VERSION ""

NS_ :

BS_:

BU_: DSAU vHS_M SHVU_RR DPSS AMP ICC RLPSM APSM RWPC RRHV RRPSM CGW_CCU APSS ATS RLHV FPM RDC PSM ASAU

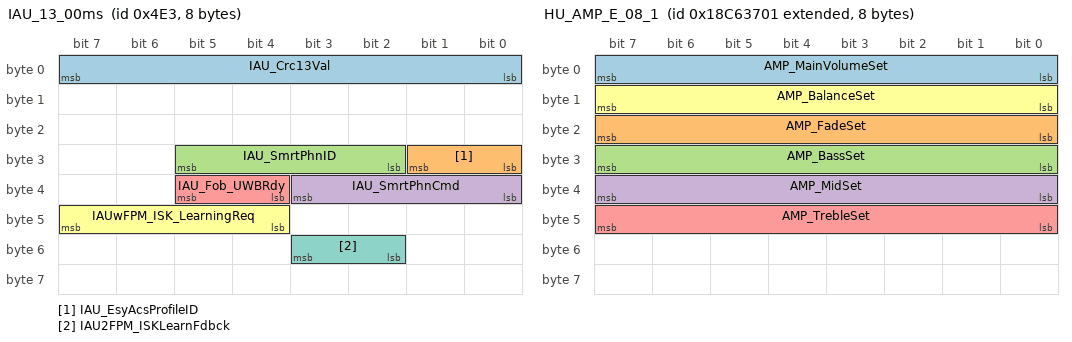
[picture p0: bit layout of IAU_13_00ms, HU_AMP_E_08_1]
BO_ 1251 IAU_13_00ms: 8 CGW_CCU
 SG_ IAU_Crc13Val : 0|8@1+ (1,0) [0|0] ""  Vector__XXX
 SG_ IAU_EsyAcsProfileID : 24|2@1+ (1,0) [0|0] ""  PSM
 SG_ IAU_SmrtPhnID : 26|4@1+ (1,0) [0|0] ""  Vector__XXX
 SG_ IAU_SmrtPhnCmd : 32|4@1+ (1,0) [0|0] ""  Vector__XXX
 SG_ IAU_Fob_UWBRdy : 36|2@1+ (1,0) [0|0] ""  Vector__XXX
 SG_ IAUwFPM_ISK_LearningReq : 44|4@1+ (1,0) [0|0] ""  FPM
 SG_ IAU2FPM_ISKLearnFdbck : 50|2@1+ (1,0) [0|0] ""  FPM

BO_ 2563127041 HU_AMP_E_08_1: 8 CGW_CCU
 SG_ AMP_MainVolumeSet : 0|8@1+ (1,0) [0|0] ""  AMP
 SG_ AMP_FadeSet : 16|8@1+ (1,0) [0|0] ""  AMP
 SG_ AMP_BassSet : 24|8@1+ (1,0) [0|0] ""  AMP
 SG_ AMP_MidSet : 32|8@1+ (1,0) [0|0] ""  AMP
 SG_ AMP_TrebleSet : 40|8@1+ (1,0) [0|0] ""  AMP
 SG_ AMP_BalanceSet : 8|8@1+ (1,0) [0|0] ""  AMP

BO_ 2567325441 HU_AMP_PE_01_1: 8 CGW_CCU
 SG_ AMP_ADASVolumeStep : 0|4@1+ (1,0) [0|0] ""  AMP
 SG_ AMP_ADASVolumeFbk : 4|4@1+ (1,0) [0|0] ""  AMP

BO_ 2298626561 HU_APSU_PE_03_1: 8 CGW_CCU
 SG_ C_RRLegSupFwdSw_HU : 0|2@1+ (1,0) [0|0] ""  RRPSM
 SG_ C_RRHrestDnSw_HU : 10|2@1+ (1,0) [0|0] ""  RRPSM
 SG_ C_RRHrestFwdSw_HU : 12|2@1+ (1,0) [0|0] ""  RRPSM
 SG_ C_RRHrestBwdSw_HU : 14|2@1+ (1,0) [0|0] ""  RRPSM
 SG_ C_RRLumbarUpSw_HU : 16|2@1+ (1,0) [0|0] ""  RLPSM
 SG_ C_RRLumbarMidSw_HU : 18|2@1+ (1,0) [0|0] ""  RLPSM
 SG_ C_RRLegSupBwdSw_HU : 2|2@1+ (1,0) [0|0] ""  RRPSM
 SG_ C_RRLumbarLowSw_HU : 20|2@1+ (1,0) [0|0] ""  RLPSM
 SG_ C_RRLumbarDefSw_HU : 22|2@1+ (1,0) [0|0] ""  RLPSM
 SG_ C_RRBolsterInfSw_HU : 24|2@1+ (1,0) [0|0] ""  RLPSM
 SG_ C_RRLegSupUpSw_HU : 4|2@1+ (1,0) [0|0] ""  RRPSM
 SG_ C_RROneTchNValueSet : 40|3@1+ (1,0) [0|0] ""  RLPSM,RRPSM,ATS
 SG_ C_RLOneTchNValueSet : 43|3@1+ (1,0) [0|0] ""  RLPSM,RRPSM,ATS
 SG_ C_RRBolsterDefSw_HU : 46|2@1+ (1,0) [0|0] ""  RLPSM
 SG_ C_RLRSEUpSw_HU : 54|2@1+ (1,0) [0|0] ""  PSM
 SG_ C_RLRSEDnSw_HU : 56|2@1+ (1,0) [0|0] ""  PSM
 SG_ C_RRRSEUpSw_HU : 58|2@1+ (1,0) [0|0] ""  APSM
 SG_ C_RRLegSupDnSw_HU : 6|2@1+ (1,0) [0|0] ""  RRPSM
 SG_ C_RRRSEDnSw_HU : 60|2@1+ (1,0) [0|0] ""  APSM
 SG_ C_RRHrestUpSw_HU : 8|2@1+ (1,0) [0|0] ""  RRPSM

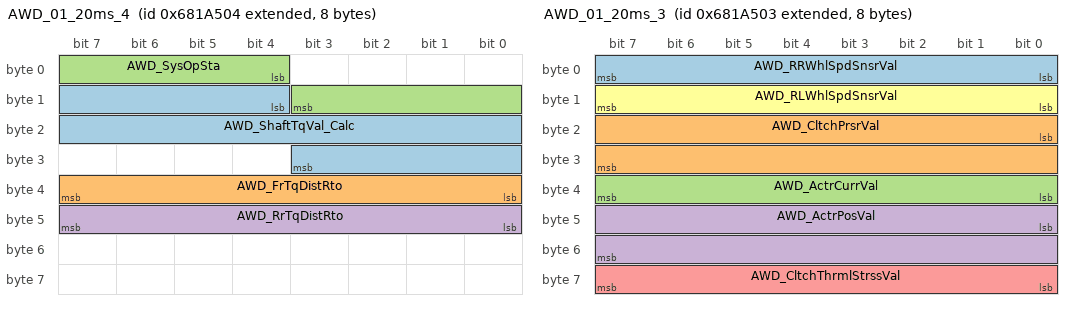
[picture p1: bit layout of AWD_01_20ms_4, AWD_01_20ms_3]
BO_ 2256643332 AWD_01_20ms_4: 8 CGW_CCU
 SG_ AWD_ShaftTqVal_Calc : 12|16@1+ (1,0) [0|0] "Nm"  Vector__XXX
 SG_ AWD_FrTqDistRto : 32|8@1+ (1,0) [0|0] "%"  Vector__XXX
 SG_ AWD_SysOpSta : 4|8@1+ (1,0) [0|0] ""  Vector__XXX
 SG_ AWD_RrTqDistRto : 40|8@1+ (1,0) [0|0] "%"  Vector__XXX

BO_ 2256643331 AWD_01_20ms_3: 8 CGW_CCU
 SG_ AWD_RRWhlSpdSnsrVal : 0|8@1+ (1,0) [0|0] "km/h"  Vector__XXX
 SG_ AWD_CltchPrsrVal : 16|16@1+ (0.0625,-50) [0|0] "Bar"  Vector__XXX
 SG_ AWD_ActrCurrVal : 32|8@1+ (0.390625,0) [0|0] "A"  Vector__XXX
 SG_ AWD_ActrPosVal : 40|16@1+ (0.015625,0) [0|0] "Deg"  Vector__XXX
 SG_ AWD_CltchThrmlStrssVal : 56|8@1+ (1,0) [0|0] "%"  Vector__XXX
 SG_ AWD_RLWhlSpdSnsrVal : 8|8@1+ (1,0) [0|0] "km/h"  Vector__XXX

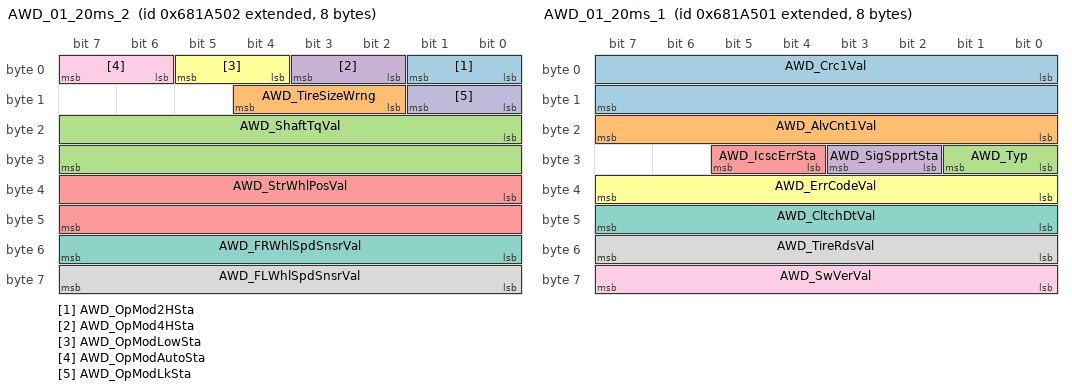
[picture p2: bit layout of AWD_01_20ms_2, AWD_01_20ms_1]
BO_ 2256643330 AWD_01_20ms_2: 8 CGW_CCU
 SG_ AWD_OpMod2HSta : 0|2@1+ (1,0) [0|0] ""  Vector__XXX
 SG_ AWD_TireSizeWrng : 10|3@1+ (1,0) [0|0] ""  Vector__XXX
 SG_ AWD_ShaftTqVal : 16|16@1+ (1,0) [0|0] "Nm"  Vector__XXX
 SG_ AWD_OpMod4HSta : 2|2@1+ (1,0) [0|0] ""  Vector__XXX
 SG_ AWD_StrWhlPosVal : 32|16@1+ (1,-600) [0|0] "Deg"  Vector__XXX
 SG_ AWD_OpModLowSta : 4|2@1+ (1,0) [0|0] ""  Vector__XXX
 SG_ AWD_FRWhlSpdSnsrVal : 48|8@1+ (1,0) [0|0] "km/h"  Vector__XXX
 SG_ AWD_FLWhlSpdSnsrVal : 56|8@1+ (1,0) [0|0] "km/h"  Vector__XXX
 SG_ AWD_OpModAutoSta : 6|2@1+ (1,0) [0|0] ""  Vector__XXX
 SG_ AWD_OpModLkSta : 8|2@1+ (1,0) [0|0] ""  Vector__XXX

BO_ 2256643329 AWD_01_20ms_1: 8 CGW_CCU
 SG_ AWD_Crc1Val : 0|16@1+ (1,0) [0|0] ""  Vector__XXX
 SG_ AWD_AlvCnt1Val : 16|8@1+ (1,0) [0|0] ""  Vector__XXX
 SG_ AWD_Typ : 24|2@1+ (1,0) [0|0] ""  AMP
 SG_ AWD_SigSpprtSta : 26|2@1+ (1,0) [0|0] ""  Vector__XXX
 SG_ AWD_IcscErrSta : 28|2@1+ (1,0) [0|0] ""  Vector__XXX
 SG_ AWD_ErrCodeVal : 32|8@1+ (1,0) [0|0] ""  Vector__XXX
 SG_ AWD_CltchDtVal : 40|8@1+ (1,0) [0|0] "%"  Vector__XXX
 SG_ AWD_TireRdsVal : 48|8@1+ (1,200) [0|0] "mm"  Vector__XXX
 SG_ AWD_SwVerVal : 56|8@1+ (1,0) [0|0] ""  Vector__XXX

BO_ 2458168321 HU_USM_E_05_1: 8 CGW_CCU
 SG_ C_HCIMSWeightNValueSet : 0|4@1+ (1,0) [0|0] ""  PSM
 SG_ C_HCIMSSitHeightNValueSet : 12|4@1+ (1,0) [0|0] ""  PSM
 SG_ CF_AVN_RRSeatAUTOHEATNValueSet : 16|2@1+ (1,0) [0|0] ""  Vector__XXX
 SG_ CF_AVN_RLSeatAUTOHEATNValueSet : 18|2@1+ (1,0) [0|0] ""  Vector__XXX
 SG_ CF_AVN_AstAUTOHEATNValueSet : 20|2@1+ (1,0) [0|0] ""  Vector__XXX
 SG_ CF_Avn_DrvAUTOHEATNValueSet : 22|2@1+ (1,0) [0|0] ""  Vector__XXX
 SG_ CF_AVN_BodySpprtSet : 24|2@1+ (1,0) [0|0] ""  DPSS,DSAU
 SG_ CF_AVN_EASMAUTOHEATNValueSet : 26|2@1+ (1,0) [0|0] ""  Vector__XXX
 SG_ CF_AVN_EDSMAUTOHEATNValueSet : 28|2@1+ (1,0) [0|0] ""  Vector__XXX
 SG_ CF_AVN_AntiDRWSYSet : 30|2@1+ (1,0) [0|0] ""  Vector__XXX
 SG_ CF_AVN_AirSptTimeNValueSet : 33|3@1+ (1,0) [0|0] ""  Vector__XXX
 SG_ CF_AVN_AirSptStrNValue : 36|2@1+ (1,0) [0|0] ""  Vector__XXX
 SG_ CF_AVN_SeatDrvModNValueSet : 38|2@1+ (1,0) [0|0] ""  DPSS,DSAU
 SG_ C_HCIMSHeightNvalueSet : 4|4@1+ (1,0) [0|0] ""  PSM
 SG_ C_SLB_SmartCtrl_NValue : 40|2@1+ (1,0) [0|0] ""  Vector__XXX
 SG_ CF_AVN_AntiDRWSYIntvlSet : 42|3@1+ (1,0) [0|0] ""  Vector__XXX
 SG_ CF_AVN_CushSoftNValueSet : 45|3@1+ (1,0) [0|0] ""  Vector__XXX
 SG_ C_SmrtSldngDrNValueSet : 48|3@1+ (1,0) [0|0] ""  Vector__XXX
 SG_ CF_AVN_TurboPressureUnit : 51|3@1+ (1,0) [0|0] ""  Vector__XXX
 SG_ CF_AVN_CluTorqueUnit : 54|2@1+ (1,0) [0|0] ""  Vector__XXX
 SG_ AVN_Usm_CluThemeAutoSet : 56|2@1+ (1,0) [0|0] ""  Vector__XXX
 SG_ AVN_Usm_CluThemeSta : 58|3@1+ (1,0) [0|0] ""  Vector__XXX
 SG_ AVN_Usm_CluFuelEconomySet : 61|3@1+ (1,0) [0|0] ""  Vector__XXX
 SG_ CF_AVN_HCIMSButtonCommand : 8|4@1+ (1,0) [0|0] ""  PSM

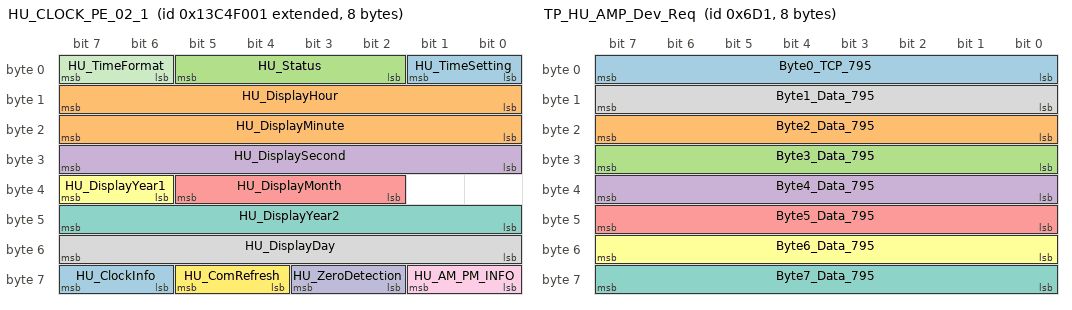
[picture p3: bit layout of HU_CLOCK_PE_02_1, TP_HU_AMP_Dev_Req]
BO_ 2479157249 HU_CLOCK_PE_02_1: 8 CGW_CCU
 SG_ HU_TimeSetting : 0|2@1+ (1,0) [0|0] ""  ATS
 SG_ HU_DisplayMinute : 16|8@1+ (1,0) [0|0] ""  ATS
 SG_ HU_Status : 2|4@1+ (1,0) [0|0] ""  ATS
 SG_ HU_DisplaySecond : 24|8@1+ (1,0) [0|0] ""  ATS
 SG_ HU_DisplayMonth : 34|4@1+ (1,0) [0|0] ""  ATS
 SG_ HU_DisplayYear1 : 38|2@1+ (1,0) [0|0] ""  ATS
 SG_ HU_DisplayYear2 : 40|8@1+ (1,0) [0|0] ""  ATS
 SG_ HU_DisplayDay : 48|8@1+ (1,0) [0|0] ""  ATS
 SG_ HU_AM_PM_INFO : 56|2@1+ (1,0) [0|0] ""  ATS
 SG_ HU_ZeroDetection : 58|2@1+ (1,0) [0|0] ""  ATS
 SG_ HU_TimeFormat : 6|2@1+ (1,0) [0|0] ""  ATS
 SG_ HU_ComRefresh : 60|2@1+ (1,0) [0|0] ""  ATS
 SG_ HU_ClockInfo : 62|2@1+ (1,0) [0|0] ""  ATS
 SG_ HU_DisplayHour : 8|8@1+ (1,0) [0|0] ""  ATS

BO_ 1745 TP_HU_AMP_Dev_Req: 8 CGW_CCU
 SG_ Byte0_TCP_795 : 0|8@1+ (1,0) [0|0] ""  AMP
 SG_ Byte2_Data_795 : 16|8@1+ (1,0) [0|0] ""  AMP
 SG_ Byte3_Data_795 : 24|8@1+ (1,0) [0|0] ""  AMP
 SG_ Byte4_Data_795 : 32|8@1+ (1,0) [0|0] ""  AMP
 SG_ Byte5_Data_795 : 40|8@1+ (1,0) [0|0] ""  AMP
 SG_ Byte6_Data_795 : 48|8@1+ (1,0) [0|0] ""  AMP
 SG_ Byte7_Data_795 : 56|8@1+ (1,0) [0|0] ""  AMP
 SG_ Byte1_Data_795 : 8|8@1+ (1,0) [0|0] ""  AMP

BO_ 191 RL_SHVU_03_200ms: 8 SHVU_RR
 SG_ RL_SHVU_DTCdisplay : 0|8@1+ (1,0) [0|0] ""  ATS
 SG_ RL_SHVU_DiagMode : 8|2@1+ (1,0) [0|0] ""  ATS

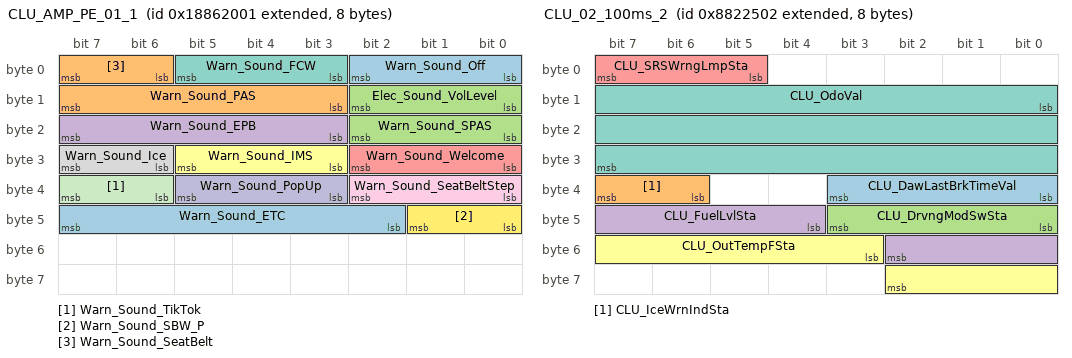
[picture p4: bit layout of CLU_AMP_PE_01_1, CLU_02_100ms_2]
BO_ 2558926849 CLU_AMP_PE_01_1: 8 CGW_CCU
 SG_ Warn_Sound_Off : 0|3@1+ (1,0) [0|0] ""  AMP
 SG_ Warn_Sound_PAS : 11|5@1+ (1,0) [0|0] ""  AMP
 SG_ Warn_Sound_SPAS : 16|3@1+ (1,0) [0|0] ""  AMP
 SG_ Warn_Sound_EPB : 19|5@1+ (1,0) [0|0] ""  AMP
 SG_ Warn_Sound_Welcome : 24|3@1+ (1,0) [0|0] ""  AMP
 SG_ Warn_Sound_IMS : 27|3@1+ (1,0) [0|0] ""  AMP
 SG_ Warn_Sound_FCW : 3|3@1+ (1,0) [0|0] ""  AMP
 SG_ Warn_Sound_Ice : 30|2@1+ (1,0) [0|0] ""  AMP
 SG_ Warn_Sound_SeatBeltStep : 32|3@1+ (1,0) [0|7] ""  AMP
 SG_ Warn_Sound_PopUp : 35|3@1+ (1,0) [0|0] ""  AMP
 SG_ Warn_Sound_TikTok : 38|2@1+ (1,0) [0|0] ""  AMP
 SG_ Warn_Sound_SBW_P : 40|2@1+ (1,0) [0|0] ""  AMP
 SG_ Warn_Sound_ETC : 42|6@1+ (1,0) [0|0] ""  AMP
 SG_ Warn_Sound_SeatBelt : 6|2@1+ (1,0) [0|0] ""  AMP
 SG_ Elec_Sound_VolLevel : 8|3@1+ (1,0) [0|0] ""  AMP

BO_ 2290230530 CLU_02_100ms_2: 8 CGW_CCU
 SG_ CLU_DawLastBrkTimeVal : 32|4@1+ (1,0) [0|0] ""  Vector__XXX
 SG_ CLU_IceWrnIndSta : 38|2@1+ (1,0) [0|0] ""  Vector__XXX
 SG_ CLU_DrvngModSwSta : 40|4@1+ (1,0) [0|0] ""  Vector__XXX
 SG_ CLU_FuelLvlSta : 44|7@1+ (1,0) [0|0] "%"  Vector__XXX
 SG_ CLU_SRSWrngLmpSta : 5|3@1+ (1,0) [0|0] ""  Vector__XXX
 SG_ CLU_OutTempFSta : 51|8@1+ (1,-40) [0|0] ""  ATS
 SG_ CLU_OdoVal : 8|24@1+ (0.1,0) [0|0] "km"  Vector__XXX

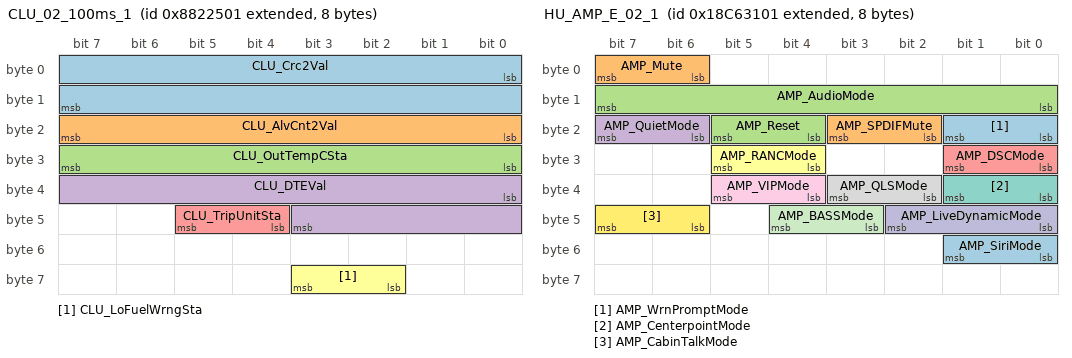
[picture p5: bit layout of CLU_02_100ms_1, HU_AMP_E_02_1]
BO_ 2290230529 CLU_02_100ms_1: 8 CGW_CCU
 SG_ CLU_Crc2Val : 0|16@1+ (1,0) [0|0] ""  Vector__XXX
 SG_ CLU_AlvCnt2Val : 16|8@1+ (1,0) [0|0] ""  Vector__XXX
 SG_ CLU_OutTempCSta : 24|8@1+ (1,-40) [0|0] ""  ATS
 SG_ CLU_DTEVal : 32|12@1+ (1,0) [0|0] ""  Vector__XXX
 SG_ CLU_TripUnitSta : 44|2@1+ (1,0) [0|0] ""  Vector__XXX
 SG_ CLU_LoFuelWrngSta : 58|2@1+ (1,0) [0|0] ""  Vector__XXX

BO_ 1153 IAU_39_00ms: 8 CGW_CCU
 SG_ IAU2FPM_EncryptedData2 : 0|64@1+ (1,0) [0|0] ""  FPM

BO_ 2323817473 HU_APSU_E_01_1: 8 CGW_CCU
 SG_ C_DrAirSptNValueSet_EC : 0|2@1+ (1,0) [0|0] ""  DSAU
 SG_ C_DrCushSoftNValueSet_EC : 11|3@1+ (1,0) [0|0] ""  DSAU
 SG_ C_AstAirSptNValueSet_EC : 14|2@1+ (1,0) [0|0] ""  ASAU
 SG_ C_DrBackSoftNValueSet_EC : 16|3@1+ (1,0) [0|0] ""  DSAU
 SG_ C_AstAirSptModeNValueSet_EC : 19|3@1+ (1,0) [0|0] ""  ASAU
 SG_ C_DrAirSptModeNValueSet_EC : 2|3@1+ (1,0) [0|0] ""  DSAU
 SG_ C_RLAirSptNValueSet_EC : 22|2@1+ (1,0) [0|0] ""  RLPSM,ATS
 SG_ C_AstAirSptStrNValueSet_EC : 24|3@1+ (1,0) [0|0] ""  ASAU
 SG_ C_AstAirSptTimeNValueSet_EC : 27|3@1+ (1,0) [0|0] ""  ASAU
 SG_ C_RRAirSptNValueSet_EC : 30|2@1+ (1,0) [0|0] ""  RLPSM,ATS
 SG_ C_AstCushSoftNValueSet_EC : 32|3@1+ (1,0) [0|0] ""  ASAU
 SG_ C_AstBackSoftNValueSet_EC : 35|3@1+ (1,0) [0|0] ""  ASAU
 SG_ C_RRFootAirSptNValueSet_EC : 38|2@1+ (1,0) [0|0] ""  RLPSM,ATS,ASAU
 SG_ C_RLAirSptModeNValueSet_EC : 43|3@1+ (1,0) [0|0] ""  RLPSM,ATS
 SG_ C_RLSeatHtOperNValueSet_EC : 48|4@1+ (1,0) [0|0] ""  RLHV
 SG_ C_DrAirSptStrNValueSet_EC : 5|3@1+ (1,0) [0|0] ""  DSAU
 SG_ C_RRSeatHtOperNValueSet_EC : 52|4@1+ (1,0) [0|0] ""  RRHV
 SG_ C_RLAirSptStrNValueSet_EC : 56|3@1+ (1,0) [0|0] ""  RLPSM,ATS
 SG_ C_RLAirSptTimeNValueSet_EC : 59|3@1+ (1,0) [0|0] ""  RLPSM,ATS
 SG_ C_DrAirSptTimeNValueSet_EC : 8|3@1+ (1,0) [0|0] ""  DSAU

BO_ 1156 IAU_42_00ms: 8 CGW_CCU
 SG_ IAU2FPM_RndNum : 16|48@1+ (1,0) [0|0] ""  FPM

BO_ 2563125505 HU_AMP_E_02_1: 8 CGW_CCU
 SG_ AMP_WrnPromptMode : 16|2@1+ (1,0) [0|0] ""  AMP
 SG_ AMP_SPDIFMute : 18|2@1+ (1,0) [0|0] ""  AMP
 SG_ AMP_Reset : 20|2@1+ (1,0) [0|0] ""  AMP
 SG_ AMP_QuietMode : 22|2@1+ (1,0) [0|0] ""  AMP
 SG_ AMP_DSCMode : 24|2@1+ (1,0) [0|0] ""  AMP
 SG_ AMP_RANCMode : 28|2@1+ (1,0) [0|0] ""  AMP
 SG_ AMP_CenterpointMode : 32|2@1+ (1,0) [0|0] ""  AMP
 SG_ AMP_QLSMode : 34|2@1+ (1,0) [0|0] ""  AMP
 SG_ AMP_VIPMode : 36|2@1+ (1,0) [0|0] ""  AMP
 SG_ AMP_LiveDynamicMode : 40|3@1+ (1,0) [0|0] ""  Vector__XXX
 SG_ AMP_BASSMode : 43|2@1+ (1,0) [0|0] ""  Vector__XXX
 SG_ AMP_CabinTalkMode : 46|2@1+ (1,0) [0|0] ""  Vector__XXX
 SG_ AMP_SiriMode : 48|2@1+ (1,0) [0|0] ""  AMP
 SG_ AMP_Mute : 6|2@1+ (1,0) [0|0] ""  AMP
 SG_ AMP_AudioMode : 8|8@1+ (1,0) [0|0] ""  AMP

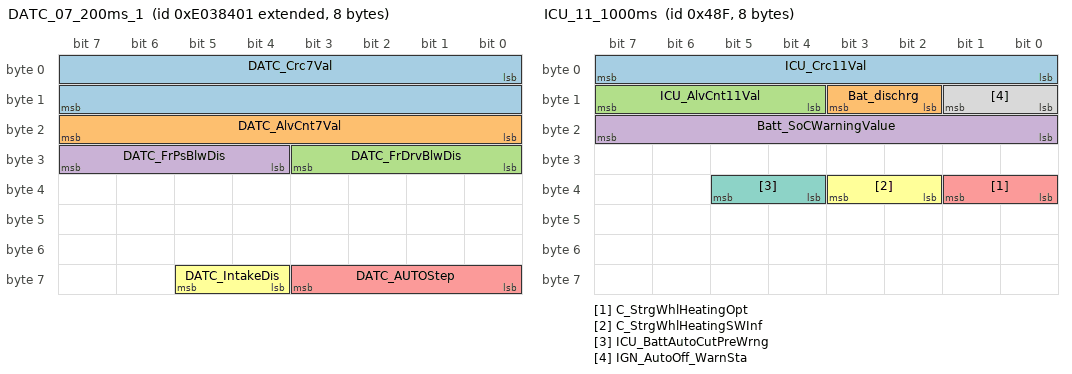
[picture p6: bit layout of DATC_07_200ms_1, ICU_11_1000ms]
BO_ 2382595073 DATC_07_200ms_1: 8 CGW_CCU
 SG_ DATC_Crc7Val : 0|16@1+ (1,0) [0|0] ""  Vector__XXX
 SG_ DATC_AlvCnt7Val : 16|8@1+ (1,0) [0|0] ""  Vector__XXX
 SG_ DATC_FrDrvBlwDis : 24|4@1+ (1,0) [0|0] ""  ATS
 SG_ DATC_FrPsBlwDis : 28|4@1+ (1,0) [0|0] ""  ATS
 SG_ DATC_AUTOStep : 56|4@1+ (1,0) [0|0] ""  Vector__XXX
 SG_ DATC_IntakeDis : 60|2@1+ (1,0) [0|0] ""  ATS

BO_ 1167 ICU_11_1000ms: 8 CGW_CCU
 SG_ ICU_Crc11Val : 0|8@1+ (1,0) [0|0] ""  vHS_M
 SG_ Bat_dischrg : 10|2@1+ (1,0) [0|0] ""  Vector__XXX
 SG_ ICU_AlvCnt11Val : 12|4@1+ (1,0) [0|0] ""  Vector__XXX
 SG_ Batt_SoCWarningValue : 16|8@1+ (1,0) [0|0] "%"  Vector__XXX
 SG_ C_StrgWhlHeatingOpt : 32|2@1+ (1,0) [0|0] ""  Vector__XXX
 SG_ C_StrgWhlHeatingSWInf : 34|2@1+ (1,0) [0|0] ""  Vector__XXX
 SG_ ICU_BattAutoCutPreWrng : 36|2@1+ (1,0) [0|0] ""  Vector__XXX
 SG_ IGN_AutoOff_WarnSta : 8|2@1+ (1,0) [0|0] ""  Vector__XXX

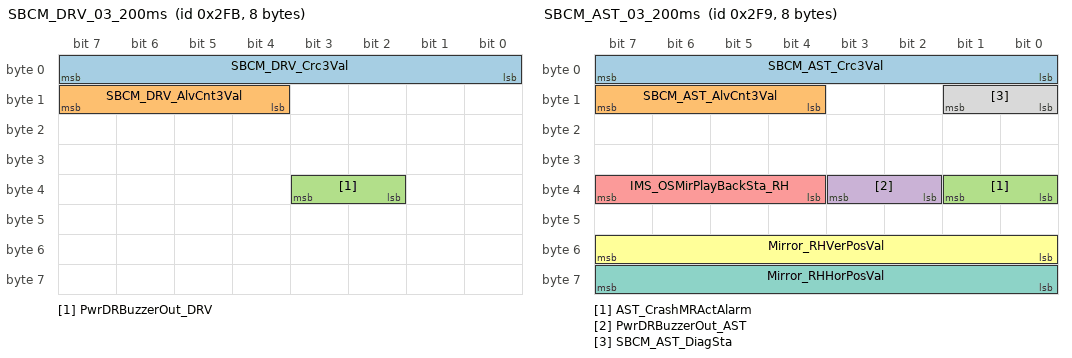
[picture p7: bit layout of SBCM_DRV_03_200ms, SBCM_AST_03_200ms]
BO_ 763 SBCM_DRV_03_200ms: 8 CGW_CCU
 SG_ SBCM_DRV_Crc3Val : 0|8@1+ (1,0) [0|0] ""  Vector__XXX
 SG_ SBCM_DRV_AlvCnt3Val : 12|4@1+ (1,0) [0|0] ""  Vector__XXX
 SG_ PwrDRBuzzerOut_DRV : 34|2@1+ (1,0) [0|0] ""  AMP

BO_ 760 SBCM_RR_02_200ms: 8 CGW_CCU
 SG_ RR_CrashMRActAlarm : 10|2@1+ (1,0) [0|0] ""  Vector__XXX
 SG_ PwrDRBuzzerOut_RR : 12|2@1+ (1,0) [0|0] ""  AMP

BO_ 761 SBCM_AST_03_200ms: 8 CGW_CCU
 SG_ SBCM_AST_Crc3Val : 0|8@1+ (1,0) [0|0] ""  Vector__XXX
 SG_ SBCM_AST_AlvCnt3Val : 12|4@1+ (1,0) [0|0] ""  Vector__XXX
 SG_ AST_CrashMRActAlarm : 32|2@1+ (1,0) [0|0] ""  Vector__XXX
 SG_ PwrDRBuzzerOut_AST : 34|2@1+ (1,0) [0|0] ""  AMP
 SG_ IMS_OSMirPlayBackSta_RH : 36|4@1+ (1,0) [0|0] ""  PSM
 SG_ Mirror_RHVerPosVal : 48|8@1+ (0.02,0) [0|0] "V"  Vector__XXX
 SG_ Mirror_RHHorPosVal : 56|8@1+ (0.02,0) [0|0] "V"  Vector__XXX
 SG_ SBCM_AST_DiagSta : 8|2@1+ (1,0) [0|0] ""  Vector__XXX

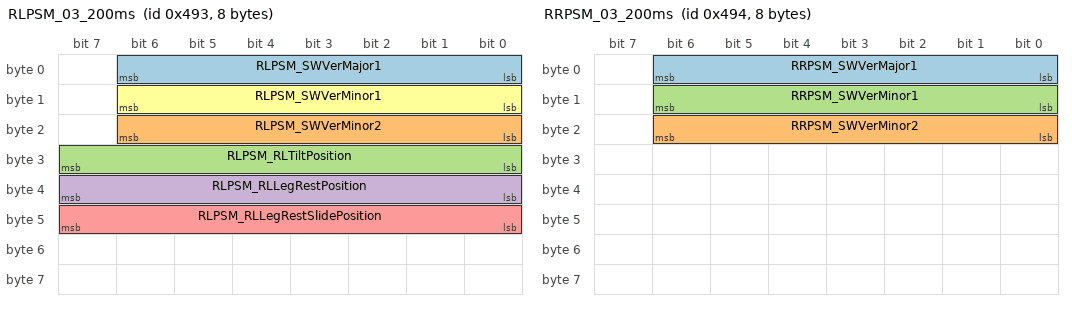
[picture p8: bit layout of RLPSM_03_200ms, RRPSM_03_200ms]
BO_ 1171 RLPSM_03_200ms: 8 RLPSM
 SG_ RLPSM_SWVerMajor1 : 0|7@1+ (1,0) [0|0] ""  CGW_CCU
 SG_ RLPSM_SWVerMinor2 : 16|7@1+ (1,0) [0|0] ""  CGW_CCU
 SG_ RLPSM_RLTiltPosition : 24|8@1+ (1,0) [0|0] ""  PSM
 SG_ RLPSM_RLLegRestPosition : 32|8@1+ (1,0) [0|0] ""  PSM
 SG_ RLPSM_RLLegRestSlidePosition : 40|8@1+ (1,0) [0|0] ""  PSM
 SG_ RLPSM_SWVerMinor1 : 8|7@1+ (1,0) [0|0] ""  CGW_CCU

BO_ 1172 RRPSM_03_200ms: 8 RRPSM
 SG_ RRPSM_SWVerMajor1 : 0|7@1+ (1,0) [0|0] ""  CGW_CCU
 SG_ RRPSM_SWVerMinor2 : 16|7@1+ (1,0) [0|0] ""  CGW_CCU
 SG_ RRPSM_SWVerMinor1 : 8|7@1+ (1,0) [0|0] ""  CGW_CCU

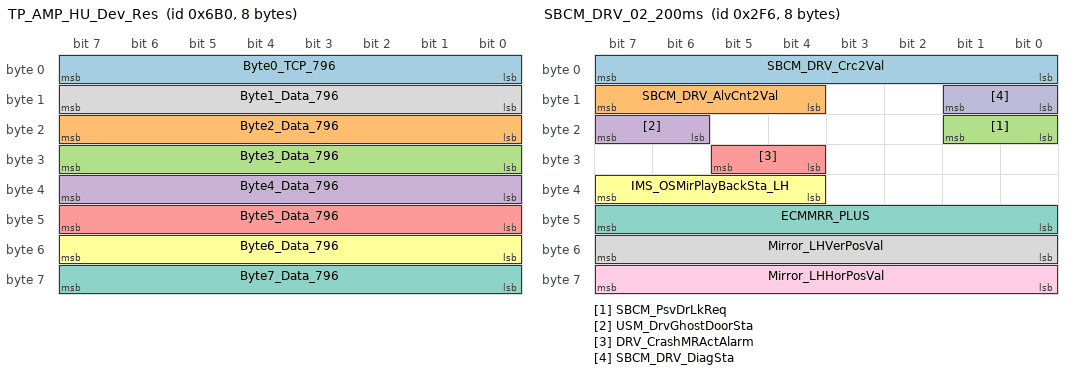
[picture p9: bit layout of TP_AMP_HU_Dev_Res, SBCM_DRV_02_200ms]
BO_ 1712 TP_AMP_HU_Dev_Res: 8 AMP
 SG_ Byte0_TCP_796 : 0|8@1+ (1,0) [0|0] ""  CGW_CCU
 SG_ Byte2_Data_796 : 16|8@1+ (1,0) [0|0] ""  CGW_CCU
 SG_ Byte3_Data_796 : 24|8@1+ (1,0) [0|0] ""  CGW_CCU
 SG_ Byte4_Data_796 : 32|8@1+ (1,0) [0|0] ""  CGW_CCU
 SG_ Byte5_Data_796 : 40|8@1+ (1,0) [0|0] ""  CGW_CCU
 SG_ Byte6_Data_796 : 48|8@1+ (1,0) [0|0] ""  CGW_CCU
 SG_ Byte7_Data_796 : 56|8@1+ (1,0) [0|0] ""  CGW_CCU
 SG_ Byte1_Data_796 : 8|8@1+ (1,0) [0|0] ""  CGW_CCU

BO_ 1174 Drv_SHVU_01_200ms: 8 PSM
 SG_ Drv_SHVU_SeatOptSta : 0|3@1+ (1,0) [0|0] ""  CGW_CCU
 SG_ Drv_SHVU_HtSwHiIndSta : 14|2@1+ (1,0) [0|0] ""  CGW_CCU
 SG_ Drv_SHVU_HtSwMidIndSta : 16|2@1+ (1,0) [0|0] ""  CGW_CCU
 SG_ Drv_SHVU_HtSwLowIndSta : 18|2@1+ (1,0) [0|0] ""  CGW_CCU
 SG_ Drv_SHVU_VntSwHiIndSta : 20|2@1+ (1,0) [0|0] ""  CGW_CCU
 SG_ Drv_SHVU_VntSwMidIndSta : 22|2@1+ (1,0) [0|0] ""  CGW_CCU
 SG_ Drv_SHVU_VntSwLowIndSta : 24|2@1+ (1,0) [0|0] ""  CGW_CCU
 SG_ Drv_SHVU_HtBlcUSMSta : 28|4@1+ (1,0) [0|0] ""  CGW_CCU
 SG_ Drv_SHVU_SeatHtOperSta : 3|4@1+ (1,0) [0|0] ""  CGW_CCU
 SG_ Drv_SHVU_SeatOptSta_RHD : 32|3@1+ (1,0) [0|0] ""  CGW_CCU
 SG_ Drv_SHVU_SeatHtOperSta_RHD : 35|4@1+ (1,0) [0|0] ""  CGW_CCU
 SG_ Drv_SHVU_HtSwHiIndSta_RHD : 46|2@1+ (1,0) [0|0] ""  CGW_CCU
 SG_ Drv_SHVU_HtSwMidIndSta_RHD : 48|2@1+ (1,0) [0|0] ""  CGW_CCU
 SG_ Drv_SHVU_HtSwLowIndSta_RHD : 50|2@1+ (1,0) [0|0] ""  CGW_CCU
 SG_ Drv_SHVU_VntSwHiIndSta_RHD : 52|2@1+ (1,0) [0|0] ""  CGW_CCU
 SG_ Drv_SHVU_VntSwMidIndSta_RHD : 54|2@1+ (1,0) [0|0] ""  CGW_CCU
 SG_ Drv_SHVU_VntSwLowIndSta_RHD : 56|2@1+ (1,0) [0|0] ""  CGW_CCU

BO_ 754 FPM_08_00ms: 8 FPM
 SG_ FPM2IAU_EncryptedData1 : 0|64@1+ (1,0) [0|0] ""  CGW_CCU

BO_ 755 FPM_09_00ms: 8 FPM
 SG_ FPM2IAU_EncryptedData2 : 0|64@1+ (1,0) [0|0] ""  CGW_CCU

BO_ 758 SBCM_DRV_02_200ms: 8 CGW_CCU
 SG_ SBCM_DRV_Crc2Val : 0|8@1+ (1,0) [0|0] ""  Vector__XXX
 SG_ SBCM_DRV_AlvCnt2Val : 12|4@1+ (1,0) [0|0] ""  Vector__XXX
 SG_ SBCM_PsvDrLkReq : 16|2@1+ (1,0) [0|0] ""  Vector__XXX
 SG_ USM_DrvGhostDoorSta : 22|2@1+ (1,0) [0|0] ""  Vector__XXX
 SG_ DRV_CrashMRActAlarm : 28|2@1+ (1,0) [0|0] ""  Vector__XXX
 SG_ IMS_OSMirPlayBackSta_LH : 36|4@1+ (1,0) [0|0] ""  PSM
 SG_ ECMMRR_PLUS : 40|8@1+ (1,0) [0|0] ""  Vector__XXX
 SG_ Mirror_LHVerPosVal : 48|8@1+ (0.02,0) [0|0] "V"  Vector__XXX
 SG_ Mirror_LHHorPosVal : 56|8@1+ (0.02,0) [0|0] "V"  Vector__XXX
 SG_ SBCM_DRV_DiagSta : 8|2@1+ (1,0) [0|0] ""  Vector__XXX

BO_ 208 RR_SHVU_03_200ms: 8 SHVU_RR
 SG_ RR_SHVU_DTCdisplay : 0|8@1+ (1,0) [0|0] ""  ATS
 SG_ RR_SHVU_DiagMode : 8|2@1+ (1,0) [0|0] ""  ATS

BO_ 759 SBCM_RL_02_200ms: 8 CGW_CCU
 SG_ RL_CrashMRActAlarm : 10|2@1+ (1,0) [0|0] ""  Vector__XXX
 SG_ PwrDRBuzzerOut_RL : 12|2@1+ (1,0) [0|0] ""  AMP

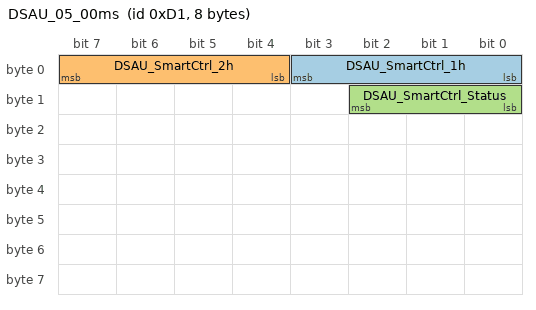
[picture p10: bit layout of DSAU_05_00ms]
BO_ 209 DSAU_05_00ms: 8 DSAU
 SG_ DSAU_SmartCtrl_1h : 0|4@1+ (1,0) [0|0] ""  CGW_CCU
 SG_ DSAU_SmartCtrl_2h : 4|4@1+ (1,0) [0|0] ""  CGW_CCU
 SG_ DSAU_SmartCtrl_Status : 8|3@1+ (1,0) [0|0] ""  CGW_CCU

BO_ 756 FPM_10_00ms: 8 FPM
 SG_ FPM_FOBSrch : 0|2@1+ (1,0) [0|0] ""  CGW_CCU
 SG_ FPM2IAU_RndNum : 16|48@1+ (1,0) [0|0] ""  CGW_CCU

BO_TX_BU_ 208 : SHVU_RR,RRHV;
BO_TX_BU_ 191 : SHVU_RR,RLHV;
CM_ BO_ 2256643329 "[P] Periodic";
CM_ SG_ 2256643329 AWD_Crc1Val "AWD_CyclicRedundancyCheck1Value";
CM_ SG_ 2256643329 AWD_AlvCnt1Val "AWD_AliveCounter1Value";
CM_ SG_ 2256643329 AWD_Typ "AWD_Type";
CM_ SG_ 2256643329 AWD_SigSpprtSta "AWD_SignalSupportingStatus";
CM_ SG_ 2256643329 AWD_IcscErrSta "Information indicating ICSC Signal";
CM_ SG_ 2256643329 AWD_ErrCodeVal "AWD_ErrorCodeValue";
CM_ SG_ 2256643329 AWD_CltchDtVal "AWD_ClutchDutyValue";
CM_ SG_ 2256643329 AWD_TireRdsVal "AWD_TireRadiusValue";
CM_ SG_ 2256643329 AWD_SwVerVal "AWD_SoftwareVersionValue";
CM_ BO_ 2256643330 "[P] Periodic";
CM_ SG_ 2256643330 AWD_OpMod2HSta "AWD_OperationMode2HStatus";
CM_ SG_ 2256643330 AWD_TireSizeWrng "Waring information the difference of front and rear wheel's dynamic radius";
CM_ SG_ 2256643330 AWD_ShaftTqVal "AWD_ShaftTorqueValue";
CM_ SG_ 2256643330 AWD_OpMod4HSta "AWD_OperationMode4HStatus";
CM_ SG_ 2256643330 AWD_StrWhlPosVal "AWD_SteeringWheelPositionValue";
CM_ SG_ 2256643330 AWD_OpModLowSta "AWD_OperationModeLowStatus";
CM_ SG_ 2256643330 AWD_FRWhlSpdSnsrVal "AWD_FrontRightWheelSpeedSensorValue";
CM_ SG_ 2256643330 AWD_FLWhlSpdSnsrVal "AWD_FrontLeftWheelSpeedSensorValue";
CM_ SG_ 2256643330 AWD_OpModAutoSta "AWD_OperationModeAutoStatus";
CM_ SG_ 2256643330 AWD_OpModLkSta "AWD_OperationModeLockStatus";
CM_ BO_ 2256643331 "[P] Periodic";
CM_ SG_ 2256643331 AWD_RRWhlSpdSnsrVal "AWD_RearRightWheelSpeedSensorValue";
CM_ SG_ 2256643331 AWD_CltchPrsrVal "AWD_ClutchPressureValue";
CM_ SG_ 2256643331 AWD_ActrCurrVal "AWD_ActuatorCurrentValue";
CM_ SG_ 2256643331 AWD_ActrPosVal "AWD_ActuatorPositionValue";
CM_ SG_ 2256643331 AWD_CltchThrmlStrssVal "AWD_ClutchThermalStressValue";
CM_ SG_ 2256643331 AWD_RLWhlSpdSnsrVal "AWD_RearLeftWheelSpeedSensorValue";
CM_ BO_ 2256643332 "[P] Periodic";
CM_ SG_ 2256643332 AWD_ShaftTqVal_Calc "AWD_ShaftTorqueValue_Calcualting";
CM_ SG_ 2256643332 AWD_FrTqDistRto "Torque Distribution ratio to Front Wheel";
CM_ SG_ 2256643332 AWD_SysOpSta "AWD_SystemOperationStatus";
CM_ SG_ 2256643332 AWD_RrTqDistRto "Torque Distribution ratio to Rear Wheel";
CM_ BO_ 2290230529 "[P] Periodic";
CM_ SG_ 2290230529 CLU_Crc2Val "CLU_CyclicRedundancyCheck2Value";
CM_ SG_ 2290230529 CLU_AlvCnt2Val "CLU_AliveCounter2Value";
CM_ SG_ 2290230529 CLU_OutTempCSta "CLU_DisplayOutsideTemperatureCStatus";
CM_ SG_ 2290230529 CLU_DTEVal "CLU_DTEValue";
CM_ SG_ 2290230529 CLU_TripUnitSta "CLU_TripUnitStatus";
CM_ SG_ 2290230529 CLU_LoFuelWrngSta "CLU_LowFuelWarningStatus";
CM_ BO_ 2290230530 "[P] Periodic";
CM_ SG_ 2290230530 CLU_DawLastBrkTimeVal "CLU_DawLastBreakTimeValue";
CM_ SG_ 2290230530 CLU_IceWrnIndSta "CLU_IceWarnIndicatorStatus";
CM_ SG_ 2290230530 CLU_DrvngModSwSta "CLU_DrivingModeSwitchStatus";
CM_ SG_ 2290230530 CLU_FuelLvlSta "CLU_FuelLevelStatus";
CM_ SG_ 2290230530 CLU_SRSWrngLmpSta "CLU_SRSWarningLampStatus";
CM_ SG_ 2290230530 CLU_OutTempFSta "CLU_DisplayOutsideTemperatureFStatus";
CM_ SG_ 2290230530 CLU_OdoVal "CLU_OdometerValue";
CM_ BO_ 2558926849 "[PE] Periodic and On Event";
CM_ SG_ 2558926849 Warn_Sound_Off "This signal is transmitted from cluster to AMP 3 group cluster sound

0x0:Off
0x1~0x6:Reserved
0x7:Invalid";
CM_ SG_ 2558926849 Warn_Sound_PAS "This signal is transmitted from cluster to AMP for 4 group cluster

0x0:Off
0x1:PAS Sensor Fail
0x2:PAS R Position
0x3~0x6:Reserved
0x7:Invalid";
CM_ SG_ 2558926849 Warn_Sound_SPAS "This signal transmitted from cluster to AMP for 6 group cluster sound

0x0:Off
0x1:SPAS Parking Complet
0x2:SPAS Scan Complete
0x3:SPAS System Abort
0x4:SPAS Gear Shift
0x5~0x6:Reserved
0x7:Invalid";
CM_ SG_ 2558926849 Warn_Sound_EPB "This signal is transmited from cluster to AMP for 5 group cluster sound

0x0:Off
0x1:Parking Brake Warning
0x2:EPB Uncomfort Alarm
0x3:Key Operated Warning
0x4:Vehicle Not P Warning
0x5:ESCL Not Lock Warning
0x6:Sunroof Open";
CM_ SG_ 2558926849 Warn_Sound_Welcome "This signal is transmitted from cluster to AMP for 9 group cluster sound";
CM_ SG_ 2558926849 Warn_Sound_IMS "This signal is transmitted from cluster to AMp for 8 group cluster sound

0x0:Off
0x1:ID Out
0x2:Deactivation ID Warning
0x3:IMS Buzzer
0x4~0x6:Reserved
0x7:Invalid";
CM_ SG_ 2558926849 Warn_Sound_FCW "This signal is transmitted from cluster to AMP for 2 group cluster sound

0x0:Off
0x1:TakeOverReq
0x2:OverSpeedWarning
0x3~0x6:Reserved
0x7:Invalid";
CM_ SG_ 2558926849 Warn_Sound_Ice "This signal is transmitted from cluster to AMP for 7 group cluster sound

0x0:Off
0x1:Ice Warning
0x2:Reserved
0x3:Invalid";
CM_ SG_ 2558926849 Warn_Sound_SeatBeltStep "This signal is used for control the Seatbelt Step Warning Buzzer function with 3 bits.
It provide pre-warning, 1st warning, 2nd warning, 3rd warning.";
CM_ SG_ 2558926849 Warn_Sound_PopUp "This signal is transmitted from cluster to AMP for 11 group cluster sound

0x0:Off
0x1:Red Pop-up(Collision)
0x2:Red Pop-up
0x3:Yellow Pop-up
0x4:White(Alarm) Pop-up
0x5:White(Feedback) Pop-up
0x6:Reserved
0x7:Invalid";
CM_ SG_ 2558926849 Warn_Sound_TikTok "This signal is transmitted from cluster to AMP for 10 group cluster sound

0x0:Off
0x1:Tick
0x2:Tock
0x3:Invalid";
CM_ SG_ 2558926849 Warn_Sound_SBW_P "This signal is transmitted from cluster to AMP

0x0:Off
0x1:SBW P
0x2:Reserved
0x3:Invalid";
CM_ SG_ 2558926849 Warn_Sound_ETC "This signal is transmitted from cluster to AMP for 12 group cluster sound

0x0:Off
0x1:Press_brake_to_start
0x2:reserved       
0x3:starrt_in_P_or_N   
0x4:Reserved
0x5:smart_cruise_mode
0x6:cruise_mode
0x7:step_on_brake_to_shift
0x8:park_only_possible_stop
0x9:move_lever_to_the_right
0xA:Align_handle
0xB:Reserved
0xC:fill_washer_fluid
0xD:door_open
0xE:hood_open
0xF:sunroof_open 
0x10:window_open
0x11:door_hood_open
0x12:windows_sunroof_open
0x13:Press_brake
0x14:volume1
0x15:volume2
0x16:volume3
0x17:WPCWarning
0x18~0x3E:Reserved
0x3F:Invalid               
0x14:volume1/0x15:volume2/0x16:volume3                           
0x17:WPCWarning
0x18~0x3E: Reserved/0x3F:Invalid'";
CM_ SG_ 2558926849 Warn_Sound_SeatBelt "The signal is transmitted from cluster to AMP for 1 group cluster sound

0x0:Off
0x1:Seat Belt
0x2:Reserved
0x3:Invalid";
CM_ SG_ 2558926849 Elec_Sound_VolLevel "0x0:Default
0x1:Level1
0x2:Level2
0x3:Level3
0x4~0x6:Reserved
0x7:Invalid";
CM_ BO_ 2382595073 "[PE] Periodic and On Event";
CM_ SG_ 2382595073 DATC_Crc7Val "DATC_CyclicRedundancyCheck7Value";
CM_ SG_ 2382595073 DATC_AlvCnt7Val "DATC_AliveCounter7Value";
CM_ SG_ 2382595073 DATC_FrDrvBlwDis "DATC_FrontDriverBlowerDisplay";
CM_ SG_ 2382595073 DATC_FrPsBlwDis "DATC_FrontPassengerBlowerDisplay";
CM_ SG_ 2382595073 DATC_AUTOStep "This signal indicates AUTO step status in case Multi Auto Blower type.";
CM_ SG_ 2382595073 DATC_IntakeDis "This signal indicates intake indicator & display";
CM_ BO_ 209 "[EC] On Event and On Change";
CM_ SG_ 209 DSAU_SmartCtrl_1h "스마트 자세제어 DSAU 연동 조절에 따른 개선현황 AVN 표시문구_1시간";
CM_ SG_ 209 DSAU_SmartCtrl_2h "스마트 자세제어 DSAU 연동 조절에 따른 개선현황 AVN 표시 문구_2시간";
CM_ SG_ 209 DSAU_SmartCtrl_Status "스마트 자세제어 2단계 DSAU 연동 조절 동작 시작 / 종료 / 중단 AVN 팝업";
CM_ BO_ 1174 "[PE] Periodic and On Event";
CM_ SG_ 1174 Drv_SHVU_SeatOptSta "Drv Seat Heater/Vent option info";
CM_ SG_ 1174 Drv_SHVU_HtSwHiIndSta "Drv Seat Heater Switch High Indicator Status";
CM_ SG_ 1174 Drv_SHVU_HtSwMidIndSta "Drv Seat Heater Switch Mid Indicator Status";
CM_ SG_ 1174 Drv_SHVU_HtSwLowIndSta "Drv Seat Heater Switch Low Indicator Status";
CM_ SG_ 1174 Drv_SHVU_VntSwHiIndSta "Drv Seat Vent Switch High Indicator Status";
CM_ SG_ 1174 Drv_SHVU_VntSwMidIndSta "Drv Seat Vent Switch Mid Indicator Status";
CM_ SG_ 1174 Drv_SHVU_VntSwLowIndSta "Drv Seat Vent Switch Low Indicator Status";
CM_ SG_ 1174 Drv_SHVU_HtBlcUSMSta "Hetaer Balance Driver USM R vaule";
CM_ SG_ 1174 Drv_SHVU_SeatHtOperSta "Drv Seat Heater/Vent current operation state";
CM_ SG_ 1174 Drv_SHVU_SeatOptSta_RHD "Drv Seat Heater/Vent option info(RHD)";
CM_ SG_ 1174 Drv_SHVU_SeatHtOperSta_RHD "Drv Seat Heater/Vent current operation state(RHD)";
CM_ SG_ 1174 Drv_SHVU_HtSwHiIndSta_RHD "Drv Seat Heater Switch High Indicator Status(RHD)";
CM_ SG_ 1174 Drv_SHVU_HtSwMidIndSta_RHD "Drv Seat Heater Switch Mid Indicator Status(RHD)";
CM_ SG_ 1174 Drv_SHVU_HtSwLowIndSta_RHD "Drv Seat Heater Switch Low Indicator Status(RHD)";
CM_ SG_ 1174 Drv_SHVU_VntSwHiIndSta_RHD "Drv Seat Vent Switch High Indicator Status(RHD)";
CM_ SG_ 1174 Drv_SHVU_VntSwMidIndSta_RHD "Drv Seat Vent Switch Mid Indicator Status(RHD)";
CM_ SG_ 1174 Drv_SHVU_VntSwLowIndSta_RHD "Drv Seat Vent Switch Low Indicator Status(RHD)";
CM_ BO_ 754 "[EC] On Event and On Change";
CM_ SG_ 754 FPM2IAU_EncryptedData1 "This signal is for a send enrypted result of FPM.";
CM_ BO_ 755 "[EC] On Event and On Change";
CM_ BO_ 756 "[EC] On Event and On Change";
CM_ SG_ 756 FPM2IAU_RndNum "FPM Random Number";
CM_ BO_ 2563125505 "[EC] On Event and On Change";
CM_ SG_ 2563125505 AMP_SPDIFMute "SPDIF sound mute
(Navi sound is controlled by AMP_Mute)";
CM_ SG_ 2563125505 AMP_Reset "Command for external amp reinitiation process";
CM_ SG_ 2563125505 AMP_QuietMode "Send signal 'Quiet Mode On/Off' from H/U to AMP";
CM_ SG_ 2563125505 AMP_DSCMode "Turn Dynamic Speed Compensation ON/OFF";
CM_ SG_ 2563125505 AMP_RANCMode "Turn RANC On/Off";
CM_ SG_ 2563125505 AMP_CenterpointMode "Turn CenterPoint ON/OFF";
CM_ SG_ 2563125505 AMP_QLSMode "Turn QLS(Quantum Logic Surround) ON/OFF
For Harman
* For Mobis Leacgy AMP, Use AMP_SurroundMode Instead
* For Mobis KRELL AMP, Use AMP_LiveDynamicMode Instead";
CM_ SG_ 2563125505 AMP_VIPMode "Turn VIP mode ON/OFF
For Harman AMP (for D+ segment vehicle)";
CM_ SG_ 2563125505 AMP_LiveDynamicMode "Turn Live Dynamic On/Off";
CM_ SG_ 2563125505 AMP_BASSMode "Signal for loading EQ value to the AMP";
CM_ SG_ 2563125505 AMP_CabinTalkMode "Send signal 'CabinTalk On/Off' from H/U to AMP";
CM_ SG_ 2563125505 AMP_SiriMode "Send Signal 'Siri Mode On/Off' from HU to AMP";
CM_ SG_ 2563125505 AMP_Mute "Mute all speakers";
CM_ SG_ 2563125505 AMP_AudioMode "Information for Current audio mode for EQ selection
-This Signal's Feedback is AMP_AudioSource(0x181)@AMP";
CM_ BO_ 2563127041 "[EC] On Event and On Change";
CM_ SG_ 2563127041 AMP_MainVolumeSet "Command for Main Audio Volume Setting
-range : 0 ~ max
-max : value of AMP_MaxVolumeStep(0x085)
-This Signal's Feedback is AMP_MainVolumeSetting(0x183)@AMP";
CM_ SG_ 2563127041 AMP_FadeSet "Command for Front/Rear Audio Fade Setting
-range : 0 ~ max
-max : value of AMP_MaxFadeStep
-This Signal's Feedback is AMP_FadeSetting(0x183)@AMP";
CM_ SG_ 2563127041 AMP_BassSet "Command for Bass Tone Control Setting
-range : 0 ~ max
-max : value of AMP_MaxBassStep(0x085)
-This Signal's Feedback is AMP_BassSetting(0x183)@AMP";
CM_ SG_ 2563127041 AMP_MidSet "Command for Mid-range Tone Control Setting
-range : 0 ~ max
-max : value of AMP_MaxMidStep(0x085)
-This Signal's Feedback is AMP_MidSetting(0x183)@AMP";
CM_ SG_ 2563127041 AMP_TrebleSet "Command for Treble Tone Control Setting
-range : 0 ~ max
-max : value of AMP_MaxTrebleStep(0x085)
-This Signal's Feedback is AMP_TrebleSetting(0x183)@AMP";
CM_ SG_ 2563127041 AMP_BalanceSet "Command for Left/Right Audio Balance Setting
-range : 0 ~ max
-max : value of AMP_MaxBalanceStep(0x085)
-This Signal's Feedback is AMP_BalanceSetting(0x183)@AMP";
CM_ BO_ 2567325441 "[PE] Periodic and On Event";
CM_ BO_ 2323817473 "[EC] On Event and On Change";
CM_ SG_ 2323817473 C_DrAirSptNValueSet_EC "Driver Seat Smart Air Support On/Off";
CM_ SG_ 2323817473 C_DrCushSoftNValueSet_EC "Driver Seat Cushion Softness";
CM_ SG_ 2323817473 C_AstAirSptNValueSet_EC "Assistant Seat Smart Air Support On/Off";
CM_ SG_ 2323817473 C_DrBackSoftNValueSet_EC "Driver Seat Back Softness";
CM_ SG_ 2323817473 C_AstAirSptModeNValueSet_EC "Assistant Seat Smart Air Support Mode";
CM_ SG_ 2323817473 C_DrAirSptModeNValueSet_EC "Driver Seat Smart Air Support Mode";
CM_ SG_ 2323817473 C_RLAirSptNValueSet_EC "2nd Left Seat Smart Air Support On/Off";
CM_ SG_ 2323817473 C_AstAirSptStrNValueSet_EC "Assistant Seat Smart Air Support Strength";
CM_ SG_ 2323817473 C_AstAirSptTimeNValueSet_EC "Assistant Seat Smart Air Support Time";
CM_ SG_ 2323817473 C_RRAirSptNValueSet_EC "2nd Right side seat Smart Air Support On/Off";
CM_ SG_ 2323817473 C_AstCushSoftNValueSet_EC "Assistant Seat Cushion Softness off/low/mid/high";
CM_ SG_ 2323817473 C_AstBackSoftNValueSet_EC "Assistant Seat Back Softness Off/Low/Mid/High";
CM_ SG_ 2323817473 C_RRFootAirSptNValueSet_EC "2nd Right side seat Foot Air Support On/Off";
CM_ SG_ 2323817473 C_RLAirSptModeNValueSet_EC "2nd Left Seat Smart Air Support Mode";
CM_ SG_ 2323817473 C_RLSeatHtOperNValueSet_EC "2nd Left side seat Heating/Ventilation switch: Vent low/mid/high, Heater low/mid/high";
CM_ SG_ 2323817473 C_DrAirSptStrNValueSet_EC "Driver Seat Smart Air Support Strength";
CM_ SG_ 2323817473 C_RRSeatHtOperNValueSet_EC "2nd Right side seat Heating/Ventilation switch: Vent low, Vent Mid, Vent High , Heater Low, Heater Mid, Heater High";
CM_ SG_ 2323817473 C_RLAirSptStrNValueSet_EC "2nd Left Seat Smart Air Support Strength";
CM_ SG_ 2323817473 C_RLAirSptTimeNValueSet_EC "2nd Left Seat Smart Air Support Time";
CM_ SG_ 2323817473 C_DrAirSptTimeNValueSet_EC "Driver Seat Smart Air Support Time";
CM_ BO_ 2298626561 "[PE] Periodic and On Event";
CM_ SG_ 2298626561 C_RRLegSupFwdSw_HU "2nd Right side seat Moving control : Leg Support Forward";
CM_ SG_ 2298626561 C_RRHrestDnSw_HU "2nd Right side seat Moving control : Headrest Down";
CM_ SG_ 2298626561 C_RRHrestFwdSw_HU "2nd Right side seat Moving control : Headrest Forward";
CM_ SG_ 2298626561 C_RRHrestBwdSw_HU "2nd Right side seat Moving control : Headrest Backward";
CM_ SG_ 2298626561 C_RRLumbarUpSw_HU "2nd Right side seat Moving control : Lumbar Up";
CM_ SG_ 2298626561 C_RRLumbarMidSw_HU "2nd Right side seat Moving control : Lumbar Mid";
CM_ SG_ 2298626561 C_RRLegSupBwdSw_HU "2nd Right side seat Moving control : Leg Support Backward";
CM_ SG_ 2298626561 C_RRLumbarLowSw_HU "2nd Right side seat Moving control : Lumbar Low";
CM_ SG_ 2298626561 C_RRLumbarDefSw_HU "2nd Right side seat Moving control : Lumbar Deflate";
CM_ SG_ 2298626561 C_RRBolsterInfSw_HU "2nd Right side seat Moving control : Bolster Inflate";
CM_ SG_ 2298626561 C_RRLegSupUpSw_HU "2nd Right side seat Moving control : Leg Support Up";
CM_ SG_ 2298626561 C_RROneTchNValueSet "2nd Right side seat One Touch Mode";
CM_ SG_ 2298626561 C_RLOneTchNValueSet "2nd Left side seat One Touch Mode";
CM_ SG_ 2298626561 C_RRBolsterDefSw_HU "2nd Right side seat Moving control : Bolster Deflate";
CM_ SG_ 2298626561 C_RLRSEUpSw_HU "2nd Left side seat Moving control : RSE Up";
CM_ SG_ 2298626561 C_RLRSEDnSw_HU "2nd Left side seat Moving control : RSE Down";
CM_ SG_ 2298626561 C_RRRSEUpSw_HU "2nd Right side seat Moving control : RSE Up";
CM_ SG_ 2298626561 C_RRLegSupDnSw_HU "2nd Right side seat Moving control : Leg Support Down";
CM_ SG_ 2298626561 C_RRRSEDnSw_HU "2nd Right side seat Moving control : RSE Down";
CM_ SG_ 2298626561 C_RRHrestUpSw_HU "2nd Right side seat Moving control : Headrest Up";
CM_ BO_ 2479157249 "[PE] Periodic and On Event";
CM_ SG_ 2479157249 HU_TimeSetting "Information for current time setting";
CM_ SG_ 2479157249 HU_DisplayMinute "Information for time display in Minute unit";
CM_ SG_ 2479157249 HU_Status "Information for H/U status
Transmitted on H/U status changing";
CM_ SG_ 2479157249 HU_DisplaySecond "Information for time display in Second unit";
CM_ SG_ 2479157249 HU_DisplayMonth "Information for Month";
CM_ SG_ 2479157249 HU_DisplayYear1 "Information for Year (XXOO)
XX : HU_DisplayYear1
OO: HU_DisplayYear2";
CM_ SG_ 2479157249 HU_DisplayYear2 "Information for Year (XXOO)
XX : HU_DisplayYear1
OO: HU_DisplayYear2";
CM_ SG_ 2479157249 HU_DisplayDay "Information for Day";
CM_ SG_ 2479157249 HU_AM_PM_INFO "Information for AM/PM";
CM_ SG_ 2479157249 HU_ZeroDetection "Request zero detction to Analog Clock";
CM_ SG_ 2479157249 HU_TimeFormat "Information for time format
Digital CLOCK only";
CM_ SG_ 2479157249 HU_DisplayHour "Information for time display in Hour unit";
CM_ BO_ 2458168321 "[EC] On Event and On Change";
CM_ SG_ 2458168321 C_HCIMSWeightNValueSet "This signal is used for Healthcare IMS to input user's weight";
CM_ SG_ 2458168321 C_HCIMSSitHeightNValueSet "This signal is used for Healthcare IMS to input user's sitting height";
CM_ SG_ 2458168321 CF_AVN_RRSeatAUTOHEATNValueSet "Request for auto down rear right seat heater (USM setting)";
CM_ SG_ 2458168321 CF_AVN_RLSeatAUTOHEATNValueSet "Request for auto down rear left seat heater (USM setting)";
CM_ SG_ 2458168321 CF_AVN_AstAUTOHEATNValueSet "Request for auto down assistant seat heater : APSM option (USM setting)";
CM_ SG_ 2458168321 CF_Avn_DrvAUTOHEATNValueSet "Request for auto down driver seat heater : PSM option (USM setting)";
CM_ SG_ 2458168321 CF_AVN_BodySpprtSet "This signal is for the seat body support USM";
CM_ SG_ 2458168321 CF_AVN_EASMAUTOHEATNValueSet "Request for auto down assistant driver seat heater : EASM option (USM setting)";
CM_ SG_ 2458168321 CF_AVN_EDSMAUTOHEATNValueSet "Request for auto down driver seat heater : EDSM option (USM setting)";
CM_ SG_ 2458168321 CF_AVN_AntiDRWSYSet "This signal is for the anti drowsy system USM";
CM_ SG_ 2458168321 CF_AVN_AirSptTimeNValueSet "This signal is for the seat massage function time setting";
CM_ SG_ 2458168321 CF_AVN_AirSptStrNValue "This signal is for the seat massage intensity USM";
CM_ SG_ 2458168321 CF_AVN_SeatDrvModNValueSet "This signal is for the auto seat-drivemode user setting menu";
CM_ SG_ 2458168321 C_HCIMSHeightNvalueSet "This signal is used for Healthcare IMS to input user's height";
CM_ SG_ 2458168321 CF_AVN_AntiDRWSYIntvlSet "This signal is for the anti drowsy system operation interval setting USM";
CM_ SG_ 2458168321 CF_AVN_CushSoftNValueSet "This signal is for the cushsoftness setting";
CM_ SG_ 2458168321 AVN_Usm_CluFuelEconomySet "RG3 이후 대화면 클러스터 적용시 본 사양으로 평균연비 자동 초기화 기능 적용";
CM_ SG_ 2458168321 CF_AVN_HCIMSButtonCommand "User's input value in healthcare IMS mode";
CM_ BO_ 1251 "[EC] On Event and On Change";
CM_ SG_ 1251 IAU_Crc13Val "IAU_CyclicRedundancyCheck13Value";
CM_ SG_ 1251 IAU_Fob_UWBRdy "Feedback of Fob_UWBRngAreaCmd, Fob_UWBRngID";
CM_ BO_ 1153 "[EC] On Event and On Change";
CM_ SG_ 1153 IAU2FPM_EncryptedData2 "This signal is for a send enrypted result of IAU.";
CM_ BO_ 1156 "[EC] On Event and On Change";
CM_ SG_ 1156 IAU2FPM_RndNum "IAU to FPM Random Number";
CM_ BO_ 1167 "[PE] Periodic and On Event";
CM_ SG_ 1167 ICU_Crc11Val "ICU_CyclicRedundancyCheck11Value";
CM_ SG_ 1167 Bat_dischrg "Battery discharge notification flag #2G# Bat_dischrg";
CM_ SG_ 1167 ICU_AlvCnt11Val "ICU_AliveCounter11Value";
CM_ SG_ 1167 Batt_SoCWarningValue "Value of SoC warning level. ##2G## -  - Batt_SoCWarningValue";
CM_ SG_ 1167 ICU_BattAutoCutPreWrng "This is a warning signal before blocking the dark current of the ICU by the battery SOC.";
CM_ SG_ 1167 IGN_AutoOff_WarnSta "this signal is defined as the warning signal related with battery discharge";
CM_ BO_ 1171 "[PE] Periodic and On Event";
CM_ SG_ 1171 RLPSM_SWVerMajor1 "First Word(ASCII) in RLPSM S/W Ver";
CM_ SG_ 1171 RLPSM_SWVerMinor2 "Third Word(ASCII) in RLPSM S/W Ver";
CM_ SG_ 1171 RLPSM_SWVerMinor1 "Second Word(ASCII) in RLPSM S/W Ver";
CM_ BO_ 191 "[PE] Periodic and On Event";
CM_ SG_ 191 RL_SHVU_DTCdisplay "0x00: DTC is not exist(Fail is not exist)/0x01:IGN2 Fuse Open Detection/0x02:Switch Input Detection at Same Time/0x03:NTC/Heating wire Open Detection/0x04:NTC+/NTC- Terminal Short Detection/0x05:NTC+/Heater+ Terminal Short Detection/0x06:NTC+/Heater-, Heater+/Heater-, Heater+/NTC- Terminal Short Detection/0x07:NTC+/Heater- Wiring Short Detection/0x08:NTC+/Heater-, Heater+/Heater-, Heater+/NTC- Wiring Short Detection/0x09:Target Temperature Dissatisfied/0x0A:Blower+/Blower- Short, Blower+/Blower Speed, Blower-/Blower Speed Wiring Short Detection/0x0B:Blower+/Blower RPM, Blower-/Blower RPM, Blower Speed/Blower RPM Short Detection/0x0C:Blower+, Blower-, Blower Speed Signal open Detection/0x0D:Blower RPM signal Open Detection/0x0E~0xFD:Unused/0xFE:No Display/0xFF:Invalid";
CM_ SG_ 191 RL_SHVU_DiagMode "0x0:Default/0x1:DTC Mode/0x2:Normal Mode/0x3:Invalid";
CM_ BO_ 1172 "[PE] Periodic and On Event";
CM_ SG_ 1172 RRPSM_SWVerMajor1 "First Word(ASCII) in RRPSM S/W Ver";
CM_ SG_ 1172 RRPSM_SWVerMinor2 "Third Word(ASCII) in RRPSM S/W Ver";
CM_ SG_ 1172 RRPSM_SWVerMinor1 "Second Word(ASCII) in RRPSM S/W Ver";
CM_ BO_ 208 "[PE] Periodic and On Event";
CM_ SG_ 208 RR_SHVU_DTCdisplay "0x00: DTC is not exist(Fail is not exist)/0x01:IGN2 Fuse Open Detection/0x02:Switch Input Detection at Same Time/0x03:NTC/Heating wire Open Detection/0x04:NTC+/NTC- Terminal Short Detection/0x05:NTC+/Heater+ Terminal Short Detection/0x06:NTC+/Heater-, Heater+/Heater-, Heater+/NTC- Terminal Short Detection/0x07:NTC+/Heater- Wiring Short Detection/0x08:NTC+/Heater-, Heater+/Heater-, Heater+/NTC- Wiring Short Detection/0x09:Target Temperature Dissatisfied/0x0A:Blower+/Blower- Short, Blower+/Blower Speed, Blower-/Blower Speed Wiring Short Detection/0x0B:Blower+/Blower RPM, Blower-/Blower RPM, Blower Speed/Blower RPM Short Detection/0x0C:Blower+, Blower-, Blower Speed Signal open Detection/0x0D:Blower RPM signal Open Detection/0x0E~0xFD:Unused/0xFE:No Display/0xFF:Invalid";
CM_ SG_ 208 RR_SHVU_DiagMode "0x0:Default/0x1:DTC Mode/0x2:Normal Mode/0x3:Invalid";
CM_ BO_ 761 "[PE] Periodic and On Event";
CM_ SG_ 761 SBCM_AST_Crc3Val "SBCM_AST_CyclicRedundancyCheck3Value";
CM_ SG_ 761 SBCM_AST_AlvCnt3Val "SBCM_AST_AliveCounter3Value";
CM_ SG_ 761 Mirror_RHVerPosVal "RH Outside Mirror Vertical Position sensor value";
CM_ SG_ 761 Mirror_RHHorPosVal "RH Outside Mirror Horizontal Position sensor value";
CM_ BO_ 758 "[PE] Periodic and On Event";
CM_ SG_ 758 SBCM_DRV_Crc2Val "SBCM_DRV_CyclicRedundancyCheck2Value";
CM_ SG_ 758 SBCM_DRV_AlvCnt2Val "SBCM_DRV_AliveCounter2Value";
CM_ SG_ 758 ECMMRR_PLUS "ECM Voltage value";
CM_ SG_ 758 Mirror_LHVerPosVal "LH Outside Mirror Vertical Position sensor value";
CM_ SG_ 758 Mirror_LHHorPosVal "LH Outside Mirror Horizontal Position Sensor Voltage";
CM_ BO_ 763 "[PE] Periodic and On Event";
CM_ SG_ 763 SBCM_DRV_Crc3Val "SBCM_DRV_CyclicRedundancyCheck3Value";
CM_ SG_ 763 SBCM_DRV_AlvCnt3Val "SBCM_DRV_AliveCounter3Value";
CM_ BO_ 759 "[PE] Periodic and On Event";
CM_ BO_ 760 "[PE] Periodic and On Event";
CM_ BO_ 1712 "[TP] Transport Protocol";
CM_ BO_ 1745 "[TP] Transport Protocol";
CM_ SG_ 1745 Byte0_TCP_795 "AMP";
CM_ SG_ 1745 Byte2_Data_795 "AMP";
CM_ SG_ 1745 Byte3_Data_795 "AMP";
CM_ SG_ 1745 Byte4_Data_795 "AMP";
CM_ SG_ 1745 Byte5_Data_795 "AMP";
CM_ SG_ 1745 Byte6_Data_795 "AMP";
CM_ SG_ 1745 Byte7_Data_795 "AMP";
CM_ SG_ 1745 Byte1_Data_795 "AMP";
BA_DEF_ BO_ "DiagState" ENUM "No","Yes" ;
BA_DEF_ BO_ "DiagResponse" ENUM "No","Yes" ;
BA_DEF_ BO_ "DiagRequest" ENUM "No","Yes" ;
BA_DEF_ BO_ "TpMessage" ENUM "No","Yes" ;
BA_DEF_ BO_ "UsrMsgIDSforwardDeviation" INT 0 100 ;
BA_DEF_ BO_ "UsrMsgIDSbackwardDeviation" INT 50 1000 ;
BA_DEF_ BO_ "GenMsgCycleTime" INT 0 2000 ;
BA_DEF_ BO_ "GenMsgStartDelayTime" INT 0 2000 ;
BA_DEF_ BO_ "GenMsgSendType" ENUM "Cyclic","NoMsgSendType" ;
BA_DEF_ BO_ "GenMsgCycleTimeFast" INT 0 500 ;
BA_DEF_ BO_ "GenMsgDelayTime" INT 0 20 ;
BA_DEF_ BO_ "GenMsgILSupport" ENUM "No","Yes" ;
BA_DEF_ BO_ "GenMsgNrOfRepetition" INT 0 3 ;
BA_DEF_ BO_ "NmMessage" ENUM "No","Yes" ;
BA_DEF_ BO_ "NWM-Botschaft" ENUM "No","Yes" ;
BA_DEF_ BO_ "TpTxIndex" INT 0 255 ;
BA_DEF_ BO_ "VFrameFormat" ENUM "StandardCAN","ExtendedCAN","reserved","reserved","reserved","reserved","reserved","reserved","reserved","reserved","reserved","reserved","reserved","reserved","StandardCAN_FD","ExtendedCAN_FD" ;
BA_DEF_ SG_ "UserSigValidity" ENUM "B+","ACC","IG","IG1","IG2","IG3","IG1 or IG2","IG1 or IG3","Undef" ;
BA_DEF_ SG_ "TimeoutValue" STRING ;
BA_DEF_ SG_ "UsrSigPurpose" ENUM "Undef","FN","DIAG","DIAG(Req)","DIAG(Res)","DIAG(Phy)","DEV","CCP(Req)","CCP(Res)","NM","TP" ;
BA_DEF_ SG_ "GenSigStartValue" INT 0 1215752192 ;
BA_DEF_ SG_ "NetworkRequest" ENUM "Yes","No" ;
BA_DEF_ SG_ "NetworkRequestHoldingTime" INT 0 65535 ;
BA_DEF_ SG_ "Description" STRING ;
BA_DEF_ SG_ "Version" STRING ;
BA_DEF_ SG_ "GenSigEnvVarType" ENUM "Int","Float","Undef" ;
BA_DEF_ SG_ "GenSigSendType" ENUM "Cyclic","OnWrite","OnWriteWithRepetition","OnChange","OnChangeWithRepetition","IfActive","IfActiveWithRepetition","NoSigSendType","OnChangeAndIfActive","OnChangeAndIfActiveWithRepetition" ;
BA_DEF_ SG_ "GwSigLatencyTime" INT 0 65536 ;
BA_DEF_ SG_ "GwSigMissingSourceType" ENUM "Undef","OldValue","DefaultValue","InitialValue" ;
BA_DEF_ SG_ "NWM-WakeupAllowed" ENUM "<n.a.>" ;
BA_DEF_ SG_ "RoutingFactor" INT 1 1215752192 ;
BA_DEF_REL_ BU_SG_REL_ "GenSigTimeoutTime" INT 0 7000 ;
BA_DEF_DEF_ "DiagState" "No" ;
BA_DEF_DEF_ "DiagResponse" "No" ;
BA_DEF_DEF_ "DiagRequest" "No" ;
BA_DEF_DEF_ "TpMessage" "No" ;
BA_DEF_DEF_ "UsrMsgIDSforwardDeviation" 10 ;
BA_DEF_DEF_ "UsrMsgIDSbackwardDeviation" 100 ;
BA_DEF_DEF_ "GenMsgCycleTime" 200 ;
BA_DEF_DEF_ "GenMsgStartDelayTime" 0 ;
BA_DEF_DEF_ "GenMsgSendType" "NoMsgSendType" ;
BA_DEF_DEF_ "GenMsgCycleTimeFast" 40 ;
BA_DEF_DEF_ "GenMsgDelayTime" 20 ;
BA_DEF_DEF_ "GenMsgILSupport" "Yes" ;
BA_DEF_DEF_ "GenMsgNrOfRepetition" 3 ;
BA_DEF_DEF_ "NmMessage" "No" ;
BA_DEF_DEF_ "NWM-Botschaft" "No" ;
BA_DEF_DEF_ "TpTxIndex" 0 ;
BA_DEF_DEF_ "VFrameFormat" "StandardCAN" ;
BA_DEF_DEF_ "UserSigValidity" "IG" ;
BA_DEF_DEF_ "TimeoutValue" "" ;
BA_DEF_DEF_ "UsrSigPurpose" "FN" ;
BA_DEF_DEF_ "GenSigStartValue" 0 ;
BA_DEF_DEF_ "NetworkRequest" "No" ;
BA_DEF_DEF_ "NetworkRequestHoldingTime" 0 ;
BA_DEF_DEF_ "Description" "" ;
BA_DEF_DEF_ "Version" "" ;
BA_DEF_DEF_ "GenSigEnvVarType" "Undef" ;
BA_DEF_DEF_ "GenSigSendType" "NoSigSendType" ;
BA_DEF_DEF_ "GwSigLatencyTime" 40 ;
BA_DEF_DEF_ "GwSigMissingSourceType" "Undef" ;
BA_DEF_DEF_ "NWM-WakeupAllowed" "<n.a.>" ;
BA_DEF_DEF_ "RoutingFactor" 1 ;
BA_DEF_DEF_REL_ "GenSigTimeoutTime" 500 ;
BA_ "GenMsgSendType" BO_ 2256643329 0;
BA_ "GenMsgCycleTime" BO_ 2256643329 100;
BA_ "GenMsgCycleTimeFast" BO_ 2256643329 0;
BA_ "GenMsgNrOfRepetition" BO_ 2256643329 0;
BA_ "VFrameFormat" BO_ 2256643329 1;
BA_ "Description" SG_ 2256643329 AWD_Crc1Val "The data area for CRC calculation is based on the data length (DLC) of the message DB.

The CRC shall be calculated over the entire data block (excluding the CRC bytes) including the user data, alive counter and Data ID

 

- CRC Polynomial (0x1021) , Initial Value : 0xFFFF, XOR value : 0x0000, Data ID : Message ID + 0xF800 

- The initial value is for CRC calculation and the message should be sent with the calculated result value. 

- The mathematical expression to 16 bit CRC polynomial is given here. G(x) = x16 + x12 + x5 + 1";
BA_ "GenSigStartValue" SG_ 2256643329 AWD_Crc1Val 65535;
BA_ "UserSigValidity" SG_ 2256643329 AWD_Crc1Val 3;
BA_ "RoutingFactor" SG_ 2256643329 AWD_Crc1Val 5;
BA_ "Version" SG_ 2256643329 AWD_Crc1Val "18.11.08";
BA_ "Description" SG_ 2256643329 AWD_AlvCnt1Val "For the first transmission request for a data element the counter shall be initialized with 0 and shall be incremented by 1 for every subsequent send request. 

When the counter reaches the maximum value(0xFF), then it shall restart with 0 for the next send request";
BA_ "UserSigValidity" SG_ 2256643329 AWD_AlvCnt1Val 3;
BA_ "RoutingFactor" SG_ 2256643329 AWD_AlvCnt1Val 5;
BA_ "Version" SG_ 2256643329 AWD_AlvCnt1Val "18.11.08";
BA_ "Description" SG_ 2256643329 AWD_Typ "* FF = Front engine and Front wheel driving

* FR = Front engine and Rear wheel driving";
BA_ "UserSigValidity" SG_ 2256643329 AWD_Typ 3;
BA_REL_ "GenSigTimeoutTime" BU_SG_REL_ AMP SG_ 2256643329 AWD_Typ 1500;
BA_ "RoutingFactor" SG_ 2256643329 AWD_Typ 5;
BA_ "Version" SG_ 2256643329 AWD_Typ "17.11.00";
BA_ "UserSigValidity" SG_ 2256643329 AWD_SigSpprtSta 3;
BA_ "RoutingFactor" SG_ 2256643329 AWD_SigSpprtSta 5;
BA_ "Version" SG_ 2256643329 AWD_SigSpprtSta "17.11.00";
BA_ "Description" SG_ 2256643329 AWD_IcscErrSta "Information indicating ICSC Signal";
BA_ "UserSigValidity" SG_ 2256643329 AWD_IcscErrSta 3;
BA_ "RoutingFactor" SG_ 2256643329 AWD_IcscErrSta 5;
BA_ "Version" SG_ 2256643329 AWD_IcscErrSta "17.11.00";
BA_ "Description" SG_ 2256643329 AWD_ErrCodeVal "This is for the “AWD ECU, MAGNA & WIA JV社” system applied vehicles only.";
BA_ "UserSigValidity" SG_ 2256643329 AWD_ErrCodeVal 3;
BA_ "RoutingFactor" SG_ 2256643329 AWD_ErrCodeVal 5;
BA_ "Version" SG_ 2256643329 AWD_ErrCodeVal "17.11.00";
BA_ "Description" SG_ 2256643329 AWD_CltchDtVal "Part time AWD system does not support this information via CAN";
BA_ "UserSigValidity" SG_ 2256643329 AWD_CltchDtVal 3;
BA_ "RoutingFactor" SG_ 2256643329 AWD_CltchDtVal 5;
BA_ "Version" SG_ 2256643329 AWD_CltchDtVal "17.11.00";
BA_ "UserSigValidity" SG_ 2256643329 AWD_TireRdsVal 3;
BA_ "RoutingFactor" SG_ 2256643329 AWD_TireRdsVal 5;
BA_ "Version" SG_ 2256643329 AWD_TireRdsVal "17.11.00";
BA_ "UserSigValidity" SG_ 2256643329 AWD_SwVerVal 3;
BA_ "RoutingFactor" SG_ 2256643329 AWD_SwVerVal 5;
BA_ "Version" SG_ 2256643329 AWD_SwVerVal "17.11.00";
BA_ "GenMsgSendType" BO_ 2256643330 0;
BA_ "GenMsgCycleTime" BO_ 2256643330 100;
BA_ "GenMsgCycleTimeFast" BO_ 2256643330 0;
BA_ "GenMsgNrOfRepetition" BO_ 2256643330 0;
BA_ "VFrameFormat" BO_ 2256643330 1;
BA_ "UserSigValidity" SG_ 2256643330 AWD_OpMod2HSta 3;
BA_ "RoutingFactor" SG_ 2256643330 AWD_OpMod2HSta 5;
BA_ "Version" SG_ 2256643330 AWD_OpMod2HSta "17.11.00";
BA_ "Description" SG_ 2256643330 AWD_TireSizeWrng "The signal AWD_TireSizeWrng is used to inform the difference of front and rear wheel's dynamic radius. 4WD ECU calculate front and rear tire's dynamic radius difference.

When front and rear tire diameter difference 3 level detected, 4WD ECU control open state to protect. If tire difference is under 2 level , 4WD resume normal operating.";
BA_ "UserSigValidity" SG_ 2256643330 AWD_TireSizeWrng 3;
BA_ "RoutingFactor" SG_ 2256643330 AWD_TireSizeWrng 5;
BA_ "Version" SG_ 2256643330 AWD_TireSizeWrng "18.08.01";
BA_ "UserSigValidity" SG_ 2256643330 AWD_ShaftTqVal 3;
BA_ "RoutingFactor" SG_ 2256643330 AWD_ShaftTqVal 5;
BA_ "Version" SG_ 2256643330 AWD_ShaftTqVal "17.11.00";
BA_ "UserSigValidity" SG_ 2256643330 AWD_OpMod4HSta 3;
BA_ "RoutingFactor" SG_ 2256643330 AWD_OpMod4HSta 5;
BA_ "Version" SG_ 2256643330 AWD_OpMod4HSta "17.11.00";
BA_ "GenSigStartValue" SG_ 2256643330 AWD_StrWhlPosVal 600;
BA_ "UserSigValidity" SG_ 2256643330 AWD_StrWhlPosVal 3;
BA_ "RoutingFactor" SG_ 2256643330 AWD_StrWhlPosVal 5;
BA_ "Version" SG_ 2256643330 AWD_StrWhlPosVal "17.11.00";
BA_ "UserSigValidity" SG_ 2256643330 AWD_OpModLowSta 3;
BA_ "RoutingFactor" SG_ 2256643330 AWD_OpModLowSta 5;
BA_ "Version" SG_ 2256643330 AWD_OpModLowSta "17.11.00";
BA_ "Description" SG_ 2256643330 AWD_FRWhlSpdSnsrVal "This signal is not available in a part time AWD system and AWD system which use propeller shaft speed.";
BA_ "UserSigValidity" SG_ 2256643330 AWD_FRWhlSpdSnsrVal 3;
BA_ "RoutingFactor" SG_ 2256643330 AWD_FRWhlSpdSnsrVal 5;
BA_ "Version" SG_ 2256643330 AWD_FRWhlSpdSnsrVal "17.11.00";
BA_ "Description" SG_ 2256643330 AWD_FLWhlSpdSnsrVal "This signal is not available in a part time AWD system and AWD system which use propeller shaft speed.";
BA_ "UserSigValidity" SG_ 2256643330 AWD_FLWhlSpdSnsrVal 3;
BA_ "RoutingFactor" SG_ 2256643330 AWD_FLWhlSpdSnsrVal 5;
BA_ "Version" SG_ 2256643330 AWD_FLWhlSpdSnsrVal "17.11.00";
BA_ "UserSigValidity" SG_ 2256643330 AWD_OpModAutoSta 3;
BA_ "RoutingFactor" SG_ 2256643330 AWD_OpModAutoSta 5;
BA_ "Version" SG_ 2256643330 AWD_OpModAutoSta "17.11.00";
BA_ "UserSigValidity" SG_ 2256643330 AWD_OpModLkSta 3;
BA_ "RoutingFactor" SG_ 2256643330 AWD_OpModLkSta 5;
BA_ "Version" SG_ 2256643330 AWD_OpModLkSta "17.11.00";
BA_ "GenMsgSendType" BO_ 2256643331 0;
BA_ "GenMsgCycleTime" BO_ 2256643331 100;
BA_ "GenMsgCycleTimeFast" BO_ 2256643331 0;
BA_ "GenMsgNrOfRepetition" BO_ 2256643331 0;
BA_ "VFrameFormat" BO_ 2256643331 1;
BA_ "Description" SG_ 2256643331 AWD_RRWhlSpdSnsrVal "This signal is not available in a part time AWD system and AWD system which use propeller shaft speed.";
BA_ "UserSigValidity" SG_ 2256643331 AWD_RRWhlSpdSnsrVal 3;
BA_ "RoutingFactor" SG_ 2256643331 AWD_RRWhlSpdSnsrVal 5;
BA_ "Version" SG_ 2256643331 AWD_RRWhlSpdSnsrVal "17.11.00";
BA_ "GenSigStartValue" SG_ 2256643331 AWD_CltchPrsrVal 800;
BA_ "UserSigValidity" SG_ 2256643331 AWD_CltchPrsrVal 3;
BA_ "RoutingFactor" SG_ 2256643331 AWD_CltchPrsrVal 5;
BA_ "Version" SG_ 2256643331 AWD_CltchPrsrVal "17.11.00";
BA_ "UserSigValidity" SG_ 2256643331 AWD_ActrCurrVal 3;
BA_ "RoutingFactor" SG_ 2256643331 AWD_ActrCurrVal 5;
BA_ "Version" SG_ 2256643331 AWD_ActrCurrVal "17.11.00";
BA_ "UserSigValidity" SG_ 2256643331 AWD_ActrPosVal 3;
BA_ "RoutingFactor" SG_ 2256643331 AWD_ActrPosVal 5;
BA_ "Version" SG_ 2256643331 AWD_ActrPosVal "17.11.00";
BA_ "UserSigValidity" SG_ 2256643331 AWD_CltchThrmlStrssVal 3;
BA_ "RoutingFactor" SG_ 2256643331 AWD_CltchThrmlStrssVal 5;
BA_ "Version" SG_ 2256643331 AWD_CltchThrmlStrssVal "17.11.00";
BA_ "Description" SG_ 2256643331 AWD_RLWhlSpdSnsrVal "This signal is not available in a part time AWD system and AWD system which use propeller shaft speed.";
BA_ "UserSigValidity" SG_ 2256643331 AWD_RLWhlSpdSnsrVal 3;
BA_ "RoutingFactor" SG_ 2256643331 AWD_RLWhlSpdSnsrVal 5;
BA_ "Version" SG_ 2256643331 AWD_RLWhlSpdSnsrVal "17.11.00";
BA_ "GenMsgSendType" BO_ 2256643332 0;
BA_ "GenMsgCycleTime" BO_ 2256643332 100;
BA_ "GenMsgCycleTimeFast" BO_ 2256643332 0;
BA_ "GenMsgNrOfRepetition" BO_ 2256643332 0;
BA_ "VFrameFormat" BO_ 2256643332 1;
BA_ "Description" SG_ 2256643332 AWD_ShaftTqVal_Calc "AWD Calculating Torque When ICSC DTVC(AWD) mode activated.";
BA_ "UserSigValidity" SG_ 2256643332 AWD_ShaftTqVal_Calc 3;
BA_ "RoutingFactor" SG_ 2256643332 AWD_ShaftTqVal_Calc 5;
BA_ "Version" SG_ 2256643332 AWD_ShaftTqVal_Calc "17.11.00";
BA_ "Description" SG_ 2256643332 AWD_FrTqDistRto "Signal for display on cluster.(Torque Distribution ratio to Front Wheel)";
BA_ "UserSigValidity" SG_ 2256643332 AWD_FrTqDistRto 3;
BA_ "RoutingFactor" SG_ 2256643332 AWD_FrTqDistRto 5;
BA_ "Version" SG_ 2256643332 AWD_FrTqDistRto "18.08.02";
BA_ "UserSigValidity" SG_ 2256643332 AWD_SysOpSta 3;
BA_ "RoutingFactor" SG_ 2256643332 AWD_SysOpSta 5;
BA_ "Version" SG_ 2256643332 AWD_SysOpSta "19.08.05";
BA_ "Description" SG_ 2256643332 AWD_RrTqDistRto "Signal for display on cluster (Torque Distribution ratio to Rear Wheel)";
BA_ "UserSigValidity" SG_ 2256643332 AWD_RrTqDistRto 3;
BA_ "RoutingFactor" SG_ 2256643332 AWD_RrTqDistRto 5;
BA_ "Version" SG_ 2256643332 AWD_RrTqDistRto "18.08.02";
BA_ "GenMsgSendType" BO_ 2290230529 0;
BA_ "GenMsgCycleTimeFast" BO_ 2290230529 0;
BA_ "GenMsgNrOfRepetition" BO_ 2290230529 0;
BA_ "VFrameFormat" BO_ 2290230529 1;
BA_ "Description" SG_ 2290230529 CLU_Crc2Val "The data area for CRC calculation is based on the data length (DLC) of the message DB.

The CRC shall be calculated over the entire data block (excluding the CRC bytes) including the user data, alive counter and Data ID

 

- CRC Polynomial (0x1021) , Initial Value : 0xFFFF, XOR value : 0x0000, Data ID : Message ID + 0xF800 

- The initial value is for CRC calculation and the message should be sent with the calculated result value. 

- The mathematical expression to 16 bit CRC polynomial is given here. G(x) = x16 + x12 + x5 + 1";
BA_ "GenSigStartValue" SG_ 2290230529 CLU_Crc2Val 65535;
BA_ "UserSigValidity" SG_ 2290230529 CLU_Crc2Val 3;
BA_ "RoutingFactor" SG_ 2290230529 CLU_Crc2Val 2;
BA_ "Version" SG_ 2290230529 CLU_Crc2Val "18.11.08";
BA_ "Description" SG_ 2290230529 CLU_AlvCnt2Val "For the first transmission request for a data element the counter shall be initialized with 0 and shall be incremented by 1 for every subsequent send request. 

When the counter reaches the maximum value(0xFF), then it shall restart with 0 for the next send request";
BA_ "UserSigValidity" SG_ 2290230529 CLU_AlvCnt2Val 3;
BA_ "RoutingFactor" SG_ 2290230529 CLU_AlvCnt2Val 2;
BA_ "Version" SG_ 2290230529 CLU_AlvCnt2Val "18.11.08";
BA_ "Description" SG_ 2290230529 CLU_OutTempCSta "The signal is outside temerature of the cluster (Unit: ℃)";
BA_ "UserSigValidity" SG_ 2290230529 CLU_OutTempCSta 3;
BA_REL_ "GenSigTimeoutTime" BU_SG_REL_ ATS SG_ 2290230529 CLU_OutTempCSta 1500;
BA_ "RoutingFactor" SG_ 2290230529 CLU_OutTempCSta 2;
BA_ "Version" SG_ 2290230529 CLU_OutTempCSta "17.12.03";
BA_ "Description" SG_ 2290230529 CLU_DTEVal "This signal indicates DTE.

0x0: Valid DTE 0 (Display '---')

0x1~0xFFE: Valid DTE (1 ~ 4094 km)

(DTE >4094 km : 0xFFE)

0xFFF : Invalid(Display '---' Blink)";
BA_ "UserSigValidity" SG_ 2290230529 CLU_DTEVal 3;
BA_ "RoutingFactor" SG_ 2290230529 CLU_DTEVal 2;
BA_ "Version" SG_ 2290230529 CLU_DTEVal "19.02.07";
BA_ "Description" SG_ 2290230529 CLU_TripUnitSta "This signal indicates Distance to Empty UNIT";
BA_ "UserSigValidity" SG_ 2290230529 CLU_TripUnitSta 3;
BA_ "RoutingFactor" SG_ 2290230529 CLU_TripUnitSta 2;
BA_ "Version" SG_ 2290230529 CLU_TripUnitSta "17.11.00";
BA_ "Description" SG_ 2290230529 CLU_LoFuelWrngSta "This signal indicates that the Low fuel warning in the cluster is On or Off. When Low Fuel Warning is On, its value is 01H otherwise its value is 00H.";
BA_ "UserSigValidity" SG_ 2290230529 CLU_LoFuelWrngSta 3;
BA_ "RoutingFactor" SG_ 2290230529 CLU_LoFuelWrngSta 2;
BA_ "Version" SG_ 2290230529 CLU_LoFuelWrngSta "17.11.00";
BA_ "GenMsgSendType" BO_ 2290230530 0;
BA_ "GenMsgCycleTimeFast" BO_ 2290230530 0;
BA_ "GenMsgNrOfRepetition" BO_ 2290230530 0;
BA_ "VFrameFormat" BO_ 2290230530 1;
BA_ "Description" SG_ 2290230530 CLU_DawLastBrkTimeVal "This signal indicates that the elapsed time count after last driver's break. The elapsed time count increase 1 at an interval of 30 minutes.";
BA_ "UserSigValidity" SG_ 2290230530 CLU_DawLastBrkTimeVal 3;
BA_ "RoutingFactor" SG_ 2290230530 CLU_DawLastBrkTimeVal 2;
BA_ "Version" SG_ 2290230530 CLU_DawLastBrkTimeVal "17.11.00";
BA_ "Description" SG_ 2290230530 CLU_IceWrnIndSta "This signal indicates that the Ice warning indicator in the cluster is on or off.

When Ice warning indicator is on, its value is 0x1 otherwise its value is 0x0.";
BA_ "UserSigValidity" SG_ 2290230530 CLU_IceWrnIndSta 3;
BA_ "RoutingFactor" SG_ 2290230530 CLU_IceWrnIndSta 2;
BA_ "Version" SG_ 2290230530 CLU_IceWrnIndSta "17.11.00";
BA_ "Description" SG_ 2290230530 CLU_DrvngModSwSta "This signal occurs when drive mode switch is selected either 'Normal' or 'Eco' or 'Sport' or 'Sport+' or 'Smart' or 'Custom' or 'N-mode'.";
BA_ "UserSigValidity" SG_ 2290230530 CLU_DrvngModSwSta 3;
BA_ "RoutingFactor" SG_ 2290230530 CLU_DrvngModSwSta 2;
BA_ "Version" SG_ 2290230530 CLU_DrvngModSwSta "18.02.03";
BA_ "Description" SG_ 2290230530 CLU_FuelLvlSta "The signal is fuel level of the cluster that fuel gauge indicate (Unit: %)";
BA_ "UserSigValidity" SG_ 2290230530 CLU_FuelLvlSta 3;
BA_ "RoutingFactor" SG_ 2290230530 CLU_FuelLvlSta 2;
BA_ "Version" SG_ 2290230530 CLU_FuelLvlSta "17.12.03";
BA_ "Description" SG_ 2290230530 CLU_SRSWrngLmpSta "This signal is generated by one of the following 5 self-diagnostic result of micro-controller of Cluster.

1) “Lamp ON” status as a self-status diagnostic result of cluster

2) “Lamp OFF” status as a self-status diagnostic result of cluster

3) “Lamp flashing with 1hz frequency / 50% duty ratio” as a self-status result diagnostic result of cluster

4) “Lamp Circuit Failure” as a self-diagnostic result of cluster circuit 

5) “No Valid ACU message” as ACU4 message check result by cluster



Note to be taken that CLU2 message does not include judgment on “SRS W/Lamp failure in terms of airbag system”. CLU2 message only contains “status and diagnostic result of Cluster itself”.";
BA_ "UserSigValidity" SG_ 2290230530 CLU_SRSWrngLmpSta 3;
BA_ "RoutingFactor" SG_ 2290230530 CLU_SRSWrngLmpSta 2;
BA_ "Version" SG_ 2290230530 CLU_SRSWrngLmpSta "17.12.03";
BA_ "Description" SG_ 2290230530 CLU_OutTempFSta "The signal is outside temerature of the cluster (Unit: ℉)";
BA_ "UserSigValidity" SG_ 2290230530 CLU_OutTempFSta 3;
BA_REL_ "GenSigTimeoutTime" BU_SG_REL_ ATS SG_ 2290230530 CLU_OutTempFSta 1500;
BA_ "RoutingFactor" SG_ 2290230530 CLU_OutTempFSta 2;
BA_ "Version" SG_ 2290230530 CLU_OutTempFSta "17.12.03";
BA_ "Description" SG_ 2290230530 CLU_OdoVal "This signal indicates mileage counter of a vehicle. Cluster calculates total mileage and sends it to SCC and CUBIS. This value shall be the same with the mileage that is displayed to a driver.";
BA_ "UserSigValidity" SG_ 2290230530 CLU_OdoVal 3;
BA_ "RoutingFactor" SG_ 2290230530 CLU_OdoVal 2;
BA_ "Version" SG_ 2290230530 CLU_OdoVal "17.11.00";
BA_ "GenMsgSendType" BO_ 2558926849 0;
BA_ "GenMsgStartDelayTime" BO_ 2558926849 150;
BA_ "VFrameFormat" BO_ 2558926849 1;
BA_ "GenSigSendType" SG_ 2558926849 Warn_Sound_Off 4;
BA_ "GenSigStartValue" SG_ 2558926849 Warn_Sound_Off 7;
BA_ "UserSigValidity" SG_ 2558926849 Warn_Sound_Off 1;
BA_REL_ "GenSigTimeoutTime" BU_SG_REL_ AMP SG_ 2558926849 Warn_Sound_Off 1500;
BA_ "Version" SG_ 2558926849 Warn_Sound_Off "18.12.06";
BA_ "GenSigSendType" SG_ 2558926849 Warn_Sound_PAS 4;
BA_ "GenSigStartValue" SG_ 2558926849 Warn_Sound_PAS 31;
BA_ "UserSigValidity" SG_ 2558926849 Warn_Sound_PAS 1;
BA_REL_ "GenSigTimeoutTime" BU_SG_REL_ AMP SG_ 2558926849 Warn_Sound_PAS 1500;
BA_ "Version" SG_ 2558926849 Warn_Sound_PAS "18.12.06";
BA_ "GenSigSendType" SG_ 2558926849 Warn_Sound_SPAS 4;
BA_ "GenSigStartValue" SG_ 2558926849 Warn_Sound_SPAS 7;
BA_ "UserSigValidity" SG_ 2558926849 Warn_Sound_SPAS 1;
BA_REL_ "GenSigTimeoutTime" BU_SG_REL_ AMP SG_ 2558926849 Warn_Sound_SPAS 1500;
BA_ "Version" SG_ 2558926849 Warn_Sound_SPAS "18.12.06";
BA_ "GenSigSendType" SG_ 2558926849 Warn_Sound_EPB 4;
BA_ "GenSigStartValue" SG_ 2558926849 Warn_Sound_EPB 31;
BA_ "UserSigValidity" SG_ 2558926849 Warn_Sound_EPB 0;
BA_REL_ "GenSigTimeoutTime" BU_SG_REL_ AMP SG_ 2558926849 Warn_Sound_EPB 1500;
BA_ "NetworkRequest" SG_ 2558926849 Warn_Sound_EPB 0;
BA_ "Version" SG_ 2558926849 Warn_Sound_EPB "18.12.06";
BA_ "GenSigSendType" SG_ 2558926849 Warn_Sound_Welcome 4;
BA_ "GenSigStartValue" SG_ 2558926849 Warn_Sound_Welcome 7;
BA_ "UserSigValidity" SG_ 2558926849 Warn_Sound_Welcome 0;
BA_REL_ "GenSigTimeoutTime" BU_SG_REL_ AMP SG_ 2558926849 Warn_Sound_Welcome 1500;
BA_ "Version" SG_ 2558926849 Warn_Sound_Welcome "19.03.09";
BA_ "GenSigSendType" SG_ 2558926849 Warn_Sound_IMS 4;
BA_ "GenSigStartValue" SG_ 2558926849 Warn_Sound_IMS 7;
BA_ "UserSigValidity" SG_ 2558926849 Warn_Sound_IMS 0;
BA_REL_ "GenSigTimeoutTime" BU_SG_REL_ AMP SG_ 2558926849 Warn_Sound_IMS 1500;
BA_ "NetworkRequest" SG_ 2558926849 Warn_Sound_IMS 0;
BA_ "Version" SG_ 2558926849 Warn_Sound_IMS "18.12.06";
BA_ "GenSigSendType" SG_ 2558926849 Warn_Sound_FCW 4;
BA_ "GenSigStartValue" SG_ 2558926849 Warn_Sound_FCW 7;
BA_ "UserSigValidity" SG_ 2558926849 Warn_Sound_FCW 1;
BA_REL_ "GenSigTimeoutTime" BU_SG_REL_ AMP SG_ 2558926849 Warn_Sound_FCW 1500;
BA_ "Version" SG_ 2558926849 Warn_Sound_FCW "18.12.06";
BA_ "GenSigSendType" SG_ 2558926849 Warn_Sound_Ice 4;
BA_ "GenSigStartValue" SG_ 2558926849 Warn_Sound_Ice 3;
BA_ "UserSigValidity" SG_ 2558926849 Warn_Sound_Ice 1;
BA_REL_ "GenSigTimeoutTime" BU_SG_REL_ AMP SG_ 2558926849 Warn_Sound_Ice 1500;
BA_ "Version" SG_ 2558926849 Warn_Sound_Ice "18.12.06";
BA_ "GenSigSendType" SG_ 2558926849 Warn_Sound_SeatBeltStep 4;
BA_ "UserSigValidity" SG_ 2558926849 Warn_Sound_SeatBeltStep 0;
BA_REL_ "GenSigTimeoutTime" BU_SG_REL_ AMP SG_ 2558926849 Warn_Sound_SeatBeltStep 1500;
BA_ "Version" SG_ 2558926849 Warn_Sound_SeatBeltStep "18.12.06";
BA_ "GenSigSendType" SG_ 2558926849 Warn_Sound_PopUp 4;
BA_ "GenSigStartValue" SG_ 2558926849 Warn_Sound_PopUp 7;
BA_ "UserSigValidity" SG_ 2558926849 Warn_Sound_PopUp 0;
BA_REL_ "GenSigTimeoutTime" BU_SG_REL_ AMP SG_ 2558926849 Warn_Sound_PopUp 1500;
BA_ "NetworkRequest" SG_ 2558926849 Warn_Sound_PopUp 0;
BA_ "Version" SG_ 2558926849 Warn_Sound_PopUp "18.12.06";
BA_ "GenSigSendType" SG_ 2558926849 Warn_Sound_TikTok 4;
BA_ "GenSigStartValue" SG_ 2558926849 Warn_Sound_TikTok 3;
BA_ "UserSigValidity" SG_ 2558926849 Warn_Sound_TikTok 0;
BA_REL_ "GenSigTimeoutTime" BU_SG_REL_ AMP SG_ 2558926849 Warn_Sound_TikTok 1500;
BA_ "NetworkRequest" SG_ 2558926849 Warn_Sound_TikTok 0;
BA_ "Version" SG_ 2558926849 Warn_Sound_TikTok "18.12.06";
BA_ "GenSigSendType" SG_ 2558926849 Warn_Sound_SBW_P 4;
BA_ "GenSigStartValue" SG_ 2558926849 Warn_Sound_SBW_P 3;
BA_ "UserSigValidity" SG_ 2558926849 Warn_Sound_SBW_P 0;
BA_REL_ "GenSigTimeoutTime" BU_SG_REL_ AMP SG_ 2558926849 Warn_Sound_SBW_P 1500;
BA_ "NetworkRequest" SG_ 2558926849 Warn_Sound_SBW_P 0;
BA_ "Version" SG_ 2558926849 Warn_Sound_SBW_P "18.12.06";
BA_ "Description" SG_ 2558926849 Warn_Sound_ETC "This signal is transmitted from cluster to AMP for 12 group cluster sound0x0";
BA_ "GenSigSendType" SG_ 2558926849 Warn_Sound_ETC 4;
BA_ "GenSigStartValue" SG_ 2558926849 Warn_Sound_ETC 63;
BA_ "UserSigValidity" SG_ 2558926849 Warn_Sound_ETC 0;
BA_REL_ "GenSigTimeoutTime" BU_SG_REL_ AMP SG_ 2558926849 Warn_Sound_ETC 1500;
BA_ "NetworkRequest" SG_ 2558926849 Warn_Sound_ETC 0;
BA_ "NetworkRequestHoldingTime" SG_ 2558926849 Warn_Sound_ETC 1;
BA_ "Version" SG_ 2558926849 Warn_Sound_ETC "19.07.05";
BA_ "GenSigSendType" SG_ 2558926849 Warn_Sound_SeatBelt 4;
BA_ "GenSigStartValue" SG_ 2558926849 Warn_Sound_SeatBelt 3;
BA_ "UserSigValidity" SG_ 2558926849 Warn_Sound_SeatBelt 1;
BA_REL_ "GenSigTimeoutTime" BU_SG_REL_ AMP SG_ 2558926849 Warn_Sound_SeatBelt 1500;
BA_ "Version" SG_ 2558926849 Warn_Sound_SeatBelt "18.12.06";
BA_ "GenSigSendType" SG_ 2558926849 Elec_Sound_VolLevel 4;
BA_ "GenSigStartValue" SG_ 2558926849 Elec_Sound_VolLevel 7;
BA_ "UserSigValidity" SG_ 2558926849 Elec_Sound_VolLevel 1;
BA_REL_ "GenSigTimeoutTime" BU_SG_REL_ AMP SG_ 2558926849 Elec_Sound_VolLevel 1500;
BA_ "Version" SG_ 2558926849 Elec_Sound_VolLevel "18.12.06";
BA_ "GenMsgSendType" BO_ 2382595073 0;
BA_ "VFrameFormat" BO_ 2382595073 1;
BA_ "Description" SG_ 2382595073 DATC_Crc7Val "The data area for CRC calculation is based on the data length (DLC) of the message DB.

The CRC shall be calculated over the entire data block (excluding the CRC bytes) including the user data, alive counter and Data ID

 

- CRC Polynomial (0x1021) , Initial Value : 0xFFFF, XOR value : 0x0000, Data ID : Message ID + 0xF800 

- The initial value is for CRC calculation and the message should be sent with the calculated result value. 

- The mathematical expression to 16 bit CRC polynomial is given here. G(x) = x16 + x12 + x5 + 1";
BA_ "GenSigSendType" SG_ 2382595073 DATC_Crc7Val 4;
BA_ "GenSigStartValue" SG_ 2382595073 DATC_Crc7Val 65535;
BA_ "UserSigValidity" SG_ 2382595073 DATC_Crc7Val 3;
BA_ "Version" SG_ 2382595073 DATC_Crc7Val "18.11.08";
BA_ "Description" SG_ 2382595073 DATC_AlvCnt7Val "For the first transmission request for a data element the counter shall be initialized with 0 and shall be incremented by 1 for every subsequent send request. 

When the counter reaches the maximum value(0xFF), then it shall restart with 0 for the next send request";
BA_ "GenSigSendType" SG_ 2382595073 DATC_AlvCnt7Val 4;
BA_ "UserSigValidity" SG_ 2382595073 DATC_AlvCnt7Val 3;
BA_ "Version" SG_ 2382595073 DATC_AlvCnt7Val "18.11.08";
BA_ "Description" SG_ 2382595073 DATC_FrDrvBlwDis "This signal indicates step of Front blower Graphic.

This signal occurs when Front Blower switch(button) is selected either manually or automatically.";
BA_ "GenSigSendType" SG_ 2382595073 DATC_FrDrvBlwDis 4;
BA_ "UserSigValidity" SG_ 2382595073 DATC_FrDrvBlwDis 7;
BA_REL_ "GenSigTimeoutTime" BU_SG_REL_ ATS SG_ 2382595073 DATC_FrDrvBlwDis 1500;
BA_ "Version" SG_ 2382595073 DATC_FrDrvBlwDis "18.11.06";
BA_ "GenSigSendType" SG_ 2382595073 DATC_FrPsBlwDis 4;
BA_ "UserSigValidity" SG_ 2382595073 DATC_FrPsBlwDis 7;
BA_REL_ "GenSigTimeoutTime" BU_SG_REL_ ATS SG_ 2382595073 DATC_FrPsBlwDis 1500;
BA_ "Version" SG_ 2382595073 DATC_FrPsBlwDis "19.05.03";
BA_ "Description" SG_ 2382595073 DATC_AUTOStep "This signal indicates AUTO step status in case Multi Auto Blower type.";
BA_ "GenSigSendType" SG_ 2382595073 DATC_AUTOStep 4;
BA_ "UserSigValidity" SG_ 2382595073 DATC_AUTOStep 7;
BA_ "Version" SG_ 2382595073 DATC_AUTOStep "18.12.08";
BA_ "Description" SG_ 2382595073 DATC_IntakeDis "This signal indicates intake indicator & display";
BA_ "GenSigSendType" SG_ 2382595073 DATC_IntakeDis 4;
BA_ "UserSigValidity" SG_ 2382595073 DATC_IntakeDis 7;
BA_REL_ "GenSigTimeoutTime" BU_SG_REL_ ATS SG_ 2382595073 DATC_IntakeDis 1500;
BA_ "Version" SG_ 2382595073 DATC_IntakeDis "18.12.08";
BA_ "GenMsgCycleTime" BO_ 209 0;
BA_ "Description" SG_ 209 DSAU_SmartCtrl_1h "스마트 자세제어 DSAU 연동 조절에 따른 개선현황 AVN 표시문구_1시간";
BA_ "GenSigSendType" SG_ 209 DSAU_SmartCtrl_1h 4;
BA_ "UserSigValidity" SG_ 209 DSAU_SmartCtrl_1h 1;
BA_REL_ "GenSigTimeoutTime" BU_SG_REL_ CGW_CCU SG_ 209 DSAU_SmartCtrl_1h 0;
BA_ "Version" SG_ 209 DSAU_SmartCtrl_1h "21.08.01";
BA_ "Description" SG_ 209 DSAU_SmartCtrl_2h "스마트 자세제어 DSAU 연동 조절에 따른 개선현황 AVN 표시 문구_2시간";
BA_ "GenSigSendType" SG_ 209 DSAU_SmartCtrl_2h 4;
BA_ "UserSigValidity" SG_ 209 DSAU_SmartCtrl_2h 1;
BA_REL_ "GenSigTimeoutTime" BU_SG_REL_ CGW_CCU SG_ 209 DSAU_SmartCtrl_2h 0;
BA_ "Version" SG_ 209 DSAU_SmartCtrl_2h "21.08.01";
BA_ "Description" SG_ 209 DSAU_SmartCtrl_Status "스마트 자세제어 2단계 DSAU 연동 조절 동작 시작 / 종료 / 중단 AVN 팝업";
BA_ "GenSigSendType" SG_ 209 DSAU_SmartCtrl_Status 4;
BA_ "UserSigValidity" SG_ 209 DSAU_SmartCtrl_Status 1;
BA_REL_ "GenSigTimeoutTime" BU_SG_REL_ CGW_CCU SG_ 209 DSAU_SmartCtrl_Status 0;
BA_ "Version" SG_ 209 DSAU_SmartCtrl_Status "21.08.01";
BA_ "GenMsgSendType" BO_ 1174 0;
BA_ "Description" SG_ 1174 Drv_SHVU_SeatOptSta "운전석 시트에 적용된 히터/통풍 옵션 사양";
BA_ "GenSigSendType" SG_ 1174 Drv_SHVU_SeatOptSta 4;
BA_ "UserSigValidity" SG_ 1174 Drv_SHVU_SeatOptSta 3;
BA_REL_ "GenSigTimeoutTime" BU_SG_REL_ CGW_CCU SG_ 1174 Drv_SHVU_SeatOptSta 1500;
BA_ "NetworkRequest" SG_ 1174 Drv_SHVU_SeatOptSta 0;
BA_ "NetworkRequestHoldingTime" SG_ 1174 Drv_SHVU_SeatOptSta 5000;
BA_ "Version" SG_ 1174 Drv_SHVU_SeatOptSta "19.01.04";
BA_ "Description" SG_ 1174 Drv_SHVU_HtSwHiIndSta "운전석 시트 열선 스위치 High Indicator 정보";
BA_ "GenSigSendType" SG_ 1174 Drv_SHVU_HtSwHiIndSta 4;
BA_ "UserSigValidity" SG_ 1174 Drv_SHVU_HtSwHiIndSta 3;
BA_REL_ "GenSigTimeoutTime" BU_SG_REL_ CGW_CCU SG_ 1174 Drv_SHVU_HtSwHiIndSta 1500;
BA_ "NetworkRequest" SG_ 1174 Drv_SHVU_HtSwHiIndSta 0;
BA_ "NetworkRequestHoldingTime" SG_ 1174 Drv_SHVU_HtSwHiIndSta 5000;
BA_ "Version" SG_ 1174 Drv_SHVU_HtSwHiIndSta "19.01.04";
BA_ "Description" SG_ 1174 Drv_SHVU_HtSwMidIndSta "운전석 시트 열선 스위치 Mid Indicator 정보";
BA_ "GenSigSendType" SG_ 1174 Drv_SHVU_HtSwMidIndSta 4;
BA_ "UserSigValidity" SG_ 1174 Drv_SHVU_HtSwMidIndSta 3;
BA_REL_ "GenSigTimeoutTime" BU_SG_REL_ CGW_CCU SG_ 1174 Drv_SHVU_HtSwMidIndSta 1500;
BA_ "NetworkRequest" SG_ 1174 Drv_SHVU_HtSwMidIndSta 0;
BA_ "NetworkRequestHoldingTime" SG_ 1174 Drv_SHVU_HtSwMidIndSta 5000;
BA_ "Version" SG_ 1174 Drv_SHVU_HtSwMidIndSta "19.01.04";
BA_ "Description" SG_ 1174 Drv_SHVU_HtSwLowIndSta "운전석 시트 열선 스위치 Low Indicator 정보";
BA_ "GenSigSendType" SG_ 1174 Drv_SHVU_HtSwLowIndSta 4;
BA_ "UserSigValidity" SG_ 1174 Drv_SHVU_HtSwLowIndSta 3;
BA_REL_ "GenSigTimeoutTime" BU_SG_REL_ CGW_CCU SG_ 1174 Drv_SHVU_HtSwLowIndSta 1500;
BA_ "NetworkRequest" SG_ 1174 Drv_SHVU_HtSwLowIndSta 0;
BA_ "NetworkRequestHoldingTime" SG_ 1174 Drv_SHVU_HtSwLowIndSta 5000;
BA_ "Version" SG_ 1174 Drv_SHVU_HtSwLowIndSta "19.01.04";
BA_ "Description" SG_ 1174 Drv_SHVU_VntSwHiIndSta "운전석 시트 통풍 스위치 High Indicator 정보";
BA_ "GenSigSendType" SG_ 1174 Drv_SHVU_VntSwHiIndSta 4;
BA_ "UserSigValidity" SG_ 1174 Drv_SHVU_VntSwHiIndSta 3;
BA_REL_ "GenSigTimeoutTime" BU_SG_REL_ CGW_CCU SG_ 1174 Drv_SHVU_VntSwHiIndSta 1500;
BA_ "NetworkRequest" SG_ 1174 Drv_SHVU_VntSwHiIndSta 0;
BA_ "NetworkRequestHoldingTime" SG_ 1174 Drv_SHVU_VntSwHiIndSta 5000;
BA_ "Version" SG_ 1174 Drv_SHVU_VntSwHiIndSta "19.01.04";
BA_ "Description" SG_ 1174 Drv_SHVU_VntSwMidIndSta "운전석 시트 통풍 스위치 Mid Indicator 정보";
BA_ "GenSigSendType" SG_ 1174 Drv_SHVU_VntSwMidIndSta 4;
BA_ "UserSigValidity" SG_ 1174 Drv_SHVU_VntSwMidIndSta 3;
BA_REL_ "GenSigTimeoutTime" BU_SG_REL_ CGW_CCU SG_ 1174 Drv_SHVU_VntSwMidIndSta 1500;
BA_ "NetworkRequest" SG_ 1174 Drv_SHVU_VntSwMidIndSta 0;
BA_ "NetworkRequestHoldingTime" SG_ 1174 Drv_SHVU_VntSwMidIndSta 5000;
BA_ "Version" SG_ 1174 Drv_SHVU_VntSwMidIndSta "19.01.04";
BA_ "Description" SG_ 1174 Drv_SHVU_VntSwLowIndSta "운전석 시트 통풍 스위치 Low Indicator 정보";
BA_ "GenSigSendType" SG_ 1174 Drv_SHVU_VntSwLowIndSta 4;
BA_ "UserSigValidity" SG_ 1174 Drv_SHVU_VntSwLowIndSta 3;
BA_REL_ "GenSigTimeoutTime" BU_SG_REL_ CGW_CCU SG_ 1174 Drv_SHVU_VntSwLowIndSta 1500;
BA_ "NetworkRequest" SG_ 1174 Drv_SHVU_VntSwLowIndSta 0;
BA_ "NetworkRequestHoldingTime" SG_ 1174 Drv_SHVU_VntSwLowIndSta 5000;
BA_ "Version" SG_ 1174 Drv_SHVU_VntSwLowIndSta "19.01.04";
BA_ "Description" SG_ 1174 Drv_SHVU_HtBlcUSMSta "Hetaer Balance Driver USM R vaule";
BA_ "GenSigSendType" SG_ 1174 Drv_SHVU_HtBlcUSMSta 4;
BA_ "UserSigValidity" SG_ 1174 Drv_SHVU_HtBlcUSMSta 0;
BA_REL_ "GenSigTimeoutTime" BU_SG_REL_ CGW_CCU SG_ 1174 Drv_SHVU_HtBlcUSMSta 1500;
BA_ "Version" SG_ 1174 Drv_SHVU_HtBlcUSMSta "19.01.04";
BA_ "Description" SG_ 1174 Drv_SHVU_SeatHtOperSta "운전석 시트 현재 작동 중인 히터/통풍 단수 상태";
BA_ "GenSigSendType" SG_ 1174 Drv_SHVU_SeatHtOperSta 4;
BA_ "UserSigValidity" SG_ 1174 Drv_SHVU_SeatHtOperSta 3;
BA_REL_ "GenSigTimeoutTime" BU_SG_REL_ CGW_CCU SG_ 1174 Drv_SHVU_SeatHtOperSta 1500;
BA_ "NetworkRequest" SG_ 1174 Drv_SHVU_SeatHtOperSta 0;
BA_ "NetworkRequestHoldingTime" SG_ 1174 Drv_SHVU_SeatHtOperSta 5000;
BA_ "Version" SG_ 1174 Drv_SHVU_SeatHtOperSta "19.01.04";
BA_ "Description" SG_ 1174 Drv_SHVU_SeatOptSta_RHD "운전석 시트에 적용된 히터/통풍 옵션 사양(RHD)";
BA_ "GenSigSendType" SG_ 1174 Drv_SHVU_SeatOptSta_RHD 4;
BA_ "UserSigValidity" SG_ 1174 Drv_SHVU_SeatOptSta_RHD 3;
BA_REL_ "GenSigTimeoutTime" BU_SG_REL_ CGW_CCU SG_ 1174 Drv_SHVU_SeatOptSta_RHD 1500;
BA_ "NetworkRequest" SG_ 1174 Drv_SHVU_SeatOptSta_RHD 0;
BA_ "NetworkRequestHoldingTime" SG_ 1174 Drv_SHVU_SeatOptSta_RHD 5000;
BA_ "Version" SG_ 1174 Drv_SHVU_SeatOptSta_RHD "19.01.04";
BA_ "Description" SG_ 1174 Drv_SHVU_SeatHtOperSta_RHD "운전석 시트 현재 작동 중인 히터/통풍 단수 상태(RHD)";
BA_ "GenSigSendType" SG_ 1174 Drv_SHVU_SeatHtOperSta_RHD 4;
BA_ "UserSigValidity" SG_ 1174 Drv_SHVU_SeatHtOperSta_RHD 3;
BA_REL_ "GenSigTimeoutTime" BU_SG_REL_ CGW_CCU SG_ 1174 Drv_SHVU_SeatHtOperSta_RHD 1500;
BA_ "NetworkRequest" SG_ 1174 Drv_SHVU_SeatHtOperSta_RHD 0;
BA_ "NetworkRequestHoldingTime" SG_ 1174 Drv_SHVU_SeatHtOperSta_RHD 5000;
BA_ "Version" SG_ 1174 Drv_SHVU_SeatHtOperSta_RHD "19.01.04";
BA_ "Description" SG_ 1174 Drv_SHVU_HtSwHiIndSta_RHD "운전석 시트 열선 스위치 High Indicator 정보(RHD)";
BA_ "GenSigSendType" SG_ 1174 Drv_SHVU_HtSwHiIndSta_RHD 4;
BA_ "UserSigValidity" SG_ 1174 Drv_SHVU_HtSwHiIndSta_RHD 3;
BA_REL_ "GenSigTimeoutTime" BU_SG_REL_ CGW_CCU SG_ 1174 Drv_SHVU_HtSwHiIndSta_RHD 1500;
BA_ "NetworkRequest" SG_ 1174 Drv_SHVU_HtSwHiIndSta_RHD 0;
BA_ "NetworkRequestHoldingTime" SG_ 1174 Drv_SHVU_HtSwHiIndSta_RHD 5000;
BA_ "Version" SG_ 1174 Drv_SHVU_HtSwHiIndSta_RHD "19.01.04";
BA_ "Description" SG_ 1174 Drv_SHVU_HtSwMidIndSta_RHD "운전석 시트 열선 스위치 Mid Indicator 정보(RHD)";
BA_ "GenSigSendType" SG_ 1174 Drv_SHVU_HtSwMidIndSta_RHD 4;
BA_ "UserSigValidity" SG_ 1174 Drv_SHVU_HtSwMidIndSta_RHD 3;
BA_REL_ "GenSigTimeoutTime" BU_SG_REL_ CGW_CCU SG_ 1174 Drv_SHVU_HtSwMidIndSta_RHD 1500;
BA_ "NetworkRequest" SG_ 1174 Drv_SHVU_HtSwMidIndSta_RHD 0;
BA_ "NetworkRequestHoldingTime" SG_ 1174 Drv_SHVU_HtSwMidIndSta_RHD 5000;
BA_ "Version" SG_ 1174 Drv_SHVU_HtSwMidIndSta_RHD "19.01.04";
BA_ "Description" SG_ 1174 Drv_SHVU_HtSwLowIndSta_RHD "운전석 시트 열선 스위치 Low Indicator 정보(RHD)";
BA_ "GenSigSendType" SG_ 1174 Drv_SHVU_HtSwLowIndSta_RHD 4;
BA_ "UserSigValidity" SG_ 1174 Drv_SHVU_HtSwLowIndSta_RHD 3;
BA_REL_ "GenSigTimeoutTime" BU_SG_REL_ CGW_CCU SG_ 1174 Drv_SHVU_HtSwLowIndSta_RHD 1500;
BA_ "NetworkRequest" SG_ 1174 Drv_SHVU_HtSwLowIndSta_RHD 0;
BA_ "NetworkRequestHoldingTime" SG_ 1174 Drv_SHVU_HtSwLowIndSta_RHD 5000;
BA_ "Version" SG_ 1174 Drv_SHVU_HtSwLowIndSta_RHD "19.01.04";
BA_ "Description" SG_ 1174 Drv_SHVU_VntSwHiIndSta_RHD "운전석 시트 통풍 스위치 High Indicator 정보(RHD)";
BA_ "GenSigSendType" SG_ 1174 Drv_SHVU_VntSwHiIndSta_RHD 4;
BA_ "UserSigValidity" SG_ 1174 Drv_SHVU_VntSwHiIndSta_RHD 3;
BA_REL_ "GenSigTimeoutTime" BU_SG_REL_ CGW_CCU SG_ 1174 Drv_SHVU_VntSwHiIndSta_RHD 1500;
BA_ "NetworkRequest" SG_ 1174 Drv_SHVU_VntSwHiIndSta_RHD 0;
BA_ "NetworkRequestHoldingTime" SG_ 1174 Drv_SHVU_VntSwHiIndSta_RHD 5000;
BA_ "Version" SG_ 1174 Drv_SHVU_VntSwHiIndSta_RHD "19.01.04";
BA_ "Description" SG_ 1174 Drv_SHVU_VntSwMidIndSta_RHD "운전석 시트 통풍 스위치 Mid Indicator 정보(RHD)";
BA_ "GenSigSendType" SG_ 1174 Drv_SHVU_VntSwMidIndSta_RHD 4;
BA_ "UserSigValidity" SG_ 1174 Drv_SHVU_VntSwMidIndSta_RHD 3;
BA_REL_ "GenSigTimeoutTime" BU_SG_REL_ CGW_CCU SG_ 1174 Drv_SHVU_VntSwMidIndSta_RHD 1500;
BA_ "NetworkRequest" SG_ 1174 Drv_SHVU_VntSwMidIndSta_RHD 0;
BA_ "NetworkRequestHoldingTime" SG_ 1174 Drv_SHVU_VntSwMidIndSta_RHD 5000;
BA_ "Version" SG_ 1174 Drv_SHVU_VntSwMidIndSta_RHD "19.01.04";
BA_ "Description" SG_ 1174 Drv_SHVU_VntSwLowIndSta_RHD "운전석 시트 통풍 스위치 Low Indicator 정보(RHD)";
BA_ "GenSigSendType" SG_ 1174 Drv_SHVU_VntSwLowIndSta_RHD 4;
BA_ "UserSigValidity" SG_ 1174 Drv_SHVU_VntSwLowIndSta_RHD 3;
BA_REL_ "GenSigTimeoutTime" BU_SG_REL_ CGW_CCU SG_ 1174 Drv_SHVU_VntSwLowIndSta_RHD 1500;
BA_ "NetworkRequest" SG_ 1174 Drv_SHVU_VntSwLowIndSta_RHD 0;
BA_ "NetworkRequestHoldingTime" SG_ 1174 Drv_SHVU_VntSwLowIndSta_RHD 5000;
BA_ "Version" SG_ 1174 Drv_SHVU_VntSwLowIndSta_RHD "19.01.04";
BA_ "GenMsgCycleTime" BO_ 754 0;
BA_ "Description" SG_ 754 FPM2IAU_EncryptedData1 "This signal is for a send enrypted result of FPM.";
BA_ "GenSigSendType" SG_ 754 FPM2IAU_EncryptedData1 4;
BA_ "UserSigValidity" SG_ 754 FPM2IAU_EncryptedData1 0;
BA_REL_ "GenSigTimeoutTime" BU_SG_REL_ CGW_CCU SG_ 754 FPM2IAU_EncryptedData1 0;
BA_ "NetworkRequest" SG_ 754 FPM2IAU_EncryptedData1 0;
BA_ "NetworkRequestHoldingTime" SG_ 754 FPM2IAU_EncryptedData1 5000;
BA_ "Version" SG_ 754 FPM2IAU_EncryptedData1 "20.03.07";
BA_ "GenMsgCycleTime" BO_ 755 0;
BA_ "GenSigSendType" SG_ 755 FPM2IAU_EncryptedData2 4;
BA_ "UserSigValidity" SG_ 755 FPM2IAU_EncryptedData2 0;
BA_REL_ "GenSigTimeoutTime" BU_SG_REL_ CGW_CCU SG_ 755 FPM2IAU_EncryptedData2 0;
BA_ "NetworkRequest" SG_ 755 FPM2IAU_EncryptedData2 0;
BA_ "NetworkRequestHoldingTime" SG_ 755 FPM2IAU_EncryptedData2 5000;
BA_ "Version" SG_ 755 FPM2IAU_EncryptedData2 "20.03.07";
BA_ "GenMsgCycleTime" BO_ 756 0;
BA_ "Description" SG_ 756 FPM_FOBSrch "Fob search req to IAU";
BA_ "GenSigSendType" SG_ 756 FPM_FOBSrch 4;
BA_ "UserSigValidity" SG_ 756 FPM_FOBSrch 0;
BA_REL_ "GenSigTimeoutTime" BU_SG_REL_ CGW_CCU SG_ 756 FPM_FOBSrch 0;
BA_ "Version" SG_ 756 FPM_FOBSrch "20.05.02";
BA_ "Description" SG_ 756 FPM2IAU_RndNum "FPM Random Number";
BA_ "GenSigSendType" SG_ 756 FPM2IAU_RndNum 4;
BA_ "UserSigValidity" SG_ 756 FPM2IAU_RndNum 0;
BA_REL_ "GenSigTimeoutTime" BU_SG_REL_ CGW_CCU SG_ 756 FPM2IAU_RndNum 0;
BA_ "NetworkRequest" SG_ 756 FPM2IAU_RndNum 0;
BA_ "NetworkRequestHoldingTime" SG_ 756 FPM2IAU_RndNum 5000;
BA_ "Version" SG_ 756 FPM2IAU_RndNum "20.05.02";
BA_ "GenMsgCycleTime" BO_ 2563125505 0;
BA_ "VFrameFormat" BO_ 2563125505 1;
BA_ "Description" SG_ 2563125505 AMP_WrnPromptMode "This signal is used for sending set information of Warning Prompt Mode to AMP";
BA_ "GenSigSendType" SG_ 2563125505 AMP_WrnPromptMode 4;
BA_ "GenSigStartValue" SG_ 2563125505 AMP_WrnPromptMode 3;
BA_ "UserSigValidity" SG_ 2563125505 AMP_WrnPromptMode 0;
BA_REL_ "GenSigTimeoutTime" BU_SG_REL_ AMP SG_ 2563125505 AMP_WrnPromptMode 0;
BA_ "Version" SG_ 2563125505 AMP_WrnPromptMode "19.02.07";
BA_ "GenSigSendType" SG_ 2563125505 AMP_SPDIFMute 4;
BA_ "GenSigStartValue" SG_ 2563125505 AMP_SPDIFMute 1;
BA_ "UserSigValidity" SG_ 2563125505 AMP_SPDIFMute 1;
BA_REL_ "GenSigTimeoutTime" BU_SG_REL_ AMP SG_ 2563125505 AMP_SPDIFMute 0;
BA_ "NetworkRequest" SG_ 2563125505 AMP_SPDIFMute 0;
BA_ "Version" SG_ 2563125505 AMP_SPDIFMute "18.12.06";
BA_ "GenSigSendType" SG_ 2563125505 AMP_Reset 4;
BA_ "GenSigStartValue" SG_ 2563125505 AMP_Reset 3;
BA_ "UserSigValidity" SG_ 2563125505 AMP_Reset 1;
BA_REL_ "GenSigTimeoutTime" BU_SG_REL_ AMP SG_ 2563125505 AMP_Reset 0;
BA_ "Version" SG_ 2563125505 AMP_Reset "18.12.06";
BA_ "GenSigSendType" SG_ 2563125505 AMP_QuietMode 4;
BA_ "GenSigStartValue" SG_ 2563125505 AMP_QuietMode 3;
BA_ "UserSigValidity" SG_ 2563125505 AMP_QuietMode 1;
BA_REL_ "GenSigTimeoutTime" BU_SG_REL_ AMP SG_ 2563125505 AMP_QuietMode 0;
BA_ "Version" SG_ 2563125505 AMP_QuietMode "18.12.06";
BA_ "GenSigSendType" SG_ 2563125505 AMP_DSCMode 4;
BA_ "GenSigStartValue" SG_ 2563125505 AMP_DSCMode 3;
BA_ "UserSigValidity" SG_ 2563125505 AMP_DSCMode 1;
BA_REL_ "GenSigTimeoutTime" BU_SG_REL_ AMP SG_ 2563125505 AMP_DSCMode 0;
BA_ "Version" SG_ 2563125505 AMP_DSCMode "18.12.06";
BA_ "GenSigSendType" SG_ 2563125505 AMP_RANCMode 4;
BA_ "UserSigValidity" SG_ 2563125505 AMP_RANCMode 1;
BA_REL_ "GenSigTimeoutTime" BU_SG_REL_ AMP SG_ 2563125505 AMP_RANCMode 0;
BA_ "Version" SG_ 2563125505 AMP_RANCMode "18.12.06";
BA_ "GenSigSendType" SG_ 2563125505 AMP_CenterpointMode 4;
BA_ "GenSigStartValue" SG_ 2563125505 AMP_CenterpointMode 3;
BA_ "UserSigValidity" SG_ 2563125505 AMP_CenterpointMode 1;
BA_REL_ "GenSigTimeoutTime" BU_SG_REL_ AMP SG_ 2563125505 AMP_CenterpointMode 0;
BA_ "Version" SG_ 2563125505 AMP_CenterpointMode "18.12.06";
BA_ "GenSigSendType" SG_ 2563125505 AMP_QLSMode 4;
BA_ "GenSigStartValue" SG_ 2563125505 AMP_QLSMode 3;
BA_ "UserSigValidity" SG_ 2563125505 AMP_QLSMode 1;
BA_REL_ "GenSigTimeoutTime" BU_SG_REL_ AMP SG_ 2563125505 AMP_QLSMode 0;
BA_ "Version" SG_ 2563125505 AMP_QLSMode "18.12.06";
BA_ "GenSigSendType" SG_ 2563125505 AMP_VIPMode 4;
BA_ "GenSigStartValue" SG_ 2563125505 AMP_VIPMode 3;
BA_ "UserSigValidity" SG_ 2563125505 AMP_VIPMode 1;
BA_REL_ "GenSigTimeoutTime" BU_SG_REL_ AMP SG_ 2563125505 AMP_VIPMode 0;
BA_ "Version" SG_ 2563125505 AMP_VIPMode "18.12.06";
BA_ "GenSigSendType" SG_ 2563125505 AMP_LiveDynamicMode 4;
BA_ "GenSigStartValue" SG_ 2563125505 AMP_LiveDynamicMode 7;
BA_ "UserSigValidity" SG_ 2563125505 AMP_LiveDynamicMode 1;
BA_ "NetworkRequest" SG_ 2563125505 AMP_LiveDynamicMode 0;
BA_ "Version" SG_ 2563125505 AMP_LiveDynamicMode "18.12.06";
BA_ "GenSigSendType" SG_ 2563125505 AMP_BASSMode 4;
BA_ "GenSigStartValue" SG_ 2563125505 AMP_BASSMode 3;
BA_ "UserSigValidity" SG_ 2563125505 AMP_BASSMode 1;
BA_ "Version" SG_ 2563125505 AMP_BASSMode "18.12.06";
BA_ "GenSigSendType" SG_ 2563125505 AMP_CabinTalkMode 4;
BA_ "GenSigStartValue" SG_ 2563125505 AMP_CabinTalkMode 3;
BA_ "UserSigValidity" SG_ 2563125505 AMP_CabinTalkMode 1;
BA_ "Version" SG_ 2563125505 AMP_CabinTalkMode "18.12.06";
BA_ "Description" SG_ 2563125505 AMP_SiriMode "The signal is the Siri Mode On/Off from HU to AMP";
BA_ "GenSigSendType" SG_ 2563125505 AMP_SiriMode 4;
BA_ "GenSigStartValue" SG_ 2563125505 AMP_SiriMode 3;
BA_ "UserSigValidity" SG_ 2563125505 AMP_SiriMode 1;
BA_REL_ "GenSigTimeoutTime" BU_SG_REL_ AMP SG_ 2563125505 AMP_SiriMode 0;
BA_ "Version" SG_ 2563125505 AMP_SiriMode "20.04.02";
BA_ "Description" SG_ 2563125505 AMP_Mute "1.08.00_";
BA_ "GenSigSendType" SG_ 2563125505 AMP_Mute 4;
BA_ "GenSigStartValue" SG_ 2563125505 AMP_Mute 3;
BA_ "UserSigValidity" SG_ 2563125505 AMP_Mute 1;
BA_REL_ "GenSigTimeoutTime" BU_SG_REL_ AMP SG_ 2563125505 AMP_Mute 0;
BA_ "NetworkRequest" SG_ 2563125505 AMP_Mute 0;
BA_ "Version" SG_ 2563125505 AMP_Mute "18.12.06";
BA_ "GenSigSendType" SG_ 2563125505 AMP_AudioMode 4;
BA_ "GenSigStartValue" SG_ 2563125505 AMP_AudioMode 255;
BA_ "UserSigValidity" SG_ 2563125505 AMP_AudioMode 1;
BA_REL_ "GenSigTimeoutTime" BU_SG_REL_ AMP SG_ 2563125505 AMP_AudioMode 0;
BA_ "NetworkRequest" SG_ 2563125505 AMP_AudioMode 0;
BA_ "Version" SG_ 2563125505 AMP_AudioMode "19.08.08";
BA_ "GenMsgCycleTime" BO_ 2563127041 0;
BA_ "VFrameFormat" BO_ 2563127041 1;
BA_ "GenSigSendType" SG_ 2563127041 AMP_MainVolumeSet 4;
BA_ "GenSigStartValue" SG_ 2563127041 AMP_MainVolumeSet 255;
BA_ "UserSigValidity" SG_ 2563127041 AMP_MainVolumeSet 1;
BA_REL_ "GenSigTimeoutTime" BU_SG_REL_ AMP SG_ 2563127041 AMP_MainVolumeSet 0;
BA_ "NetworkRequest" SG_ 2563127041 AMP_MainVolumeSet 0;
BA_ "Version" SG_ 2563127041 AMP_MainVolumeSet "18.12.06";
BA_ "GenSigSendType" SG_ 2563127041 AMP_FadeSet 4;
BA_ "GenSigStartValue" SG_ 2563127041 AMP_FadeSet 255;
BA_ "UserSigValidity" SG_ 2563127041 AMP_FadeSet 1;
BA_REL_ "GenSigTimeoutTime" BU_SG_REL_ AMP SG_ 2563127041 AMP_FadeSet 0;
BA_ "NetworkRequest" SG_ 2563127041 AMP_FadeSet 0;
BA_ "Version" SG_ 2563127041 AMP_FadeSet "18.12.06";
BA_ "GenSigSendType" SG_ 2563127041 AMP_BassSet 4;
BA_ "GenSigStartValue" SG_ 2563127041 AMP_BassSet 255;
BA_ "UserSigValidity" SG_ 2563127041 AMP_BassSet 1;
BA_REL_ "GenSigTimeoutTime" BU_SG_REL_ AMP SG_ 2563127041 AMP_BassSet 0;
BA_ "NetworkRequest" SG_ 2563127041 AMP_BassSet 0;
BA_ "Version" SG_ 2563127041 AMP_BassSet "18.12.06";
BA_ "GenSigSendType" SG_ 2563127041 AMP_MidSet 4;
BA_ "GenSigStartValue" SG_ 2563127041 AMP_MidSet 255;
BA_ "UserSigValidity" SG_ 2563127041 AMP_MidSet 1;
BA_REL_ "GenSigTimeoutTime" BU_SG_REL_ AMP SG_ 2563127041 AMP_MidSet 0;
BA_ "NetworkRequest" SG_ 2563127041 AMP_MidSet 0;
BA_ "Version" SG_ 2563127041 AMP_MidSet "18.12.06";
BA_ "GenSigSendType" SG_ 2563127041 AMP_TrebleSet 4;
BA_ "GenSigStartValue" SG_ 2563127041 AMP_TrebleSet 255;
BA_ "UserSigValidity" SG_ 2563127041 AMP_TrebleSet 1;
BA_REL_ "GenSigTimeoutTime" BU_SG_REL_ AMP SG_ 2563127041 AMP_TrebleSet 0;
BA_ "NetworkRequest" SG_ 2563127041 AMP_TrebleSet 0;
BA_ "Version" SG_ 2563127041 AMP_TrebleSet "18.12.06";
BA_ "GenSigSendType" SG_ 2563127041 AMP_BalanceSet 4;
BA_ "GenSigStartValue" SG_ 2563127041 AMP_BalanceSet 255;
BA_ "UserSigValidity" SG_ 2563127041 AMP_BalanceSet 1;
BA_REL_ "GenSigTimeoutTime" BU_SG_REL_ AMP SG_ 2563127041 AMP_BalanceSet 0;
BA_ "NetworkRequest" SG_ 2563127041 AMP_BalanceSet 0;
BA_ "Version" SG_ 2563127041 AMP_BalanceSet "18.12.06";
BA_ "GenMsgSendType" BO_ 2567325441 0;
BA_ "VFrameFormat" BO_ 2567325441 1;
BA_ "Description" SG_ 2567325441 AMP_ADASVolumeStep "Volume signal for ADAS warning sound level";
BA_ "GenSigSendType" SG_ 2567325441 AMP_ADASVolumeStep 4;
BA_ "GenSigStartValue" SG_ 2567325441 AMP_ADASVolumeStep 15;
BA_ "UserSigValidity" SG_ 2567325441 AMP_ADASVolumeStep 1;
BA_REL_ "GenSigTimeoutTime" BU_SG_REL_ AMP SG_ 2567325441 AMP_ADASVolumeStep 1500;
BA_ "RoutingFactor" SG_ 2567325441 AMP_ADASVolumeStep 0;
BA_ "Version" SG_ 2567325441 AMP_ADASVolumeStep "21.05.03";
BA_ "Description" SG_ 2567325441 AMP_ADASVolumeFbk "Feedback signal for ADAS warning sound volume change";
BA_ "GenSigSendType" SG_ 2567325441 AMP_ADASVolumeFbk 4;
BA_ "UserSigValidity" SG_ 2567325441 AMP_ADASVolumeFbk 1;
BA_REL_ "GenSigTimeoutTime" BU_SG_REL_ AMP SG_ 2567325441 AMP_ADASVolumeFbk 1500;
BA_ "RoutingFactor" SG_ 2567325441 AMP_ADASVolumeFbk 0;
BA_ "Version" SG_ 2567325441 AMP_ADASVolumeFbk "21.05.03";
BA_ "GenMsgCycleTime" BO_ 2323817473 0;
BA_ "VFrameFormat" BO_ 2323817473 1;
BA_ "Description" SG_ 2323817473 C_DrAirSptNValueSet_EC "Driver Seat Smart Air Support On/Off";
BA_ "GenSigSendType" SG_ 2323817473 C_DrAirSptNValueSet_EC 4;
BA_ "UserSigValidity" SG_ 2323817473 C_DrAirSptNValueSet_EC 0;
BA_REL_ "GenSigTimeoutTime" BU_SG_REL_ DSAU SG_ 2323817473 C_DrAirSptNValueSet_EC 0;
BA_ "Version" SG_ 2323817473 C_DrAirSptNValueSet_EC "20.02.03";
BA_ "Description" SG_ 2323817473 C_DrCushSoftNValueSet_EC "Driver Seat Cushion Softness";
BA_ "GenSigSendType" SG_ 2323817473 C_DrCushSoftNValueSet_EC 4;
BA_ "UserSigValidity" SG_ 2323817473 C_DrCushSoftNValueSet_EC 0;
BA_REL_ "GenSigTimeoutTime" BU_SG_REL_ DSAU SG_ 2323817473 C_DrCushSoftNValueSet_EC 0;
BA_ "Version" SG_ 2323817473 C_DrCushSoftNValueSet_EC "20.02.03";
BA_ "Description" SG_ 2323817473 C_AstAirSptNValueSet_EC "Assistant Seat Smart Air Support On/Off";
BA_ "GenSigSendType" SG_ 2323817473 C_AstAirSptNValueSet_EC 4;
BA_ "UserSigValidity" SG_ 2323817473 C_AstAirSptNValueSet_EC 0;
BA_REL_ "GenSigTimeoutTime" BU_SG_REL_ ASAU SG_ 2323817473 C_AstAirSptNValueSet_EC 0;
BA_ "Version" SG_ 2323817473 C_AstAirSptNValueSet_EC "20.02.03";
BA_ "Description" SG_ 2323817473 C_DrBackSoftNValueSet_EC "Driver Seat Back Softness";
BA_ "GenSigSendType" SG_ 2323817473 C_DrBackSoftNValueSet_EC 4;
BA_ "UserSigValidity" SG_ 2323817473 C_DrBackSoftNValueSet_EC 0;
BA_REL_ "GenSigTimeoutTime" BU_SG_REL_ DSAU SG_ 2323817473 C_DrBackSoftNValueSet_EC 0;
BA_ "Version" SG_ 2323817473 C_DrBackSoftNValueSet_EC "20.02.03";
BA_ "Description" SG_ 2323817473 C_AstAirSptModeNValueSet_EC "Assistant Seat Smart Air Support Mode";
BA_ "GenSigSendType" SG_ 2323817473 C_AstAirSptModeNValueSet_EC 4;
BA_ "UserSigValidity" SG_ 2323817473 C_AstAirSptModeNValueSet_EC 0;
BA_REL_ "GenSigTimeoutTime" BU_SG_REL_ ASAU SG_ 2323817473 C_AstAirSptModeNValueSet_EC 0;
BA_ "Version" SG_ 2323817473 C_AstAirSptModeNValueSet_EC "20.02.03";
BA_ "Description" SG_ 2323817473 C_DrAirSptModeNValueSet_EC "Driver Seat Smart Air Support Mode";
BA_ "GenSigSendType" SG_ 2323817473 C_DrAirSptModeNValueSet_EC 4;
BA_ "UserSigValidity" SG_ 2323817473 C_DrAirSptModeNValueSet_EC 0;
BA_REL_ "GenSigTimeoutTime" BU_SG_REL_ DSAU SG_ 2323817473 C_DrAirSptModeNValueSet_EC 0;
BA_ "Version" SG_ 2323817473 C_DrAirSptModeNValueSet_EC "20.02.03";
BA_ "Description" SG_ 2323817473 C_RLAirSptNValueSet_EC "2nd Left Seat Smart Air Support On/Off";
BA_ "GenSigSendType" SG_ 2323817473 C_RLAirSptNValueSet_EC 4;
BA_ "UserSigValidity" SG_ 2323817473 C_RLAirSptNValueSet_EC 0;
BA_REL_ "GenSigTimeoutTime" BU_SG_REL_ RLPSM SG_ 2323817473 C_RLAirSptNValueSet_EC 0;
BA_REL_ "GenSigTimeoutTime" BU_SG_REL_ ATS SG_ 2323817473 C_RLAirSptNValueSet_EC 0;
BA_ "Version" SG_ 2323817473 C_RLAirSptNValueSet_EC "20.02.03";
BA_ "Description" SG_ 2323817473 C_AstAirSptStrNValueSet_EC "Assistant Seat Smart Air Support Strength";
BA_ "GenSigSendType" SG_ 2323817473 C_AstAirSptStrNValueSet_EC 4;
BA_ "UserSigValidity" SG_ 2323817473 C_AstAirSptStrNValueSet_EC 0;
BA_REL_ "GenSigTimeoutTime" BU_SG_REL_ ASAU SG_ 2323817473 C_AstAirSptStrNValueSet_EC 0;
BA_ "Version" SG_ 2323817473 C_AstAirSptStrNValueSet_EC "20.02.03";
BA_ "Description" SG_ 2323817473 C_AstAirSptTimeNValueSet_EC "Assistant Seat Smart Air Support Time";
BA_ "GenSigSendType" SG_ 2323817473 C_AstAirSptTimeNValueSet_EC 4;
BA_ "UserSigValidity" SG_ 2323817473 C_AstAirSptTimeNValueSet_EC 0;
BA_REL_ "GenSigTimeoutTime" BU_SG_REL_ ASAU SG_ 2323817473 C_AstAirSptTimeNValueSet_EC 0;
BA_ "Version" SG_ 2323817473 C_AstAirSptTimeNValueSet_EC "20.02.03";
BA_ "Description" SG_ 2323817473 C_RRAirSptNValueSet_EC "2nd Right side seat Smart Air Support On/Off";
BA_ "GenSigSendType" SG_ 2323817473 C_RRAirSptNValueSet_EC 4;
BA_ "UserSigValidity" SG_ 2323817473 C_RRAirSptNValueSet_EC 0;
BA_REL_ "GenSigTimeoutTime" BU_SG_REL_ RLPSM SG_ 2323817473 C_RRAirSptNValueSet_EC 0;
BA_REL_ "GenSigTimeoutTime" BU_SG_REL_ ATS SG_ 2323817473 C_RRAirSptNValueSet_EC 0;
BA_ "Version" SG_ 2323817473 C_RRAirSptNValueSet_EC "20.02.03";
BA_ "Description" SG_ 2323817473 C_AstCushSoftNValueSet_EC "Assistant Seat Cushion Softness off/low/mid/high";
BA_ "GenSigSendType" SG_ 2323817473 C_AstCushSoftNValueSet_EC 4;
BA_ "UserSigValidity" SG_ 2323817473 C_AstCushSoftNValueSet_EC 0;
BA_REL_ "GenSigTimeoutTime" BU_SG_REL_ ASAU SG_ 2323817473 C_AstCushSoftNValueSet_EC 0;
BA_ "Version" SG_ 2323817473 C_AstCushSoftNValueSet_EC "20.02.03";
BA_ "Description" SG_ 2323817473 C_AstBackSoftNValueSet_EC "Assistant Seat Back Softness Off/Low/Mid/High";
BA_ "GenSigSendType" SG_ 2323817473 C_AstBackSoftNValueSet_EC 4;
BA_ "UserSigValidity" SG_ 2323817473 C_AstBackSoftNValueSet_EC 0;
BA_REL_ "GenSigTimeoutTime" BU_SG_REL_ ASAU SG_ 2323817473 C_AstBackSoftNValueSet_EC 0;
BA_ "Version" SG_ 2323817473 C_AstBackSoftNValueSet_EC "20.02.03";
BA_ "Description" SG_ 2323817473 C_RRFootAirSptNValueSet_EC "2nd Right side seat Foot Air Support On/Off";
BA_ "GenSigSendType" SG_ 2323817473 C_RRFootAirSptNValueSet_EC 4;
BA_ "UserSigValidity" SG_ 2323817473 C_RRFootAirSptNValueSet_EC 0;
BA_REL_ "GenSigTimeoutTime" BU_SG_REL_ RLPSM SG_ 2323817473 C_RRFootAirSptNValueSet_EC 0;
BA_REL_ "GenSigTimeoutTime" BU_SG_REL_ ATS SG_ 2323817473 C_RRFootAirSptNValueSet_EC 0;
BA_REL_ "GenSigTimeoutTime" BU_SG_REL_ ASAU SG_ 2323817473 C_RRFootAirSptNValueSet_EC 0;
BA_ "Version" SG_ 2323817473 C_RRFootAirSptNValueSet_EC "20.02.03";
BA_ "Description" SG_ 2323817473 C_RLAirSptModeNValueSet_EC "2nd Left Seat Smart Air Support Mode";
BA_ "GenSigSendType" SG_ 2323817473 C_RLAirSptModeNValueSet_EC 4;
BA_ "UserSigValidity" SG_ 2323817473 C_RLAirSptModeNValueSet_EC 0;
BA_REL_ "GenSigTimeoutTime" BU_SG_REL_ RLPSM SG_ 2323817473 C_RLAirSptModeNValueSet_EC 0;
BA_REL_ "GenSigTimeoutTime" BU_SG_REL_ ATS SG_ 2323817473 C_RLAirSptModeNValueSet_EC 0;
BA_ "Version" SG_ 2323817473 C_RLAirSptModeNValueSet_EC "20.02.03";
BA_ "Description" SG_ 2323817473 C_RLSeatHtOperNValueSet_EC "2nd Left side seat Heating/Ventilation switch: Vent low/mid/high, Heater low/mid/high";
BA_ "GenSigSendType" SG_ 2323817473 C_RLSeatHtOperNValueSet_EC 4;
BA_ "UserSigValidity" SG_ 2323817473 C_RLSeatHtOperNValueSet_EC 0;
BA_REL_ "GenSigTimeoutTime" BU_SG_REL_ RLHV SG_ 2323817473 C_RLSeatHtOperNValueSet_EC 0;
BA_ "Version" SG_ 2323817473 C_RLSeatHtOperNValueSet_EC "20.02.03";
BA_ "Description" SG_ 2323817473 C_DrAirSptStrNValueSet_EC "Driver Seat Smart Air Support Strength";
BA_ "GenSigSendType" SG_ 2323817473 C_DrAirSptStrNValueSet_EC 4;
BA_ "UserSigValidity" SG_ 2323817473 C_DrAirSptStrNValueSet_EC 0;
BA_REL_ "GenSigTimeoutTime" BU_SG_REL_ DSAU SG_ 2323817473 C_DrAirSptStrNValueSet_EC 0;
BA_ "Version" SG_ 2323817473 C_DrAirSptStrNValueSet_EC "20.02.03";
BA_ "Description" SG_ 2323817473 C_RRSeatHtOperNValueSet_EC "2nd Right side seat Heating/Ventilation switch: Vent low, Vent Mid, Vent High , Heater Low, Heater Mid, Heater High";
BA_ "GenSigSendType" SG_ 2323817473 C_RRSeatHtOperNValueSet_EC 4;
BA_ "UserSigValidity" SG_ 2323817473 C_RRSeatHtOperNValueSet_EC 0;
BA_REL_ "GenSigTimeoutTime" BU_SG_REL_ RRHV SG_ 2323817473 C_RRSeatHtOperNValueSet_EC 0;
BA_ "Version" SG_ 2323817473 C_RRSeatHtOperNValueSet_EC "20.02.03";
BA_ "Description" SG_ 2323817473 C_RLAirSptStrNValueSet_EC "2nd Left Seat Smart Air Support Strength";
BA_ "GenSigSendType" SG_ 2323817473 C_RLAirSptStrNValueSet_EC 4;
BA_ "UserSigValidity" SG_ 2323817473 C_RLAirSptStrNValueSet_EC 0;
BA_REL_ "GenSigTimeoutTime" BU_SG_REL_ RLPSM SG_ 2323817473 C_RLAirSptStrNValueSet_EC 0;
BA_REL_ "GenSigTimeoutTime" BU_SG_REL_ ATS SG_ 2323817473 C_RLAirSptStrNValueSet_EC 0;
BA_ "Version" SG_ 2323817473 C_RLAirSptStrNValueSet_EC "20.02.03";
BA_ "Description" SG_ 2323817473 C_RLAirSptTimeNValueSet_EC "2nd Left Seat Smart Air Support Time";
BA_ "GenSigSendType" SG_ 2323817473 C_RLAirSptTimeNValueSet_EC 4;
BA_ "UserSigValidity" SG_ 2323817473 C_RLAirSptTimeNValueSet_EC 0;
BA_REL_ "GenSigTimeoutTime" BU_SG_REL_ RLPSM SG_ 2323817473 C_RLAirSptTimeNValueSet_EC 0;
BA_REL_ "GenSigTimeoutTime" BU_SG_REL_ ATS SG_ 2323817473 C_RLAirSptTimeNValueSet_EC 0;
BA_ "Version" SG_ 2323817473 C_RLAirSptTimeNValueSet_EC "20.02.03";
BA_ "Description" SG_ 2323817473 C_DrAirSptTimeNValueSet_EC "Driver Seat Smart Air Support Time";
BA_ "GenSigSendType" SG_ 2323817473 C_DrAirSptTimeNValueSet_EC 4;
BA_ "UserSigValidity" SG_ 2323817473 C_DrAirSptTimeNValueSet_EC 0;
BA_REL_ "GenSigTimeoutTime" BU_SG_REL_ DSAU SG_ 2323817473 C_DrAirSptTimeNValueSet_EC 0;
BA_ "Version" SG_ 2323817473 C_DrAirSptTimeNValueSet_EC "20.02.03";
BA_ "GenMsgSendType" BO_ 2298626561 0;
BA_ "VFrameFormat" BO_ 2298626561 1;
BA_ "GenSigSendType" SG_ 2298626561 C_RRLegSupFwdSw_HU 4;
BA_ "UserSigValidity" SG_ 2298626561 C_RRLegSupFwdSw_HU 0;
BA_REL_ "GenSigTimeoutTime" BU_SG_REL_ RRPSM SG_ 2298626561 C_RRLegSupFwdSw_HU 1500;
BA_ "Version" SG_ 2298626561 C_RRLegSupFwdSw_HU "19.11.09";
BA_ "GenSigSendType" SG_ 2298626561 C_RRHrestDnSw_HU 4;
BA_ "UserSigValidity" SG_ 2298626561 C_RRHrestDnSw_HU 0;
BA_REL_ "GenSigTimeoutTime" BU_SG_REL_ RRPSM SG_ 2298626561 C_RRHrestDnSw_HU 1500;
BA_ "Version" SG_ 2298626561 C_RRHrestDnSw_HU "19.11.09";
BA_ "GenSigSendType" SG_ 2298626561 C_RRHrestFwdSw_HU 4;
BA_ "UserSigValidity" SG_ 2298626561 C_RRHrestFwdSw_HU 0;
BA_REL_ "GenSigTimeoutTime" BU_SG_REL_ RRPSM SG_ 2298626561 C_RRHrestFwdSw_HU 1500;
BA_ "Version" SG_ 2298626561 C_RRHrestFwdSw_HU "19.11.09";
BA_ "GenSigSendType" SG_ 2298626561 C_RRHrestBwdSw_HU 4;
BA_ "UserSigValidity" SG_ 2298626561 C_RRHrestBwdSw_HU 0;
BA_REL_ "GenSigTimeoutTime" BU_SG_REL_ RRPSM SG_ 2298626561 C_RRHrestBwdSw_HU 1500;
BA_ "Version" SG_ 2298626561 C_RRHrestBwdSw_HU "19.11.09";
BA_ "GenSigSendType" SG_ 2298626561 C_RRLumbarUpSw_HU 4;
BA_ "UserSigValidity" SG_ 2298626561 C_RRLumbarUpSw_HU 0;
BA_REL_ "GenSigTimeoutTime" BU_SG_REL_ RLPSM SG_ 2298626561 C_RRLumbarUpSw_HU 1500;
BA_ "Version" SG_ 2298626561 C_RRLumbarUpSw_HU "19.11.09";
BA_ "GenSigSendType" SG_ 2298626561 C_RRLumbarMidSw_HU 4;
BA_ "UserSigValidity" SG_ 2298626561 C_RRLumbarMidSw_HU 0;
BA_REL_ "GenSigTimeoutTime" BU_SG_REL_ RLPSM SG_ 2298626561 C_RRLumbarMidSw_HU 1500;
BA_ "Version" SG_ 2298626561 C_RRLumbarMidSw_HU "19.11.09";
BA_ "GenSigSendType" SG_ 2298626561 C_RRLegSupBwdSw_HU 4;
BA_ "UserSigValidity" SG_ 2298626561 C_RRLegSupBwdSw_HU 0;
BA_REL_ "GenSigTimeoutTime" BU_SG_REL_ RRPSM SG_ 2298626561 C_RRLegSupBwdSw_HU 1500;
BA_ "Version" SG_ 2298626561 C_RRLegSupBwdSw_HU "19.11.09";
BA_ "GenSigSendType" SG_ 2298626561 C_RRLumbarLowSw_HU 4;
BA_ "UserSigValidity" SG_ 2298626561 C_RRLumbarLowSw_HU 0;
BA_REL_ "GenSigTimeoutTime" BU_SG_REL_ RLPSM SG_ 2298626561 C_RRLumbarLowSw_HU 1500;
BA_ "Version" SG_ 2298626561 C_RRLumbarLowSw_HU "19.11.09";
BA_ "GenSigSendType" SG_ 2298626561 C_RRLumbarDefSw_HU 4;
BA_ "UserSigValidity" SG_ 2298626561 C_RRLumbarDefSw_HU 0;
BA_REL_ "GenSigTimeoutTime" BU_SG_REL_ RLPSM SG_ 2298626561 C_RRLumbarDefSw_HU 1500;
BA_ "Version" SG_ 2298626561 C_RRLumbarDefSw_HU "19.11.09";
BA_ "GenSigSendType" SG_ 2298626561 C_RRBolsterInfSw_HU 4;
BA_ "UserSigValidity" SG_ 2298626561 C_RRBolsterInfSw_HU 0;
BA_REL_ "GenSigTimeoutTime" BU_SG_REL_ RLPSM SG_ 2298626561 C_RRBolsterInfSw_HU 1500;
BA_ "Version" SG_ 2298626561 C_RRBolsterInfSw_HU "19.11.09";
BA_ "GenSigSendType" SG_ 2298626561 C_RRLegSupUpSw_HU 4;
BA_ "UserSigValidity" SG_ 2298626561 C_RRLegSupUpSw_HU 0;
BA_REL_ "GenSigTimeoutTime" BU_SG_REL_ RRPSM SG_ 2298626561 C_RRLegSupUpSw_HU 1500;
BA_ "Version" SG_ 2298626561 C_RRLegSupUpSw_HU "19.11.09";
BA_ "GenSigSendType" SG_ 2298626561 C_RROneTchNValueSet 4;
BA_ "UserSigValidity" SG_ 2298626561 C_RROneTchNValueSet 0;
BA_REL_ "GenSigTimeoutTime" BU_SG_REL_ RLPSM SG_ 2298626561 C_RROneTchNValueSet 1500;
BA_REL_ "GenSigTimeoutTime" BU_SG_REL_ RRPSM SG_ 2298626561 C_RROneTchNValueSet 1500;
BA_REL_ "GenSigTimeoutTime" BU_SG_REL_ ATS SG_ 2298626561 C_RROneTchNValueSet 1500;
BA_ "Version" SG_ 2298626561 C_RROneTchNValueSet "19.11.09";
BA_ "GenSigSendType" SG_ 2298626561 C_RLOneTchNValueSet 4;
BA_ "UserSigValidity" SG_ 2298626561 C_RLOneTchNValueSet 0;
BA_REL_ "GenSigTimeoutTime" BU_SG_REL_ RLPSM SG_ 2298626561 C_RLOneTchNValueSet 1500;
BA_REL_ "GenSigTimeoutTime" BU_SG_REL_ RRPSM SG_ 2298626561 C_RLOneTchNValueSet 1500;
BA_REL_ "GenSigTimeoutTime" BU_SG_REL_ ATS SG_ 2298626561 C_RLOneTchNValueSet 1500;
BA_ "Version" SG_ 2298626561 C_RLOneTchNValueSet "19.11.09";
BA_ "GenSigSendType" SG_ 2298626561 C_RRBolsterDefSw_HU 4;
BA_ "UserSigValidity" SG_ 2298626561 C_RRBolsterDefSw_HU 0;
BA_REL_ "GenSigTimeoutTime" BU_SG_REL_ RLPSM SG_ 2298626561 C_RRBolsterDefSw_HU 1500;
BA_ "Version" SG_ 2298626561 C_RRBolsterDefSw_HU "19.11.09";
BA_ "GenSigSendType" SG_ 2298626561 C_RLRSEUpSw_HU 4;
BA_ "UserSigValidity" SG_ 2298626561 C_RLRSEUpSw_HU 0;
BA_REL_ "GenSigTimeoutTime" BU_SG_REL_ PSM SG_ 2298626561 C_RLRSEUpSw_HU 1500;
BA_ "Version" SG_ 2298626561 C_RLRSEUpSw_HU "19.12.02";
BA_ "GenSigSendType" SG_ 2298626561 C_RLRSEDnSw_HU 4;
BA_ "UserSigValidity" SG_ 2298626561 C_RLRSEDnSw_HU 0;
BA_REL_ "GenSigTimeoutTime" BU_SG_REL_ PSM SG_ 2298626561 C_RLRSEDnSw_HU 1500;
BA_ "Version" SG_ 2298626561 C_RLRSEDnSw_HU "19.12.02";
BA_ "GenSigSendType" SG_ 2298626561 C_RRRSEUpSw_HU 4;
BA_ "UserSigValidity" SG_ 2298626561 C_RRRSEUpSw_HU 0;
BA_REL_ "GenSigTimeoutTime" BU_SG_REL_ APSM SG_ 2298626561 C_RRRSEUpSw_HU 1500;
BA_ "Version" SG_ 2298626561 C_RRRSEUpSw_HU "19.12.02";
BA_ "GenSigSendType" SG_ 2298626561 C_RRLegSupDnSw_HU 4;
BA_ "UserSigValidity" SG_ 2298626561 C_RRLegSupDnSw_HU 0;
BA_REL_ "GenSigTimeoutTime" BU_SG_REL_ RRPSM SG_ 2298626561 C_RRLegSupDnSw_HU 1500;
BA_ "Version" SG_ 2298626561 C_RRLegSupDnSw_HU "19.11.09";
BA_ "GenSigSendType" SG_ 2298626561 C_RRRSEDnSw_HU 4;
BA_ "UserSigValidity" SG_ 2298626561 C_RRRSEDnSw_HU 0;
BA_REL_ "GenSigTimeoutTime" BU_SG_REL_ APSM SG_ 2298626561 C_RRRSEDnSw_HU 1500;
BA_ "Version" SG_ 2298626561 C_RRRSEDnSw_HU "19.12.02";
BA_ "GenSigSendType" SG_ 2298626561 C_RRHrestUpSw_HU 4;
BA_ "UserSigValidity" SG_ 2298626561 C_RRHrestUpSw_HU 0;
BA_REL_ "GenSigTimeoutTime" BU_SG_REL_ RRPSM SG_ 2298626561 C_RRHrestUpSw_HU 1500;
BA_ "Version" SG_ 2298626561 C_RRHrestUpSw_HU "19.11.09";
BA_ "GenMsgSendType" BO_ 2479157249 0;
BA_ "GenMsgCycleTime" BO_ 2479157249 1000;
BA_ "VFrameFormat" BO_ 2479157249 1;
BA_ "GenSigSendType" SG_ 2479157249 HU_TimeSetting 4;
BA_ "GenSigStartValue" SG_ 2479157249 HU_TimeSetting 3;
BA_ "UserSigValidity" SG_ 2479157249 HU_TimeSetting 0;
BA_REL_ "GenSigTimeoutTime" BU_SG_REL_ ATS SG_ 2479157249 HU_TimeSetting 5000;
BA_ "NetworkRequest" SG_ 2479157249 HU_TimeSetting 0;
BA_ "Version" SG_ 2479157249 HU_TimeSetting "18.09.02";
BA_ "GenSigSendType" SG_ 2479157249 HU_DisplayMinute 4;
BA_ "GenSigStartValue" SG_ 2479157249 HU_DisplayMinute 255;
BA_ "UserSigValidity" SG_ 2479157249 HU_DisplayMinute 0;
BA_REL_ "GenSigTimeoutTime" BU_SG_REL_ ATS SG_ 2479157249 HU_DisplayMinute 5000;
BA_ "NetworkRequest" SG_ 2479157249 HU_DisplayMinute 0;
BA_ "NetworkRequestHoldingTime" SG_ 2479157249 HU_DisplayMinute 200;
BA_ "Version" SG_ 2479157249 HU_DisplayMinute "21.07.07";
BA_ "GenSigSendType" SG_ 2479157249 HU_Status 4;
BA_ "GenSigStartValue" SG_ 2479157249 HU_Status 15;
BA_ "UserSigValidity" SG_ 2479157249 HU_Status 0;
BA_REL_ "GenSigTimeoutTime" BU_SG_REL_ ATS SG_ 2479157249 HU_Status 5000;
BA_ "NetworkRequest" SG_ 2479157249 HU_Status 0;
BA_ "NetworkRequestHoldingTime" SG_ 2479157249 HU_Status 200;
BA_ "Version" SG_ 2479157249 HU_Status "21.07.07";
BA_ "GenSigSendType" SG_ 2479157249 HU_DisplaySecond 4;
BA_ "GenSigStartValue" SG_ 2479157249 HU_DisplaySecond 255;
BA_ "UserSigValidity" SG_ 2479157249 HU_DisplaySecond 0;
BA_REL_ "GenSigTimeoutTime" BU_SG_REL_ ATS SG_ 2479157249 HU_DisplaySecond 5000;
BA_ "NetworkRequest" SG_ 2479157249 HU_DisplaySecond 0;
BA_ "NetworkRequestHoldingTime" SG_ 2479157249 HU_DisplaySecond 200;
BA_ "Version" SG_ 2479157249 HU_DisplaySecond "21.07.07";
BA_ "GenSigSendType" SG_ 2479157249 HU_DisplayMonth 4;
BA_ "GenSigStartValue" SG_ 2479157249 HU_DisplayMonth 15;
BA_ "UserSigValidity" SG_ 2479157249 HU_DisplayMonth 0;
BA_REL_ "GenSigTimeoutTime" BU_SG_REL_ ATS SG_ 2479157249 HU_DisplayMonth 5000;
BA_ "NetworkRequest" SG_ 2479157249 HU_DisplayMonth 0;
BA_ "NetworkRequestHoldingTime" SG_ 2479157249 HU_DisplayMonth 200;
BA_ "Version" SG_ 2479157249 HU_DisplayMonth "21.07.07";
BA_ "GenSigSendType" SG_ 2479157249 HU_DisplayYear1 4;
BA_ "GenSigStartValue" SG_ 2479157249 HU_DisplayYear1 3;
BA_ "UserSigValidity" SG_ 2479157249 HU_DisplayYear1 0;
BA_REL_ "GenSigTimeoutTime" BU_SG_REL_ ATS SG_ 2479157249 HU_DisplayYear1 5000;
BA_ "NetworkRequest" SG_ 2479157249 HU_DisplayYear1 0;
BA_ "Version" SG_ 2479157249 HU_DisplayYear1 "18.09.02";
BA_ "GenSigSendType" SG_ 2479157249 HU_DisplayYear2 4;
BA_ "GenSigStartValue" SG_ 2479157249 HU_DisplayYear2 255;
BA_ "UserSigValidity" SG_ 2479157249 HU_DisplayYear2 0;
BA_REL_ "GenSigTimeoutTime" BU_SG_REL_ ATS SG_ 2479157249 HU_DisplayYear2 5000;
BA_ "NetworkRequest" SG_ 2479157249 HU_DisplayYear2 0;
BA_ "NetworkRequestHoldingTime" SG_ 2479157249 HU_DisplayYear2 200;
BA_ "Version" SG_ 2479157249 HU_DisplayYear2 "21.07.07";
BA_ "GenSigSendType" SG_ 2479157249 HU_DisplayDay 4;
BA_ "GenSigStartValue" SG_ 2479157249 HU_DisplayDay 255;
BA_ "UserSigValidity" SG_ 2479157249 HU_DisplayDay 0;
BA_REL_ "GenSigTimeoutTime" BU_SG_REL_ ATS SG_ 2479157249 HU_DisplayDay 5000;
BA_ "NetworkRequest" SG_ 2479157249 HU_DisplayDay 0;
BA_ "NetworkRequestHoldingTime" SG_ 2479157249 HU_DisplayDay 200;
BA_ "Version" SG_ 2479157249 HU_DisplayDay "21.07.07";
BA_ "GenSigSendType" SG_ 2479157249 HU_AM_PM_INFO 4;
BA_ "GenSigStartValue" SG_ 2479157249 HU_AM_PM_INFO 3;
BA_ "UserSigValidity" SG_ 2479157249 HU_AM_PM_INFO 0;
BA_REL_ "GenSigTimeoutTime" BU_SG_REL_ ATS SG_ 2479157249 HU_AM_PM_INFO 5000;
BA_ "NetworkRequest" SG_ 2479157249 HU_AM_PM_INFO 0;
BA_ "Version" SG_ 2479157249 HU_AM_PM_INFO "18.09.02";
BA_ "GenSigSendType" SG_ 2479157249 HU_ZeroDetection 4;
BA_ "UserSigValidity" SG_ 2479157249 HU_ZeroDetection 1;
BA_REL_ "GenSigTimeoutTime" BU_SG_REL_ ATS SG_ 2479157249 HU_ZeroDetection 5000;
BA_ "Version" SG_ 2479157249 HU_ZeroDetection "18.06.03";
BA_ "GenSigSendType" SG_ 2479157249 HU_TimeFormat 4;
BA_ "GenSigStartValue" SG_ 2479157249 HU_TimeFormat 3;
BA_ "UserSigValidity" SG_ 2479157249 HU_TimeFormat 0;
BA_REL_ "GenSigTimeoutTime" BU_SG_REL_ ATS SG_ 2479157249 HU_TimeFormat 5000;
BA_ "NetworkRequest" SG_ 2479157249 HU_TimeFormat 0;
BA_ "Version" SG_ 2479157249 HU_TimeFormat "18.09.02";
BA_ "GenSigSendType" SG_ 2479157249 HU_ComRefresh 4;
BA_ "GenSigStartValue" SG_ 2479157249 HU_ComRefresh 3;
BA_ "UserSigValidity" SG_ 2479157249 HU_ComRefresh 0;
BA_REL_ "GenSigTimeoutTime" BU_SG_REL_ ATS SG_ 2479157249 HU_ComRefresh 5000;
BA_ "NetworkRequest" SG_ 2479157249 HU_ComRefresh 0;
BA_ "Version" SG_ 2479157249 HU_ComRefresh "18.09.02";
BA_ "GenSigSendType" SG_ 2479157249 HU_ClockInfo 4;
BA_ "GenSigStartValue" SG_ 2479157249 HU_ClockInfo 3;
BA_ "UserSigValidity" SG_ 2479157249 HU_ClockInfo 0;
BA_REL_ "GenSigTimeoutTime" BU_SG_REL_ ATS SG_ 2479157249 HU_ClockInfo 5000;
BA_ "NetworkRequest" SG_ 2479157249 HU_ClockInfo 0;
BA_ "Version" SG_ 2479157249 HU_ClockInfo "18.09.02";
BA_ "GenSigSendType" SG_ 2479157249 HU_DisplayHour 4;
BA_ "GenSigStartValue" SG_ 2479157249 HU_DisplayHour 255;
BA_ "UserSigValidity" SG_ 2479157249 HU_DisplayHour 0;
BA_REL_ "GenSigTimeoutTime" BU_SG_REL_ ATS SG_ 2479157249 HU_DisplayHour 5000;
BA_ "NetworkRequest" SG_ 2479157249 HU_DisplayHour 0;
BA_ "NetworkRequestHoldingTime" SG_ 2479157249 HU_DisplayHour 200;
BA_ "Version" SG_ 2479157249 HU_DisplayHour "21.07.07";
BA_ "GenMsgCycleTime" BO_ 2458168321 0;
BA_ "VFrameFormat" BO_ 2458168321 1;
BA_ "GenSigSendType" SG_ 2458168321 C_HCIMSWeightNValueSet 4;
BA_ "UserSigValidity" SG_ 2458168321 C_HCIMSWeightNValueSet 3;
BA_REL_ "GenSigTimeoutTime" BU_SG_REL_ PSM SG_ 2458168321 C_HCIMSWeightNValueSet 0;
BA_ "Version" SG_ 2458168321 C_HCIMSWeightNValueSet "18.09.04";
BA_ "GenSigSendType" SG_ 2458168321 C_HCIMSSitHeightNValueSet 4;
BA_ "UserSigValidity" SG_ 2458168321 C_HCIMSSitHeightNValueSet 3;
BA_REL_ "GenSigTimeoutTime" BU_SG_REL_ PSM SG_ 2458168321 C_HCIMSSitHeightNValueSet 0;
BA_ "Version" SG_ 2458168321 C_HCIMSSitHeightNValueSet "18.09.04";
BA_ "GenSigSendType" SG_ 2458168321 CF_AVN_RRSeatAUTOHEATNValueSet 4;
BA_ "UserSigValidity" SG_ 2458168321 CF_AVN_RRSeatAUTOHEATNValueSet 3;
BA_ "Version" SG_ 2458168321 CF_AVN_RRSeatAUTOHEATNValueSet "18.09.04";
BA_ "GenSigSendType" SG_ 2458168321 CF_AVN_RLSeatAUTOHEATNValueSet 4;
BA_ "UserSigValidity" SG_ 2458168321 CF_AVN_RLSeatAUTOHEATNValueSet 3;
BA_ "Version" SG_ 2458168321 CF_AVN_RLSeatAUTOHEATNValueSet "18.09.04";
BA_ "GenSigSendType" SG_ 2458168321 CF_AVN_AstAUTOHEATNValueSet 4;
BA_ "UserSigValidity" SG_ 2458168321 CF_AVN_AstAUTOHEATNValueSet 3;
BA_ "Version" SG_ 2458168321 CF_AVN_AstAUTOHEATNValueSet "18.09.04";
BA_ "GenSigSendType" SG_ 2458168321 CF_Avn_DrvAUTOHEATNValueSet 4;
BA_ "UserSigValidity" SG_ 2458168321 CF_Avn_DrvAUTOHEATNValueSet 3;
BA_ "Version" SG_ 2458168321 CF_Avn_DrvAUTOHEATNValueSet "18.09.04";
BA_ "GenSigSendType" SG_ 2458168321 CF_AVN_BodySpprtSet 4;
BA_ "GenSigStartValue" SG_ 2458168321 CF_AVN_BodySpprtSet 3;
BA_ "UserSigValidity" SG_ 2458168321 CF_AVN_BodySpprtSet 3;
BA_REL_ "GenSigTimeoutTime" BU_SG_REL_ DPSS SG_ 2458168321 CF_AVN_BodySpprtSet 0;
BA_REL_ "GenSigTimeoutTime" BU_SG_REL_ DSAU SG_ 2458168321 CF_AVN_BodySpprtSet 0;
BA_ "Version" SG_ 2458168321 CF_AVN_BodySpprtSet "18.11.01";
BA_ "GenSigSendType" SG_ 2458168321 CF_AVN_EASMAUTOHEATNValueSet 4;
BA_ "UserSigValidity" SG_ 2458168321 CF_AVN_EASMAUTOHEATNValueSet 3;
BA_ "Version" SG_ 2458168321 CF_AVN_EASMAUTOHEATNValueSet "18.09.04";
BA_ "GenSigSendType" SG_ 2458168321 CF_AVN_EDSMAUTOHEATNValueSet 4;
BA_ "UserSigValidity" SG_ 2458168321 CF_AVN_EDSMAUTOHEATNValueSet 3;
BA_ "Version" SG_ 2458168321 CF_AVN_EDSMAUTOHEATNValueSet "18.09.04";
BA_ "GenSigSendType" SG_ 2458168321 CF_AVN_AntiDRWSYSet 4;
BA_ "GenSigStartValue" SG_ 2458168321 CF_AVN_AntiDRWSYSet 3;
BA_ "UserSigValidity" SG_ 2458168321 CF_AVN_AntiDRWSYSet 3;
BA_ "Version" SG_ 2458168321 CF_AVN_AntiDRWSYSet "18.11.01";
BA_ "GenSigSendType" SG_ 2458168321 CF_AVN_AirSptTimeNValueSet 4;
BA_ "GenSigStartValue" SG_ 2458168321 CF_AVN_AirSptTimeNValueSet 7;
BA_ "UserSigValidity" SG_ 2458168321 CF_AVN_AirSptTimeNValueSet 3;
BA_ "Version" SG_ 2458168321 CF_AVN_AirSptTimeNValueSet "18.09.04";
BA_ "GenSigSendType" SG_ 2458168321 CF_AVN_AirSptStrNValue 4;
BA_ "GenSigStartValue" SG_ 2458168321 CF_AVN_AirSptStrNValue 3;
BA_ "UserSigValidity" SG_ 2458168321 CF_AVN_AirSptStrNValue 3;
BA_ "Version" SG_ 2458168321 CF_AVN_AirSptStrNValue "18.09.04";
BA_ "GenSigSendType" SG_ 2458168321 CF_AVN_SeatDrvModNValueSet 4;
BA_ "GenSigStartValue" SG_ 2458168321 CF_AVN_SeatDrvModNValueSet 3;
BA_ "UserSigValidity" SG_ 2458168321 CF_AVN_SeatDrvModNValueSet 3;
BA_REL_ "GenSigTimeoutTime" BU_SG_REL_ DPSS SG_ 2458168321 CF_AVN_SeatDrvModNValueSet 0;
BA_REL_ "GenSigTimeoutTime" BU_SG_REL_ DSAU SG_ 2458168321 CF_AVN_SeatDrvModNValueSet 0;
BA_ "Version" SG_ 2458168321 CF_AVN_SeatDrvModNValueSet "18.09.04";
BA_ "GenSigSendType" SG_ 2458168321 C_HCIMSHeightNvalueSet 4;
BA_ "UserSigValidity" SG_ 2458168321 C_HCIMSHeightNvalueSet 3;
BA_REL_ "GenSigTimeoutTime" BU_SG_REL_ PSM SG_ 2458168321 C_HCIMSHeightNvalueSet 0;
BA_ "Version" SG_ 2458168321 C_HCIMSHeightNvalueSet "18.09.04";
BA_ "Description" SG_ 2458168321 C_SLB_SmartCtrl_NValue "USM Reqest for Smart Posture Care 2.0 On/Off";
BA_ "GenSigSendType" SG_ 2458168321 C_SLB_SmartCtrl_NValue 4;
BA_ "UserSigValidity" SG_ 2458168321 C_SLB_SmartCtrl_NValue 3;
BA_ "Version" SG_ 2458168321 C_SLB_SmartCtrl_NValue "19.04.01";
BA_ "GenSigSendType" SG_ 2458168321 CF_AVN_AntiDRWSYIntvlSet 4;
BA_ "GenSigStartValue" SG_ 2458168321 CF_AVN_AntiDRWSYIntvlSet 7;
BA_ "UserSigValidity" SG_ 2458168321 CF_AVN_AntiDRWSYIntvlSet 3;
BA_ "Version" SG_ 2458168321 CF_AVN_AntiDRWSYIntvlSet "18.11.01";
BA_ "GenSigSendType" SG_ 2458168321 CF_AVN_CushSoftNValueSet 4;
BA_ "GenSigStartValue" SG_ 2458168321 CF_AVN_CushSoftNValueSet 7;
BA_ "UserSigValidity" SG_ 2458168321 CF_AVN_CushSoftNValueSet 3;
BA_ "Version" SG_ 2458168321 CF_AVN_CushSoftNValueSet "18.10.05";
BA_ "Description" SG_ 2458168321 C_SmrtSldngDrNValueSet "USM request for Smart Sliding Door";
BA_ "GenSigSendType" SG_ 2458168321 C_SmrtSldngDrNValueSet 4;
BA_ "UserSigValidity" SG_ 2458168321 C_SmrtSldngDrNValueSet 3;
BA_ "Version" SG_ 2458168321 C_SmrtSldngDrNValueSet "19.01.10";
BA_ "Description" SG_ 2458168321 CF_AVN_TurboPressureUnit "USM Request for Turbo Boost Pressure Unit";
BA_ "GenSigSendType" SG_ 2458168321 CF_AVN_TurboPressureUnit 4;
BA_ "UserSigValidity" SG_ 2458168321 CF_AVN_TurboPressureUnit 3;
BA_ "Version" SG_ 2458168321 CF_AVN_TurboPressureUnit "19.06.02";
BA_ "Description" SG_ 2458168321 CF_AVN_CluTorqueUnit "USM Request for Torque Unit Setting";
BA_ "GenSigSendType" SG_ 2458168321 CF_AVN_CluTorqueUnit 4;
BA_ "UserSigValidity" SG_ 2458168321 CF_AVN_CluTorqueUnit 3;
BA_ "Version" SG_ 2458168321 CF_AVN_CluTorqueUnit "19.06.02";
BA_ "Description" SG_ 2458168321 AVN_Usm_CluThemeAutoSet "USM response for Cluster theme auto setting";
BA_ "GenSigSendType" SG_ 2458168321 AVN_Usm_CluThemeAutoSet 4;
BA_ "UserSigValidity" SG_ 2458168321 AVN_Usm_CluThemeAutoSet 3;
BA_ "Version" SG_ 2458168321 AVN_Usm_CluThemeAutoSet "19.06.00";
BA_ "Description" SG_ 2458168321 AVN_Usm_CluThemeSta "USM Request for Cluster theme setting";
BA_ "GenSigSendType" SG_ 2458168321 AVN_Usm_CluThemeSta 4;
BA_ "UserSigValidity" SG_ 2458168321 AVN_Usm_CluThemeSta 3;
BA_ "Version" SG_ 2458168321 AVN_Usm_CluThemeSta "19.06.00";
BA_ "Description" SG_ 2458168321 AVN_Usm_CluFuelEconomySet "USM request for Fuel economy auto reset";
BA_ "GenSigSendType" SG_ 2458168321 AVN_Usm_CluFuelEconomySet 4;
BA_ "UserSigValidity" SG_ 2458168321 AVN_Usm_CluFuelEconomySet 3;
BA_ "Version" SG_ 2458168321 AVN_Usm_CluFuelEconomySet "19.06.00";
BA_ "GenSigSendType" SG_ 2458168321 CF_AVN_HCIMSButtonCommand 4;
BA_ "UserSigValidity" SG_ 2458168321 CF_AVN_HCIMSButtonCommand 3;
BA_REL_ "GenSigTimeoutTime" BU_SG_REL_ PSM SG_ 2458168321 CF_AVN_HCIMSButtonCommand 0;
BA_ "Version" SG_ 2458168321 CF_AVN_HCIMSButtonCommand "18.09.04";
BA_ "GenMsgCycleTime" BO_ 1251 0;
BA_ "Description" SG_ 1251 IAU_Crc13Val "The data area for CRC calculation is based on the data length (DLC) of the message DB.

The CRC shall be calculated over the entire data block (excluding the CRC bytes) including the user data, alive counter and Data ID 

 

- CRC Polynomial (0x1D) , Initial Value : 0x00, XOR value : 0xFF, Data ID Mode : Both, Data ID : Message ID + 0xF800 

- The initial value is for CRC calculation and the message should be sent with the calculated result value. 

The mathematical expression to 8 bit CRC polynomial is given here. G(x) = x8 + x4 + x3 + x2 + 1";
BA_ "GenSigSendType" SG_ 1251 IAU_Crc13Val 4;
BA_ "GenSigStartValue" SG_ 1251 IAU_Crc13Val 255;
BA_ "UserSigValidity" SG_ 1251 IAU_Crc13Val 0;
BA_ "Version" SG_ 1251 IAU_Crc13Val "20.01.03";
BA_ "Description" SG_ 1251 IAU_EsyAcsProfileID "This signal indicate the current detected profile ID by NFC.

(The drv seat move to the easy access position of the detected profile ID when receive the signal)";
BA_ "GenSigSendType" SG_ 1251 IAU_EsyAcsProfileID 4;
BA_ "UserSigValidity" SG_ 1251 IAU_EsyAcsProfileID 0;
BA_REL_ "GenSigTimeoutTime" BU_SG_REL_ PSM SG_ 1251 IAU_EsyAcsProfileID 0;
BA_ "NetworkRequest" SG_ 1251 IAU_EsyAcsProfileID 0;
BA_ "NetworkRequestHoldingTime" SG_ 1251 IAU_EsyAcsProfileID 5;
BA_ "Version" SG_ 1251 IAU_EsyAcsProfileID "18.08.12";
BA_ "Description" SG_ 1251 IAU_SmrtPhnID "SmartPhone ID with BLE Connection";
BA_ "GenSigSendType" SG_ 1251 IAU_SmrtPhnID 4;
BA_ "UserSigValidity" SG_ 1251 IAU_SmrtPhnID 0;
BA_ "NetworkRequest" SG_ 1251 IAU_SmrtPhnID 0;
BA_ "NetworkRequestHoldingTime" SG_ 1251 IAU_SmrtPhnID 5;
BA_ "Version" SG_ 1251 IAU_SmrtPhnID "20.04.06";
BA_ "Description" SG_ 1251 IAU_SmrtPhnCmd "SmartPhone RKE Command Indi";
BA_ "GenSigSendType" SG_ 1251 IAU_SmrtPhnCmd 4;
BA_ "UserSigValidity" SG_ 1251 IAU_SmrtPhnCmd 0;
BA_ "NetworkRequest" SG_ 1251 IAU_SmrtPhnCmd 0;
BA_ "NetworkRequestHoldingTime" SG_ 1251 IAU_SmrtPhnCmd 5;
BA_ "Version" SG_ 1251 IAU_SmrtPhnCmd "19.08.08";
BA_ "Description" SG_ 1251 IAU_Fob_UWBRdy "Feedback of Fob_UWBRngAreaCmd, Fob_UWBRngID";
BA_ "GenSigSendType" SG_ 1251 IAU_Fob_UWBRdy 4;
BA_ "UserSigValidity" SG_ 1251 IAU_Fob_UWBRdy 0;
BA_ "NetworkRequest" SG_ 1251 IAU_Fob_UWBRdy 0;
BA_ "NetworkRequestHoldingTime" SG_ 1251 IAU_Fob_UWBRdy 5000;
BA_ "Version" SG_ 1251 IAU_Fob_UWBRdy "21.03.01";
BA_ "Description" SG_ 1251 IAUwFPM_ISK_LearningReq "This signal is to request ISK learning to FPM";
BA_ "GenSigSendType" SG_ 1251 IAUwFPM_ISK_LearningReq 4;
BA_ "UserSigValidity" SG_ 1251 IAUwFPM_ISK_LearningReq 0;
BA_REL_ "GenSigTimeoutTime" BU_SG_REL_ FPM SG_ 1251 IAUwFPM_ISK_LearningReq 0;
BA_ "NetworkRequest" SG_ 1251 IAUwFPM_ISK_LearningReq 0;
BA_ "NetworkRequestHoldingTime" SG_ 1251 IAUwFPM_ISK_LearningReq 5;
BA_ "Version" SG_ 1251 IAUwFPM_ISK_LearningReq "20.05.02";
BA_ "Description" SG_ 1251 IAU2FPM_ISKLearnFdbck "This signal is learning feedback";
BA_ "GenSigSendType" SG_ 1251 IAU2FPM_ISKLearnFdbck 4;
BA_ "UserSigValidity" SG_ 1251 IAU2FPM_ISKLearnFdbck 0;
BA_REL_ "GenSigTimeoutTime" BU_SG_REL_ FPM SG_ 1251 IAU2FPM_ISKLearnFdbck 0;
BA_ "NetworkRequest" SG_ 1251 IAU2FPM_ISKLearnFdbck 0;
BA_ "NetworkRequestHoldingTime" SG_ 1251 IAU2FPM_ISKLearnFdbck 5;
BA_ "Version" SG_ 1251 IAU2FPM_ISKLearnFdbck "20.04.05";
BA_ "GenMsgCycleTime" BO_ 1153 0;
BA_ "Description" SG_ 1153 IAU2FPM_EncryptedData2 "This signal is for a send enrypted result of IAU.";
BA_ "GenSigSendType" SG_ 1153 IAU2FPM_EncryptedData2 4;
BA_ "UserSigValidity" SG_ 1153 IAU2FPM_EncryptedData2 0;
BA_REL_ "GenSigTimeoutTime" BU_SG_REL_ FPM SG_ 1153 IAU2FPM_EncryptedData2 0;
BA_ "NetworkRequest" SG_ 1153 IAU2FPM_EncryptedData2 0;
BA_ "NetworkRequestHoldingTime" SG_ 1153 IAU2FPM_EncryptedData2 5000;
BA_ "Version" SG_ 1153 IAU2FPM_EncryptedData2 "20.03.07";
BA_ "GenMsgCycleTime" BO_ 1156 0;
BA_ "GenSigSendType" SG_ 1156 IAU2FPM_RndNum 4;
BA_ "UserSigValidity" SG_ 1156 IAU2FPM_RndNum 0;
BA_REL_ "GenSigTimeoutTime" BU_SG_REL_ FPM SG_ 1156 IAU2FPM_RndNum 0;
BA_ "NetworkRequest" SG_ 1156 IAU2FPM_RndNum 0;
BA_ "NetworkRequestHoldingTime" SG_ 1156 IAU2FPM_RndNum 5000;
BA_ "Version" SG_ 1156 IAU2FPM_RndNum "20.05.02";
BA_ "GenMsgSendType" BO_ 1167 0;
BA_ "GenMsgCycleTime" BO_ 1167 1000;
BA_ "Description" SG_ 1167 ICU_Crc11Val "The data area for CRC calculation is based on the data length (DLC) of the message DB.

The CRC shall be calculated over the entire data block (excluding the CRC bytes) including the user data, alive counter and Data ID 

 

- CRC Polynomial (0x1D) , Initial Value : 0x00, XOR value : 0xFF, Data ID Mode : Both, Data ID : Message ID + 0xF800 

- The initial value is for CRC calculation and the message should be sent with the calculated result value. 

The mathematical expression to 8 bit CRC polynomial is given here. G(x) = x8 + x4 + x3 + x2 + 1";
BA_ "GenSigSendType" SG_ 1167 ICU_Crc11Val 4;
BA_ "GenSigStartValue" SG_ 1167 ICU_Crc11Val 255;
BA_ "UserSigValidity" SG_ 1167 ICU_Crc11Val 0;
BA_REL_ "GenSigTimeoutTime" BU_SG_REL_ vHS_M SG_ 1167 ICU_Crc11Val 5000;
BA_ "Version" SG_ 1167 ICU_Crc11Val "18.11.08";
BA_ "Description" SG_ 1167 Bat_dischrg "Battery discharge notification flag";
BA_ "GenSigSendType" SG_ 1167 Bat_dischrg 4;
BA_ "UserSigValidity" SG_ 1167 Bat_dischrg 3;
BA_ "Version" SG_ 1167 Bat_dischrg "18.03.05";
BA_ "Description" SG_ 1167 ICU_AlvCnt11Val "For the first transmission request for a data element the counter shall be initialized with 0 and shall be incremented by 1

for every subsequent send request. When the counter reaches the maximum value(0xE), then it shall restart with 0 for the next send request";
BA_ "GenSigSendType" SG_ 1167 ICU_AlvCnt11Val 4;
BA_ "UserSigValidity" SG_ 1167 ICU_AlvCnt11Val 0;
BA_ "Version" SG_ 1167 ICU_AlvCnt11Val "18.11.08";
BA_ "Description" SG_ 1167 Batt_SoCWarningValue "This signal is Battery SOC from battery sensor.";
BA_ "GenSigSendType" SG_ 1167 Batt_SoCWarningValue 4;
BA_ "GenSigStartValue" SG_ 1167 Batt_SoCWarningValue 255;
BA_ "UserSigValidity" SG_ 1167 Batt_SoCWarningValue 0;
BA_ "Version" SG_ 1167 Batt_SoCWarningValue "17.12.00";
BA_ "Description" SG_ 1167 C_StrgWhlHeatingOpt "Steering wheel heating option signal";
BA_ "GenSigSendType" SG_ 1167 C_StrgWhlHeatingOpt 4;
BA_ "UserSigValidity" SG_ 1167 C_StrgWhlHeatingOpt 3;
BA_ "Version" SG_ 1167 C_StrgWhlHeatingOpt "18.12.02";
BA_ "Description" SG_ 1167 C_StrgWhlHeatingSWInf "Steering wheel heating Step information signal";
BA_ "GenSigSendType" SG_ 1167 C_StrgWhlHeatingSWInf 4;
BA_ "UserSigValidity" SG_ 1167 C_StrgWhlHeatingSWInf 3;
BA_ "Version" SG_ 1167 C_StrgWhlHeatingSWInf "19.11.11";
BA_ "Description" SG_ 1167 ICU_BattAutoCutPreWrng "This is a warning signal before blocking the dark current of the ICU by the battery SOC.";
BA_ "GenSigSendType" SG_ 1167 ICU_BattAutoCutPreWrng 4;
BA_ "GenSigStartValue" SG_ 1167 ICU_BattAutoCutPreWrng 3;
BA_ "UserSigValidity" SG_ 1167 ICU_BattAutoCutPreWrng 0;
BA_ "Version" SG_ 1167 ICU_BattAutoCutPreWrng "20.04.06";
BA_ "Description" SG_ 1167 IGN_AutoOff_WarnSta "This signal is for battery discharge warning (engine not running && IGN/ACC on)

To prevent battery discharge, ICU requests the head unit to display warning and requests IBU to turn IGN/ACC off.";
BA_ "GenSigSendType" SG_ 1167 IGN_AutoOff_WarnSta 4;
BA_ "UserSigValidity" SG_ 1167 IGN_AutoOff_WarnSta 3;
BA_ "Version" SG_ 1167 IGN_AutoOff_WarnSta "20.03.03";
BA_ "GenMsgSendType" BO_ 1171 0;
BA_ "Description" SG_ 1171 RLPSM_SWVerMajor1 "Indicate the SCM software version as follows:

- The software version is displayed in three digits.

- The Major and Minor digits are separated by '.'

- Signal values are transmitted to ASCII codes.



※ Example

RLPSM_SWVerMajor1 : 0x41 (HEX) -> ASCII CODE : 'A' 

RLPSM_SWVerMinor1 : 0x30 (HEX) -> ASCII CODE : '0'

RLPSM_SWVerMinor2 : 0x33 (HEX) -> ASCII CODE : '3'

=> RLPSM S/W Ver is displayed 'A.03'";
BA_ "GenSigSendType" SG_ 1171 RLPSM_SWVerMajor1 4;
BA_ "UserSigValidity" SG_ 1171 RLPSM_SWVerMajor1 0;
BA_REL_ "GenSigTimeoutTime" BU_SG_REL_ CGW_CCU SG_ 1171 RLPSM_SWVerMajor1 1500;
BA_ "RoutingFactor" SG_ 1171 RLPSM_SWVerMajor1 0;
BA_ "Version" SG_ 1171 RLPSM_SWVerMajor1 "21.07.00";
BA_ "Description" SG_ 1171 RLPSM_SWVerMinor2 "Indicate the APSM software version as follows:

- The software version is displayed in three digits.

- The Major and Minor digits are separated by '.'

- Signal values are transmitted to ASCII codes.



※ Example

RLPSM_SWVerMajor1 : 0x41 (HEX) -> ASCII CODE : 'A' 

RLPSM_SWVerMinor1 : 0x30 (HEX) -> ASCII CODE : '0'

RLPSM_SWVerMinor2 : 0x33 (HEX) -> ASCII CODE : '3'

=> RLPSM S/W Ver is displayed 'A.03'";
BA_ "GenSigSendType" SG_ 1171 RLPSM_SWVerMinor2 4;
BA_ "UserSigValidity" SG_ 1171 RLPSM_SWVerMinor2 0;
BA_REL_ "GenSigTimeoutTime" BU_SG_REL_ CGW_CCU SG_ 1171 RLPSM_SWVerMinor2 1500;
BA_ "RoutingFactor" SG_ 1171 RLPSM_SWVerMinor2 0;
BA_ "Version" SG_ 1171 RLPSM_SWVerMinor2 "20.04.06";
BA_ "Description" SG_ 1171 RLPSM_RLTiltPosition "REAR LEFT SEAT TILT POSITION (UNIT: mm)";
BA_ "GenSigSendType" SG_ 1171 RLPSM_RLTiltPosition 4;
BA_ "UserSigValidity" SG_ 1171 RLPSM_RLTiltPosition 0;
BA_REL_ "GenSigTimeoutTime" BU_SG_REL_ PSM SG_ 1171 RLPSM_RLTiltPosition 1500;
BA_ "NetworkRequest" SG_ 1171 RLPSM_RLTiltPosition 0;
BA_ "NetworkRequestHoldingTime" SG_ 1171 RLPSM_RLTiltPosition 5000;
BA_ "RoutingFactor" SG_ 1171 RLPSM_RLTiltPosition 0;
BA_ "Version" SG_ 1171 RLPSM_RLTiltPosition "21.01.03";
BA_ "Description" SG_ 1171 RLPSM_RLLegRestPosition "Rear SEAT Leg Rest UP/DOWN POSITION (UNIT: º)";
BA_ "GenSigSendType" SG_ 1171 RLPSM_RLLegRestPosition 4;
BA_ "UserSigValidity" SG_ 1171 RLPSM_RLLegRestPosition 0;
BA_REL_ "GenSigTimeoutTime" BU_SG_REL_ PSM SG_ 1171 RLPSM_RLLegRestPosition 1500;
BA_ "NetworkRequest" SG_ 1171 RLPSM_RLLegRestPosition 0;
BA_ "NetworkRequestHoldingTime" SG_ 1171 RLPSM_RLLegRestPosition 5000;
BA_ "RoutingFactor" SG_ 1171 RLPSM_RLLegRestPosition 0;
BA_ "Version" SG_ 1171 RLPSM_RLLegRestPosition "21.01.03";
BA_ "Description" SG_ 1171 RLPSM_RLLegRestSlidePosition "REAR LEFT SEAT LEG REST SLIDE POSITION (UNIT: mm)";
BA_ "GenSigSendType" SG_ 1171 RLPSM_RLLegRestSlidePosition 4;
BA_ "UserSigValidity" SG_ 1171 RLPSM_RLLegRestSlidePosition 0;
BA_REL_ "GenSigTimeoutTime" BU_SG_REL_ PSM SG_ 1171 RLPSM_RLLegRestSlidePosition 1500;
BA_ "NetworkRequest" SG_ 1171 RLPSM_RLLegRestSlidePosition 0;
BA_ "NetworkRequestHoldingTime" SG_ 1171 RLPSM_RLLegRestSlidePosition 5000;
BA_ "RoutingFactor" SG_ 1171 RLPSM_RLLegRestSlidePosition 0;
BA_ "Version" SG_ 1171 RLPSM_RLLegRestSlidePosition "21.01.03";
BA_ "Description" SG_ 1171 RLPSM_SWVerMinor1 "Indicate the APSM software version as follows:

- The software version is displayed in three digits.

- The Major and Minor digits are separated by '.'

- Signal values are transmitted to ASCII codes.



※ Example

RLPSM_SWVerMajor1 : 0x41 (HEX) -> ASCII CODE : 'A' 

RLPSM_SWVerMinor1 : 0x30 (HEX) -> ASCII CODE : '0'

RLPSM_SWVerMinor2 : 0x33 (HEX) -> ASCII CODE : '3'

=> RLPSM S/W Ver is displayed 'A.03'";
BA_ "GenSigSendType" SG_ 1171 RLPSM_SWVerMinor1 4;
BA_ "UserSigValidity" SG_ 1171 RLPSM_SWVerMinor1 0;
BA_REL_ "GenSigTimeoutTime" BU_SG_REL_ CGW_CCU SG_ 1171 RLPSM_SWVerMinor1 1500;
BA_ "RoutingFactor" SG_ 1171 RLPSM_SWVerMinor1 0;
BA_ "Version" SG_ 1171 RLPSM_SWVerMinor1 "20.04.06";
BA_ "GenMsgSendType" BO_ 191 0;
BA_ "Description" SG_ 191 RL_SHVU_DTCdisplay "0x00: DTC is not exist(Fail is not exist)/0x01:IGN2 Fuse Open Detection/0x02:Switch Input Detection at Same Time/0x03:NTC/Heating wire Open Detection/0x04:NTC+/NTC- Terminal Short Detection/0x05:NTC+/Heater+ Terminal Short Detection/0x06:NTC+/Heater-, Heater+/Heater-, Heater+/NTC- Terminal Short Detection/0x07:NTC+/Heater- Wiring Short Detection/0x08:NTC+/Heater-, Heater+/Heater-, Heater+/NTC- Wiring Short Detection/0x09:Target Temperature Dissatisfied/0x0A:Blower+/Blower- Short, Blower+/Blower Speed, Blower-/Blower Speed Wiring Short Detection/0x0B:Blower+/Blower RPM, Blower-/Blower RPM, Blower Speed/Blower RPM Short Detection/0x0C:Blower+, Blower-, Blower Speed Signal open Detection/0x0D:Blower RPM signal Open Detection/0x0E~0xFD:Unused/0xFE:No Display/0xFF:Invalid";
BA_ "GenSigSendType" SG_ 191 RL_SHVU_DTCdisplay 4;
BA_ "UserSigValidity" SG_ 191 RL_SHVU_DTCdisplay 3;
BA_REL_ "GenSigTimeoutTime" BU_SG_REL_ ATS SG_ 191 RL_SHVU_DTCdisplay 1500;
BA_ "NetworkRequest" SG_ 191 RL_SHVU_DTCdisplay 0;
BA_ "NetworkRequestHoldingTime" SG_ 191 RL_SHVU_DTCdisplay 5000;
BA_ "Version" SG_ 191 RL_SHVU_DTCdisplay "19.12.08";
BA_ "Description" SG_ 191 RL_SHVU_DiagMode "0x0:Default/0x1:DTC Mode/0x2:Normal Mode/0x3:Invalid";
BA_ "GenSigSendType" SG_ 191 RL_SHVU_DiagMode 4;
BA_ "UserSigValidity" SG_ 191 RL_SHVU_DiagMode 3;
BA_REL_ "GenSigTimeoutTime" BU_SG_REL_ ATS SG_ 191 RL_SHVU_DiagMode 1500;
BA_ "NetworkRequest" SG_ 191 RL_SHVU_DiagMode 0;
BA_ "NetworkRequestHoldingTime" SG_ 191 RL_SHVU_DiagMode 5000;
BA_ "Version" SG_ 191 RL_SHVU_DiagMode "19.12.08";
BA_ "GenMsgSendType" BO_ 1172 0;
BA_ "Description" SG_ 1172 RRPSM_SWVerMajor1 "Indicate the SCM software version as follows:

- The software version is displayed in three digits.

- The Major and Minor digits are separated by '.'

- Signal values are transmitted to ASCII codes.



※ Example

RRPSM_SWVerMajor1 : 0x41 (HEX) -> ASCII CODE : 'A' 

RRPSM_SWVerMinor1 : 0x30 (HEX) -> ASCII CODE : '0'

RRPSM_SWVerMinor2 : 0x33 (HEX) -> ASCII CODE : '3'

=> RRPSM S/W Ver is displayed 'A.03'";
BA_ "GenSigSendType" SG_ 1172 RRPSM_SWVerMajor1 4;
BA_ "UserSigValidity" SG_ 1172 RRPSM_SWVerMajor1 0;
BA_REL_ "GenSigTimeoutTime" BU_SG_REL_ CGW_CCU SG_ 1172 RRPSM_SWVerMajor1 1500;
BA_ "RoutingFactor" SG_ 1172 RRPSM_SWVerMajor1 0;
BA_ "Version" SG_ 1172 RRPSM_SWVerMajor1 "21.07.00";
BA_ "Description" SG_ 1172 RRPSM_SWVerMinor2 "Indicate the APSM software version as follows:

- The software version is displayed in three digits.

- The Major and Minor digits are separated by '.'

- Signal values are transmitted to ASCII codes.



※ Example

RRPSM_SWVerMajor1 : 0x41 (HEX) -> ASCII CODE : 'A' 

RRPSM_SWVerMinor1 : 0x30 (HEX) -> ASCII CODE : '0'

RRPSM_SWVerMinor2 : 0x33 (HEX) -> ASCII CODE : '3'

=> RRPSM S/W Ver is displayed 'A.03'";
BA_ "GenSigSendType" SG_ 1172 RRPSM_SWVerMinor2 4;
BA_ "UserSigValidity" SG_ 1172 RRPSM_SWVerMinor2 0;
BA_REL_ "GenSigTimeoutTime" BU_SG_REL_ CGW_CCU SG_ 1172 RRPSM_SWVerMinor2 1500;
BA_ "RoutingFactor" SG_ 1172 RRPSM_SWVerMinor2 0;
BA_ "Version" SG_ 1172 RRPSM_SWVerMinor2 "20.04.06";
BA_ "Description" SG_ 1172 RRPSM_SWVerMinor1 "Indicate the APSM software version as follows:

- The software version is displayed in three digits.

- The Major and Minor digits are separated by '.'

- Signal values are transmitted to ASCII codes.



※ Example

RRPSM_SWVerMajor1 : 0x41 (HEX) -> ASCII CODE : 'A' 

RRPSM_SWVerMinor1 : 0x30 (HEX) -> ASCII CODE : '0'

RRPSM_SWVerMinor2 : 0x33 (HEX) -> ASCII CODE : '3'

=> RRPSM S/W Ver is displayed 'A.03'";
BA_ "GenSigSendType" SG_ 1172 RRPSM_SWVerMinor1 4;
BA_ "UserSigValidity" SG_ 1172 RRPSM_SWVerMinor1 0;
BA_REL_ "GenSigTimeoutTime" BU_SG_REL_ CGW_CCU SG_ 1172 RRPSM_SWVerMinor1 1500;
BA_ "RoutingFactor" SG_ 1172 RRPSM_SWVerMinor1 0;
BA_ "Version" SG_ 1172 RRPSM_SWVerMinor1 "20.04.06";
BA_ "GenMsgSendType" BO_ 208 0;
BA_ "Description" SG_ 208 RR_SHVU_DTCdisplay "0x00: DTC is not exist(Fail is not exist)/0x01:IGN2 Fuse Open Detection/0x02:Switch Input Detection at Same Time/0x03:NTC/Heating wire Open Detection/0x04:NTC+/NTC- Terminal Short Detection/0x05:NTC+/Heater+ Terminal Short Detection/0x06:NTC+/Heater-, Heater+/Heater-, Heater+/NTC- Terminal Short Detection/0x07:NTC+/Heater- Wiring Short Detection/0x08:NTC+/Heater-, Heater+/Heater-, Heater+/NTC- Wiring Short Detection/0x09:Target Temperature Dissatisfied/0x0A:Blower+/Blower- Short, Blower+/Blower Speed, Blower-/Blower Speed Wiring Short Detection/0x0B:Blower+/Blower RPM, Blower-/Blower RPM, Blower Speed/Blower RPM Short Detection/0x0C:Blower+, Blower-, Blower Speed Signal open Detection/0x0D:Blower RPM signal Open Detection/0x0E~0xFD:Unused/0xFE:No Display/0xFF:Invalid";
BA_ "GenSigSendType" SG_ 208 RR_SHVU_DTCdisplay 4;
BA_ "UserSigValidity" SG_ 208 RR_SHVU_DTCdisplay 3;
BA_REL_ "GenSigTimeoutTime" BU_SG_REL_ ATS SG_ 208 RR_SHVU_DTCdisplay 1500;
BA_ "NetworkRequest" SG_ 208 RR_SHVU_DTCdisplay 0;
BA_ "NetworkRequestHoldingTime" SG_ 208 RR_SHVU_DTCdisplay 5000;
BA_ "Version" SG_ 208 RR_SHVU_DTCdisplay "19.11.06";
BA_ "Description" SG_ 208 RR_SHVU_DiagMode "0x0:Default/0x1:DTC Mode/0x2:Normal Mode/0x3:Invalid";
BA_ "GenSigSendType" SG_ 208 RR_SHVU_DiagMode 4;
BA_ "UserSigValidity" SG_ 208 RR_SHVU_DiagMode 3;
BA_REL_ "GenSigTimeoutTime" BU_SG_REL_ ATS SG_ 208 RR_SHVU_DiagMode 1500;
BA_ "NetworkRequest" SG_ 208 RR_SHVU_DiagMode 0;
BA_ "NetworkRequestHoldingTime" SG_ 208 RR_SHVU_DiagMode 5000;
BA_ "Version" SG_ 208 RR_SHVU_DiagMode "19.11.06";
BA_ "GenMsgSendType" BO_ 761 0;
BA_ "Description" SG_ 761 SBCM_AST_Crc3Val "The data area for CRC calculation is based on the data length (DLC) of the message DB.

The CRC shall be calculated over the entire data block (excluding the CRC bytes) including the user data, alive counter and Data ID 

 

- CRC Polynomial (0x1D) , Initial Value : 0x00, XOR value : 0xFF, Data ID Mode : Both, Data ID : Message ID + 0xF800 

- The initial value is for CRC calculation and the message should be sent with the calculated result value. 

The mathematical expression to 8 bit CRC polynomial is given here. G(x) = x8 + x4 + x3 + x2 + 1";
BA_ "GenSigSendType" SG_ 761 SBCM_AST_Crc3Val 4;
BA_ "GenSigStartValue" SG_ 761 SBCM_AST_Crc3Val 255;
BA_ "UserSigValidity" SG_ 761 SBCM_AST_Crc3Val 3;
BA_ "RoutingFactor" SG_ 761 SBCM_AST_Crc3Val 0;
BA_ "Version" SG_ 761 SBCM_AST_Crc3Val "20.12.04";
BA_ "Description" SG_ 761 SBCM_AST_AlvCnt3Val "For the first transmission request for a data element the counter shall be initialized with 0 and shall be incremented by 1

for every subsequent send request. When the counter reaches the maximum value(0xE), then it shall restart with 0 for the next send request";
BA_ "GenSigSendType" SG_ 761 SBCM_AST_AlvCnt3Val 4;
BA_ "UserSigValidity" SG_ 761 SBCM_AST_AlvCnt3Val 3;
BA_ "RoutingFactor" SG_ 761 SBCM_AST_AlvCnt3Val 0;
BA_ "Version" SG_ 761 SBCM_AST_AlvCnt3Val "20.12.04";
BA_ "GenSigSendType" SG_ 761 AST_CrashMRActAlarm 4;
BA_ "UserSigValidity" SG_ 761 AST_CrashMRActAlarm 0;
BA_ "NetworkRequest" SG_ 761 AST_CrashMRActAlarm 0;
BA_ "NetworkRequestHoldingTime" SG_ 761 AST_CrashMRActAlarm 5000;
BA_ "RoutingFactor" SG_ 761 AST_CrashMRActAlarm 0;
BA_ "Version" SG_ 761 AST_CrashMRActAlarm "20.12.05";
BA_ "GenSigSendType" SG_ 761 PwrDRBuzzerOut_AST 4;
BA_ "UserSigValidity" SG_ 761 PwrDRBuzzerOut_AST 0;
BA_REL_ "GenSigTimeoutTime" BU_SG_REL_ AMP SG_ 761 PwrDRBuzzerOut_AST 1500;
BA_ "NetworkRequest" SG_ 761 PwrDRBuzzerOut_AST 0;
BA_ "NetworkRequestHoldingTime" SG_ 761 PwrDRBuzzerOut_AST 5000;
BA_ "RoutingFactor" SG_ 761 PwrDRBuzzerOut_AST 0;
BA_ "Version" SG_ 761 PwrDRBuzzerOut_AST "21.03.03";
BA_ "GenSigSendType" SG_ 761 IMS_OSMirPlayBackSta_RH 4;
BA_ "UserSigValidity" SG_ 761 IMS_OSMirPlayBackSta_RH 0;
BA_REL_ "GenSigTimeoutTime" BU_SG_REL_ PSM SG_ 761 IMS_OSMirPlayBackSta_RH 1500;
BA_ "NetworkRequest" SG_ 761 IMS_OSMirPlayBackSta_RH 0;
BA_ "NetworkRequestHoldingTime" SG_ 761 IMS_OSMirPlayBackSta_RH 5;
BA_ "RoutingFactor" SG_ 761 IMS_OSMirPlayBackSta_RH 0;
BA_ "Version" SG_ 761 IMS_OSMirPlayBackSta_RH "21.07.07";
BA_ "Description" SG_ 761 Mirror_RHVerPosVal "This signal indicates RH Outside Mirror Vertical Position Sensor Voltage";
BA_ "GenSigSendType" SG_ 761 Mirror_RHVerPosVal 4;
BA_ "UserSigValidity" SG_ 761 Mirror_RHVerPosVal 0;
BA_ "NetworkRequest" SG_ 761 Mirror_RHVerPosVal 0;
BA_ "NetworkRequestHoldingTime" SG_ 761 Mirror_RHVerPosVal 5000;
BA_ "RoutingFactor" SG_ 761 Mirror_RHVerPosVal 0;
BA_ "Version" SG_ 761 Mirror_RHVerPosVal "20.08.07";
BA_ "Description" SG_ 761 Mirror_RHHorPosVal "This signal indicates RH Outside Mirror Horizontal Position Sensor Voltage";
BA_ "GenSigSendType" SG_ 761 Mirror_RHHorPosVal 4;
BA_ "UserSigValidity" SG_ 761 Mirror_RHHorPosVal 0;
BA_ "NetworkRequest" SG_ 761 Mirror_RHHorPosVal 0;
BA_ "NetworkRequestHoldingTime" SG_ 761 Mirror_RHHorPosVal 5000;
BA_ "RoutingFactor" SG_ 761 Mirror_RHHorPosVal 0;
BA_ "Version" SG_ 761 Mirror_RHHorPosVal "20.08.07";
BA_ "GenSigSendType" SG_ 761 SBCM_AST_DiagSta 4;
BA_ "UserSigValidity" SG_ 761 SBCM_AST_DiagSta 0;
BA_ "NetworkRequest" SG_ 761 SBCM_AST_DiagSta 0;
BA_ "NetworkRequestHoldingTime" SG_ 761 SBCM_AST_DiagSta 5000;
BA_ "RoutingFactor" SG_ 761 SBCM_AST_DiagSta 0;
BA_ "Version" SG_ 761 SBCM_AST_DiagSta "20.09.00";
BA_ "GenMsgSendType" BO_ 758 0;
BA_ "Description" SG_ 758 SBCM_DRV_Crc2Val "The data area for CRC calculation is based on the data length (DLC) of the message DB.

The CRC shall be calculated over the entire data block (excluding the CRC bytes) including the user data, alive counter and Data ID 

 

- CRC Polynomial (0x1D) , Initial Value : 0x00, XOR value : 0xFF, Data ID Mode : Both, Data ID : Message ID + 0xF800 

- The initial value is for CRC calculation and the message should be sent with the calculated result value. 

The mathematical expression to 8 bit CRC polynomial is given here. G(x) = x8 + x4 + x3 + x2 + 1";
BA_ "GenSigSendType" SG_ 758 SBCM_DRV_Crc2Val 4;
BA_ "GenSigStartValue" SG_ 758 SBCM_DRV_Crc2Val 255;
BA_ "UserSigValidity" SG_ 758 SBCM_DRV_Crc2Val 3;
BA_ "RoutingFactor" SG_ 758 SBCM_DRV_Crc2Val 0;
BA_ "Version" SG_ 758 SBCM_DRV_Crc2Val "20.12.04";
BA_ "Description" SG_ 758 SBCM_DRV_AlvCnt2Val "For the first transmission request for a data element the counter shall be initialized with 0 and shall be incremented by 1

for every subsequent send request. When the counter reaches the maximum value(0xE), then it shall restart with 0 for the next send request";
BA_ "GenSigSendType" SG_ 758 SBCM_DRV_AlvCnt2Val 4;
BA_ "UserSigValidity" SG_ 758 SBCM_DRV_AlvCnt2Val 3;
BA_ "RoutingFactor" SG_ 758 SBCM_DRV_AlvCnt2Val 0;
BA_ "Version" SG_ 758 SBCM_DRV_AlvCnt2Val "20.12.04";
BA_ "GenSigSendType" SG_ 758 SBCM_PsvDrLkReq 4;
BA_ "UserSigValidity" SG_ 758 SBCM_PsvDrLkReq 0;
BA_ "NetworkRequest" SG_ 758 SBCM_PsvDrLkReq 0;
BA_ "RoutingFactor" SG_ 758 SBCM_PsvDrLkReq 0;
BA_ "Version" SG_ 758 SBCM_PsvDrLkReq "21.01.03";
BA_ "GenSigSendType" SG_ 758 USM_DrvGhostDoorSta 4;
BA_ "UserSigValidity" SG_ 758 USM_DrvGhostDoorSta 0;
BA_ "NetworkRequest" SG_ 758 USM_DrvGhostDoorSta 0;
BA_ "NetworkRequestHoldingTime" SG_ 758 USM_DrvGhostDoorSta 5000;
BA_ "RoutingFactor" SG_ 758 USM_DrvGhostDoorSta 0;
BA_ "Version" SG_ 758 USM_DrvGhostDoorSta "21.03.11";
BA_ "GenSigSendType" SG_ 758 DRV_CrashMRActAlarm 4;
BA_ "UserSigValidity" SG_ 758 DRV_CrashMRActAlarm 0;
BA_ "NetworkRequest" SG_ 758 DRV_CrashMRActAlarm 0;
BA_ "NetworkRequestHoldingTime" SG_ 758 DRV_CrashMRActAlarm 5000;
BA_ "RoutingFactor" SG_ 758 DRV_CrashMRActAlarm 0;
BA_ "Version" SG_ 758 DRV_CrashMRActAlarm "20.12.04";
BA_ "GenSigSendType" SG_ 758 IMS_OSMirPlayBackSta_LH 4;
BA_ "UserSigValidity" SG_ 758 IMS_OSMirPlayBackSta_LH 0;
BA_REL_ "GenSigTimeoutTime" BU_SG_REL_ PSM SG_ 758 IMS_OSMirPlayBackSta_LH 1500;
BA_ "NetworkRequest" SG_ 758 IMS_OSMirPlayBackSta_LH 0;
BA_ "NetworkRequestHoldingTime" SG_ 758 IMS_OSMirPlayBackSta_LH 5;
BA_ "RoutingFactor" SG_ 758 IMS_OSMirPlayBackSta_LH 0;
BA_ "Version" SG_ 758 IMS_OSMirPlayBackSta_LH "21.07.07";
BA_ "Description" SG_ 758 ECMMRR_PLUS "This signal for passenger outside mirror OEC function(or ECM)

SBCM_DRV receive the ECM voltage value via H/wiring and then send this signal to SBCM_AST";
BA_ "GenSigSendType" SG_ 758 ECMMRR_PLUS 4;
BA_ "UserSigValidity" SG_ 758 ECMMRR_PLUS 0;
BA_ "NetworkRequest" SG_ 758 ECMMRR_PLUS 0;
BA_ "NetworkRequestHoldingTime" SG_ 758 ECMMRR_PLUS 5000;
BA_ "RoutingFactor" SG_ 758 ECMMRR_PLUS 0;
BA_ "Version" SG_ 758 ECMMRR_PLUS "20.09.00";
BA_ "Description" SG_ 758 Mirror_LHVerPosVal "This signal indicates LH Outside Mirror Vertical Position Sensor Voltage";
BA_ "GenSigSendType" SG_ 758 Mirror_LHVerPosVal 4;
BA_ "UserSigValidity" SG_ 758 Mirror_LHVerPosVal 0;
BA_ "NetworkRequest" SG_ 758 Mirror_LHVerPosVal 0;
BA_ "NetworkRequestHoldingTime" SG_ 758 Mirror_LHVerPosVal 5000;
BA_ "RoutingFactor" SG_ 758 Mirror_LHVerPosVal 0;
BA_ "Version" SG_ 758 Mirror_LHVerPosVal "20.08.07";
BA_ "Description" SG_ 758 Mirror_LHHorPosVal "This signal indicates LH Outside Mirror Horizontal Position Sensor Voltage";
BA_ "GenSigSendType" SG_ 758 Mirror_LHHorPosVal 4;
BA_ "UserSigValidity" SG_ 758 Mirror_LHHorPosVal 0;
BA_ "NetworkRequest" SG_ 758 Mirror_LHHorPosVal 0;
BA_ "NetworkRequestHoldingTime" SG_ 758 Mirror_LHHorPosVal 5000;
BA_ "RoutingFactor" SG_ 758 Mirror_LHHorPosVal 0;
BA_ "Version" SG_ 758 Mirror_LHHorPosVal "20.08.07";
BA_ "GenSigSendType" SG_ 758 SBCM_DRV_DiagSta 4;
BA_ "UserSigValidity" SG_ 758 SBCM_DRV_DiagSta 0;
BA_ "NetworkRequest" SG_ 758 SBCM_DRV_DiagSta 0;
BA_ "NetworkRequestHoldingTime" SG_ 758 SBCM_DRV_DiagSta 5000;
BA_ "RoutingFactor" SG_ 758 SBCM_DRV_DiagSta 0;
BA_ "Version" SG_ 758 SBCM_DRV_DiagSta "20.09.00";
BA_ "GenMsgSendType" BO_ 763 0;
BA_ "Description" SG_ 763 SBCM_DRV_Crc3Val "The data area for CRC calculation is based on the data length (DLC) of the message DB.

The CRC shall be calculated over the entire data block (excluding the CRC bytes) including the user data, alive counter and Data ID 

 

- CRC Polynomial (0x1D) , Initial Value : 0x00, XOR value : 0xFF, Data ID Mode : Both, Data ID : Message ID + 0xF800 

- The initial value is for CRC calculation and the message should be sent with the calculated result value. 

The mathematical expression to 8 bit CRC polynomial is given here. G(x) = x8 + x4 + x3 + x2 + 1";
BA_ "GenSigSendType" SG_ 763 SBCM_DRV_Crc3Val 4;
BA_ "GenSigStartValue" SG_ 763 SBCM_DRV_Crc3Val 255;
BA_ "UserSigValidity" SG_ 763 SBCM_DRV_Crc3Val 3;
BA_ "Version" SG_ 763 SBCM_DRV_Crc3Val "20.12.04";
BA_ "Description" SG_ 763 SBCM_DRV_AlvCnt3Val "For the first transmission request for a data element the counter shall be initialized with 0 and shall be incremented by 1

for every subsequent send request. When the counter reaches the maximum value(0xE), then it shall restart with 0 for the next send request";
BA_ "GenSigSendType" SG_ 763 SBCM_DRV_AlvCnt3Val 4;
BA_ "UserSigValidity" SG_ 763 SBCM_DRV_AlvCnt3Val 3;
BA_ "Version" SG_ 763 SBCM_DRV_AlvCnt3Val "20.12.04";
BA_ "GenSigSendType" SG_ 763 PwrDRBuzzerOut_DRV 4;
BA_ "UserSigValidity" SG_ 763 PwrDRBuzzerOut_DRV 0;
BA_REL_ "GenSigTimeoutTime" BU_SG_REL_ AMP SG_ 763 PwrDRBuzzerOut_DRV 1500;
BA_ "NetworkRequest" SG_ 763 PwrDRBuzzerOut_DRV 0;
BA_ "NetworkRequestHoldingTime" SG_ 763 PwrDRBuzzerOut_DRV 5000;
BA_ "Version" SG_ 763 PwrDRBuzzerOut_DRV "21.03.03";
BA_ "GenMsgSendType" BO_ 759 0;
BA_ "GenSigSendType" SG_ 759 RL_CrashMRActAlarm 4;
BA_ "UserSigValidity" SG_ 759 RL_CrashMRActAlarm 0;
BA_ "NetworkRequest" SG_ 759 RL_CrashMRActAlarm 0;
BA_ "NetworkRequestHoldingTime" SG_ 759 RL_CrashMRActAlarm 5000;
BA_ "RoutingFactor" SG_ 759 RL_CrashMRActAlarm 0;
BA_ "Version" SG_ 759 RL_CrashMRActAlarm "20.12.05";
BA_ "GenSigSendType" SG_ 759 PwrDRBuzzerOut_RL 4;
BA_ "UserSigValidity" SG_ 759 PwrDRBuzzerOut_RL 0;
BA_REL_ "GenSigTimeoutTime" BU_SG_REL_ AMP SG_ 759 PwrDRBuzzerOut_RL 1500;
BA_ "NetworkRequest" SG_ 759 PwrDRBuzzerOut_RL 0;
BA_ "NetworkRequestHoldingTime" SG_ 759 PwrDRBuzzerOut_RL 5000;
BA_ "RoutingFactor" SG_ 759 PwrDRBuzzerOut_RL 0;
BA_ "Version" SG_ 759 PwrDRBuzzerOut_RL "21.03.03";
BA_ "GenMsgSendType" BO_ 760 0;
BA_ "GenSigSendType" SG_ 760 RR_CrashMRActAlarm 4;
BA_ "UserSigValidity" SG_ 760 RR_CrashMRActAlarm 0;
BA_ "NetworkRequest" SG_ 760 RR_CrashMRActAlarm 0;
BA_ "NetworkRequestHoldingTime" SG_ 760 RR_CrashMRActAlarm 5000;
BA_ "RoutingFactor" SG_ 760 RR_CrashMRActAlarm 0;
BA_ "Version" SG_ 760 RR_CrashMRActAlarm "20.12.05";
BA_ "GenSigSendType" SG_ 760 PwrDRBuzzerOut_RR 4;
BA_ "UserSigValidity" SG_ 760 PwrDRBuzzerOut_RR 0;
BA_REL_ "GenSigTimeoutTime" BU_SG_REL_ AMP SG_ 760 PwrDRBuzzerOut_RR 1500;
BA_ "NetworkRequest" SG_ 760 PwrDRBuzzerOut_RR 0;
BA_ "NetworkRequestHoldingTime" SG_ 760 PwrDRBuzzerOut_RR 5000;
BA_ "RoutingFactor" SG_ 760 PwrDRBuzzerOut_RR 0;
BA_ "Version" SG_ 760 PwrDRBuzzerOut_RR "21.03.03";
BA_ "GenMsgCycleTime" BO_ 1712 0;
BA_ "GenMsgCycleTimeFast" BO_ 1712 0;
BA_ "GenMsgNrOfRepetition" BO_ 1712 0;
BA_ "DiagResponse" BO_ 1712 1;
BA_ "GenMsgILSupport" BO_ 1712 0;
BA_ "TpMessage" BO_ 1712 1;
BA_ "TpTxIndex" BO_ 1712 21;
BA_ "Description" SG_ 1712 Byte0_TCP_796 "TP Index : 21";
BA_ "UsrSigPurpose" SG_ 1712 Byte0_TCP_796 4;
BA_ "UserSigValidity" SG_ 1712 Byte0_TCP_796 0;
BA_REL_ "GenSigTimeoutTime" BU_SG_REL_ CGW_CCU SG_ 1712 Byte0_TCP_796 0;
BA_ "NetworkRequestHoldingTime" SG_ 1712 Byte0_TCP_796 5000;
BA_ "Version" SG_ 1712 Byte0_TCP_796 "21.03.01";
BA_ "Description" SG_ 1712 Byte2_Data_796 "TP Index : 21";
BA_ "UsrSigPurpose" SG_ 1712 Byte2_Data_796 4;
BA_ "UserSigValidity" SG_ 1712 Byte2_Data_796 0;
BA_REL_ "GenSigTimeoutTime" BU_SG_REL_ CGW_CCU SG_ 1712 Byte2_Data_796 0;
BA_ "NetworkRequestHoldingTime" SG_ 1712 Byte2_Data_796 5000;
BA_ "Version" SG_ 1712 Byte2_Data_796 "21.03.01";
BA_ "Description" SG_ 1712 Byte3_Data_796 "TP Index : 21";
BA_ "UsrSigPurpose" SG_ 1712 Byte3_Data_796 4;
BA_ "UserSigValidity" SG_ 1712 Byte3_Data_796 0;
BA_REL_ "GenSigTimeoutTime" BU_SG_REL_ CGW_CCU SG_ 1712 Byte3_Data_796 0;
BA_ "NetworkRequestHoldingTime" SG_ 1712 Byte3_Data_796 5000;
BA_ "Version" SG_ 1712 Byte3_Data_796 "21.03.01";
BA_ "Description" SG_ 1712 Byte4_Data_796 "TP Index : 21";
BA_ "UsrSigPurpose" SG_ 1712 Byte4_Data_796 4;
BA_ "UserSigValidity" SG_ 1712 Byte4_Data_796 0;
BA_REL_ "GenSigTimeoutTime" BU_SG_REL_ CGW_CCU SG_ 1712 Byte4_Data_796 0;
BA_ "NetworkRequestHoldingTime" SG_ 1712 Byte4_Data_796 5000;
BA_ "Version" SG_ 1712 Byte4_Data_796 "21.03.01";
BA_ "Description" SG_ 1712 Byte5_Data_796 "TP Index : 21";
BA_ "UsrSigPurpose" SG_ 1712 Byte5_Data_796 4;
BA_ "UserSigValidity" SG_ 1712 Byte5_Data_796 0;
BA_REL_ "GenSigTimeoutTime" BU_SG_REL_ CGW_CCU SG_ 1712 Byte5_Data_796 0;
BA_ "NetworkRequestHoldingTime" SG_ 1712 Byte5_Data_796 5000;
BA_ "Version" SG_ 1712 Byte5_Data_796 "21.03.01";
BA_ "Description" SG_ 1712 Byte6_Data_796 "TP Index : 21";
BA_ "UsrSigPurpose" SG_ 1712 Byte6_Data_796 4;
BA_ "UserSigValidity" SG_ 1712 Byte6_Data_796 0;
BA_REL_ "GenSigTimeoutTime" BU_SG_REL_ CGW_CCU SG_ 1712 Byte6_Data_796 0;
BA_ "NetworkRequestHoldingTime" SG_ 1712 Byte6_Data_796 5000;
BA_ "Version" SG_ 1712 Byte6_Data_796 "21.03.01";
BA_ "Description" SG_ 1712 Byte7_Data_796 "TP Index : 21";
BA_ "UsrSigPurpose" SG_ 1712 Byte7_Data_796 4;
BA_ "UserSigValidity" SG_ 1712 Byte7_Data_796 0;
BA_REL_ "GenSigTimeoutTime" BU_SG_REL_ CGW_CCU SG_ 1712 Byte7_Data_796 0;
BA_ "NetworkRequestHoldingTime" SG_ 1712 Byte7_Data_796 5000;
BA_ "Version" SG_ 1712 Byte7_Data_796 "21.03.01";
BA_ "Description" SG_ 1712 Byte1_Data_796 "TP Index : 21";
BA_ "UsrSigPurpose" SG_ 1712 Byte1_Data_796 4;
BA_ "UserSigValidity" SG_ 1712 Byte1_Data_796 0;
BA_REL_ "GenSigTimeoutTime" BU_SG_REL_ CGW_CCU SG_ 1712 Byte1_Data_796 0;
BA_ "NetworkRequestHoldingTime" SG_ 1712 Byte1_Data_796 5000;
BA_ "Version" SG_ 1712 Byte1_Data_796 "21.03.01";
BA_ "GenMsgCycleTime" BO_ 1745 0;
BA_ "GenMsgCycleTimeFast" BO_ 1745 0;
BA_ "GenMsgNrOfRepetition" BO_ 1745 0;
BA_ "DiagRequest" BO_ 1745 1;
BA_ "GenMsgILSupport" BO_ 1745 0;
BA_ "TpMessage" BO_ 1745 1;
BA_ "TpTxIndex" BO_ 1745 21;
BA_ "Description" SG_ 1745 Byte0_TCP_795 "TP Index : 21";
BA_ "UsrSigPurpose" SG_ 1745 Byte0_TCP_795 3;
BA_ "UserSigValidity" SG_ 1745 Byte0_TCP_795 0;
BA_REL_ "GenSigTimeoutTime" BU_SG_REL_ AMP SG_ 1745 Byte0_TCP_795 0;
BA_ "NetworkRequest" SG_ 1745 Byte0_TCP_795 0;
BA_ "NetworkRequestHoldingTime" SG_ 1745 Byte0_TCP_795 5000;
BA_ "Version" SG_ 1745 Byte0_TCP_795 "21.03.01";
BA_ "Description" SG_ 1745 Byte2_Data_795 "TP Index : 21";
BA_ "UsrSigPurpose" SG_ 1745 Byte2_Data_795 3;
BA_ "UserSigValidity" SG_ 1745 Byte2_Data_795 0;
BA_REL_ "GenSigTimeoutTime" BU_SG_REL_ AMP SG_ 1745 Byte2_Data_795 0;
BA_ "NetworkRequest" SG_ 1745 Byte2_Data_795 0;
BA_ "NetworkRequestHoldingTime" SG_ 1745 Byte2_Data_795 5000;
BA_ "Version" SG_ 1745 Byte2_Data_795 "21.03.01";
BA_ "Description" SG_ 1745 Byte3_Data_795 "TP Index : 21";
BA_ "UsrSigPurpose" SG_ 1745 Byte3_Data_795 3;
BA_ "UserSigValidity" SG_ 1745 Byte3_Data_795 0;
BA_REL_ "GenSigTimeoutTime" BU_SG_REL_ AMP SG_ 1745 Byte3_Data_795 0;
BA_ "NetworkRequest" SG_ 1745 Byte3_Data_795 0;
BA_ "NetworkRequestHoldingTime" SG_ 1745 Byte3_Data_795 5000;
BA_ "Version" SG_ 1745 Byte3_Data_795 "21.03.01";
BA_ "Description" SG_ 1745 Byte4_Data_795 "TP Index : 21";
BA_ "UsrSigPurpose" SG_ 1745 Byte4_Data_795 3;
BA_ "UserSigValidity" SG_ 1745 Byte4_Data_795 0;
BA_REL_ "GenSigTimeoutTime" BU_SG_REL_ AMP SG_ 1745 Byte4_Data_795 0;
BA_ "NetworkRequest" SG_ 1745 Byte4_Data_795 0;
BA_ "NetworkRequestHoldingTime" SG_ 1745 Byte4_Data_795 5000;
BA_ "Version" SG_ 1745 Byte4_Data_795 "21.03.01";
BA_ "Description" SG_ 1745 Byte5_Data_795 "TP Index : 21";
BA_ "UsrSigPurpose" SG_ 1745 Byte5_Data_795 3;
BA_ "UserSigValidity" SG_ 1745 Byte5_Data_795 0;
BA_REL_ "GenSigTimeoutTime" BU_SG_REL_ AMP SG_ 1745 Byte5_Data_795 0;
BA_ "NetworkRequest" SG_ 1745 Byte5_Data_795 0;
BA_ "NetworkRequestHoldingTime" SG_ 1745 Byte5_Data_795 5000;
BA_ "Version" SG_ 1745 Byte5_Data_795 "21.03.01";
BA_ "Description" SG_ 1745 Byte6_Data_795 "TP Index : 21";
BA_ "UsrSigPurpose" SG_ 1745 Byte6_Data_795 3;
BA_ "UserSigValidity" SG_ 1745 Byte6_Data_795 0;
BA_REL_ "GenSigTimeoutTime" BU_SG_REL_ AMP SG_ 1745 Byte6_Data_795 0;
BA_ "NetworkRequest" SG_ 1745 Byte6_Data_795 0;
BA_ "NetworkRequestHoldingTime" SG_ 1745 Byte6_Data_795 5000;
BA_ "Version" SG_ 1745 Byte6_Data_795 "21.03.01";
BA_ "Description" SG_ 1745 Byte7_Data_795 "TP Index : 21";
BA_ "UsrSigPurpose" SG_ 1745 Byte7_Data_795 3;
BA_ "UserSigValidity" SG_ 1745 Byte7_Data_795 0;
BA_REL_ "GenSigTimeoutTime" BU_SG_REL_ AMP SG_ 1745 Byte7_Data_795 0;
BA_ "NetworkRequest" SG_ 1745 Byte7_Data_795 0;
BA_ "NetworkRequestHoldingTime" SG_ 1745 Byte7_Data_795 5000;
BA_ "Version" SG_ 1745 Byte7_Data_795 "21.03.01";
BA_ "Description" SG_ 1745 Byte1_Data_795 "TP Index : 21";
BA_ "UsrSigPurpose" SG_ 1745 Byte1_Data_795 3;
BA_ "UserSigValidity" SG_ 1745 Byte1_Data_795 0;
BA_REL_ "GenSigTimeoutTime" BU_SG_REL_ AMP SG_ 1745 Byte1_Data_795 0;
BA_ "NetworkRequest" SG_ 1745 Byte1_Data_795 0;
BA_ "NetworkRequestHoldingTime" SG_ 1745 Byte1_Data_795 5000;
BA_ "Version" SG_ 1745 Byte1_Data_795 "21.03.01";
VAL_ 2256643329 AWD_Typ 0 "Electronic 4WD (FF)" 1 "Electronic 4WD (FR)" 2 "Electric shift 4WD (FR)" 3 "Error indicator" ;
VAL_ 2256643329 AWD_IcscErrSta 0 "ICSC signal is valid" 1 "ICSC signal is not valid" 2 "Not used" 3 "Error Indicator" ;
VAL_ 2256643329 AWD_CltchDtVal 255 "Error indicator" ;
VAL_ 2256643330 AWD_OpMod2HSta 0 "2H mode is inactive" 1 "2H mode is activated" 2 "Not used" 3 "Error indicator" ;
VAL_ 2256643330 AWD_TireSizeWrng 0 "No Failure" 1 "1 level difference detected" 2 "2 level difference detected" 3 "3 level difference detected" 4 "Reserved" 5 "Reserved" 6 "Reserved" 7 "Reserved" ;
VAL_ 2256643330 AWD_ShaftTqVal 65535 "Error indicator" ;
VAL_ 2256643330 AWD_OpMod4HSta 0 "4H mode is inactive" 1 "4H mode is activated" 2 "Not used" 3 "Error indicator" ;
VAL_ 2256643330 AWD_StrWhlPosVal 65535 "Error indicator" ;
VAL_ 2256643330 AWD_OpModLowSta 0 "LOW mode is inactive" 1 "LOW mode is activated" 2 "Not used" 3 "Error indicator" ;
VAL_ 2256643330 AWD_FRWhlSpdSnsrVal 255 "Error indicator" ;
VAL_ 2256643330 AWD_FLWhlSpdSnsrVal 255 "Error indicator" ;
VAL_ 2256643330 AWD_OpModAutoSta 0 "AUTO mode is inactive" 1 "AUTO mode is activated" 2 "Not used" 3 "Error indicator" ;
VAL_ 2256643330 AWD_OpModLkSta 0 "LOCK mode is inactive" 1 "LOCK mode is activated" 2 "Not used" 3 "Error indicator" ;
VAL_ 2256643331 AWD_RRWhlSpdSnsrVal 255 "Error indicator" ;
VAL_ 2256643331 AWD_CltchPrsrVal 65535 "Error indicator" ;
VAL_ 2256643331 AWD_RLWhlSpdSnsrVal 255 "Error indicator" ;
VAL_ 2256643332 AWD_ShaftTqVal_Calc 65535 "Error indicator" ;
VAL_ 2256643332 AWD_SysOpSta 0 "deactivated" 1 "initialization" 2 "calibration" 3 "normal operation (torque setting)" 4 "temporary failed (return to normal operation in same running cycle)" 5 "permanant failed with clutch limited operation" 6 "permanant failed, clutch fully open" 7 "permanant failed, position unknown" 11 "ESC(ESP) reactivated requested" 15 "Signal not available(Error indicator)" ;
VAL_ 2290230529 CLU_OutTempCSta 0 "0x0x0~0x64:-40~60℃" 100 "0x0x0~0x64:-40~60℃" 101 "0x65~0xFE:Reserved" 254 "0x65~0xFE:Reserved" 255 "Invalid" ;
VAL_ 2290230529 CLU_DTEVal 0 "Valid DTE 0 (Display '---')" 1 "0x1~0xFFE:Valid DTE (1 ~ 4094 km)" 4094 "0x1~0xFFE:Valid DTE (1 ~ 4094 km)" 4095 "Invalid(Display '---' Blink)" ;
VAL_ 2290230529 CLU_TripUnitSta 0 "Not Used" 1 "km" 2 "mile" 3 "Invailid" ;
VAL_ 2290230529 CLU_LoFuelWrngSta 0 "Low fuel Warning is off" 1 "Low fuel Warning is on" 2 "Not used" 3 "Invalid" ;
VAL_ 2290230530 CLU_DawLastBrkTimeVal 0 "Value x 30min (0~6.5hr)" 1 "Value x 30min (0~6.5hr)" 2 "Value x 30min (0~6.5hr)" 3 "Value x 30min (0~6.5hr)" 4 "Value x 30min (0~6.5hr)" 5 "Value x 30min (0~6.5hr)" 6 "Value x 30min (0~6.5hr)" 7 "Value x 30min (0~6.5hr)" 8 "Value x 30min (0~6.5hr)" 9 "Value x 30min (0~6.5hr)" 10 "Value x 30min (0~6.5hr)" 11 "Value x 30min (0~6.5hr)" 12 "Value x 30min (0~6.5hr)" 13 "Value x 30min (0~6.5hr)" 14 "7hr or more" 15 "Invalid" ;
VAL_ 2290230530 CLU_IceWrnIndSta 0 "Off" 1 "On" 2 "Not used" 3 "Error Indicator" ;
VAL_ 2290230530 CLU_DrvngModSwSta 0 "Off" 1 "Normal" 2 "Eco" 3 "Sport" 4 "Sport+" 5 "Smart" 6 "Custom" 7 "N-mode" 8 "Reserved" 9 "Reserved" 10 "Reserved" 11 "Reserved" 12 "Reserved" 13 "Reserved" 14 "Reserved" 15 "Reserved" ;
VAL_ 2290230530 CLU_FuelLvlSta 0 "0x0x0~0x64:0%~100%" 100 "0x0x0~0x64:0%~100%" 101 "Reserved" 102 "Reserved" 103 "Reserved" 104 "Reserved" 105 "Reserved" 106 "Reserved" 107 "Reserved" 108 "Reserved" 109 "Reserved" 110 "Reserved" 111 "Reserved" 112 "Reserved" 113 "Reserved" 114 "Reserved" 115 "Reserved" 116 "Reserved" 117 "Reserved" 118 "Reserved" 119 "Reserved" 120 "Reserved" 121 "Reserved" 122 "Reserved" 123 "Reserved" 124 "Reserved" 125 "Reserved" 126 "Reserved" 127 "Invalid(Error)" ;
VAL_ 2290230530 CLU_SRSWrngLmpSta 0 "Lamp OFF" 1 "Lamp On" 2 "Lamp Flashing" 3 "ACU message error" 7 "Lamp Circuit Failure" ;
VAL_ 2290230530 CLU_OutTempFSta 0 "0x0x0~0xB4:-40~140℉" 180 "0x0x0~0xB4:-40~140℉" 181 "Reserved" 182 "Reserved" 183 "Reserved" 184 "Reserved" 185 "Reserved" 186 "Reserved" 187 "Reserved" 188 "Reserved" 189 "Reserved" 190 "Reserved" 191 "Reserved" 192 "Reserved" 193 "Reserved" 194 "Reserved" 195 "Reserved" 196 "Reserved" 197 "Reserved" 198 "Reserved" 199 "Reserved" 200 "Reserved" 201 "Reserved" 202 "Reserved" 203 "Reserved" 204 "Reserved" 205 "Reserved" 206 "Reserved" 207 "Reserved" 208 "Reserved" 209 "Reserved" 210 "Reserved" 211 "Reserved" 212 "Reserved" 213 "Reserved" 214 "Reserved" 215 "Reserved" 216 "Reserved" 217 "Reserved" 218 "Reserved" 219 "Reserved" 220 "Reserved" 221 "Reserved" 222 "Reserved" 223 "Reserved" 224 "Reserved" 225 "Reserved" 226 "Reserved" 227 "Reserved" 228 "Reserved" 229 "Reserved" 230 "Reserved" 231 "Reserved" 232 "Reserved" 233 "Reserved" 234 "Reserved" 235 "Reserved" 236 "Reserved" 237 "Reserved" 238 "Reserved" 239 "Reserved" 240 "Reserved" 241 "Reserved" 242 "Reserved" 243 "Reserved" 244 "Reserved" 245 "Reserved" 246 "Reserved" 247 "Reserved" 248 "Reserved" 249 "Reserved" 250 "Reserved" 251 "Reserved" 252 "Reserved" 253 "Reserved" 254 "Reserved" 255 "Invalid" ;
VAL_ 2290230530 CLU_OdoVal 16777215 "Error" ;
VAL_ 2558926849 Warn_Sound_Off 0 "Off" 1 "Reserved" 2 "Reserved" 3 "Reserved" 4 "Reserved" 5 "Reserved" 6 "Reserved" 7 "Invalid" ;
VAL_ 2558926849 Warn_Sound_PAS 0 "Off" 1 "PAS Sensor Fail" 2 "PAS R Position" 3 "Reserved" 4 "Reserved" 5 "Reserved" 6 "Reserved" 7 "Invalid" ;
VAL_ 2558926849 Warn_Sound_SPAS 0 "Off" 1 "SPAS Parking Complet" 2 "SPAS Scan Complete" 3 "SPAS System Abort" 4 "SPAS Gear Shift" 5 "Reserved" 6 "Reserved" 7 "Invalid" ;
VAL_ 2558926849 Warn_Sound_EPB 0 "Off" 1 "Parking Brake Warning" 2 "EPB Uncomfort Alarm" 3 "Key Operated Warning" 4 "Vehicle Not P Warning" 5 "ESCL Not Lock Warning" 6 "Sunroof Open Warning" 7 "Hood Open Warning" 7 "Reserved" 8 "Reserved" 9 "Reserved" 10 "Reserved" 11 "Reserved" 12 "Reserved" 13 "Reserved" 14 "Reserved" 15 "Reserved" 16 "Reserved" 17 "Reserved" 18 "Reserved" 19 "Reserved" 20 "Reserved" 21 "Reserved" 22 "Reserved" 23 "Reserved" 24 "Reserved" 25 "Reserved" 26 "Reserved" 27 "Reserved" 28 "Reserved" 29 "Reserved" 30 "Reserved" 31 "Invalid" ;
VAL_ 2558926849 Warn_Sound_Welcome 0 "Off" 1 "Welcom" 2 "Goodbye" 3 "HEV_EV_Ready" 4 "Reserved" 5 "Reserved" 6 "Reserved" 7 "Invalid" ;
VAL_ 2558926849 Warn_Sound_IMS 0 "Off" 1 "ID Out" 2 "Deactivation ID Warning" 3 "IMS Buzzer" 4 "Reserved" 5 "Reserved" 6 "Reserved" 7 "Invalid" ;
VAL_ 2558926849 Warn_Sound_FCW 0 "Off" 1 "TakeOverReq" 2 "OverSpeedWarning" 3 "Reserved" 4 "Reserved" 5 "Reserved" 6 "Reserved" 7 "Invalid" ;
VAL_ 2558926849 Warn_Sound_Ice 0 "Off" 1 "Ice Warning" 2 "Reserved" 3 "Invalid" ;
VAL_ 2558926849 Warn_Sound_SeatBeltStep 0 "Warining Off" 1 "Buzzer Hold" 2 "1st Warning" 3 "2nd Warning" 4 "3rd Warning" 5 "Reserved" 6 "Pre Warning" 7 "Invalid" ;
VAL_ 2558926849 Warn_Sound_PopUp 0 "Off" 1 "Red Pop-up(Collision)" 2 "Red Pop-up" 3 "Yellow Pop-up" 4 "White(Alarm) Pop-up" 5 "White(Feedback) Pop-up" 6 "Reserved" 7 "Invalid" ;
VAL_ 2558926849 Warn_Sound_TikTok 0 "Off" 1 "Tick" 2 "Tock" 3 "Invalid" ;
VAL_ 2558926849 Warn_Sound_SBW_P 0 "Off" 1 "SBW P" 2 "Reserved" 3 "Invalid" ;
VAL_ 2558926849 Warn_Sound_ETC 0 "Off" 1 "Press_brake_to_start" 2 "Press_clutch_to_start" 3 "starrt_in_P_or_N" 4 "start_in_P" 5 "smart_cruise_mode" 6 "cruise_mode" 7 "step_on_brake_to_shift" 8 "park_only_possible_stop" 9 "move_lever_to_the_right" 10 "Align_handle" 11 "Reserved" 12 "fill_washer_fluid" 13 "door_open" 14 "hood_open" 15 "sunroof_open" 16 "window_open" 17 "door_hood_open" 18 "windows_sunroof_open" 19 "Press_brake" 20 "volume1" 21 "volume2" 22 "volume3" 23 "WPCWarning" 24 "PA_Mode_Select_Forward" 25 "PA_Searching_Auto_Scan" 26 "PA_Complete_Auto_Scan" 27 "PA_Reduce_Speed" 28 "PA_Shift_D" 29 "PA_Shift_R" 30 "PA_Exit_Canceled" 31 "PA_Complete" 32 "PA_Watch_for_Obstacles" 33 "PA_Mode_Select" 34 "PA_Exit_Searching" 35 "PA_Exit_Complete" 36 "PA_Forward_to_Search" 37 "Check_HEV_System" 38 "Charge_Battery" 39 "SMK_Unplug_and_Start" 40 "Check_EV_System" 41 "Reserved" 42 "Reserved" 43 "Reserved" 44 "Reserved" 45 "Reserved" 46 "Reserved" 47 "Reserved" 48 "Reserved" 49 "Reserved" 50 "Reserved" 51 "Reserved" 52 "Reserved" 53 "Reserved" 54 "Reserved" 55 "Reserved" 56 "Reserved" 57 "Reserved" 58 "Reserved" 59 "Reserved" 60 "Reserved" 61 "Reserved" 62 "Reserved" 63 "Invalid" ;
VAL_ 2558926849 Warn_Sound_SeatBelt 0 "Off" 1 "Seat Belt" 2 "Reserved" 3 "Invalid" ;
VAL_ 2558926849 Elec_Sound_VolLevel 0 "Default" 1 "Level1" 2 "Level2" 3 "Level3" 4 "Reserved" 5 "Reserved" 6 "Reserved" 7 "Invalid" ;
VAL_ 2382595073 DATC_FrDrvBlwDis 0 "OFF" 1 "Blank Display" 2 "1 Step" 3 "2 Step" 4 "3 Step" 5 "4 Step" 6 "5 Step" 7 "6 Step" 8 "7 Step" 9 "8 Step" 10 "BLOWER AUTO" 11 "Reserved" 12 "Reserved" 13 "Reserved" 14 "Reserved" 15 "Error Indicator" ;
VAL_ 2382595073 DATC_FrPsBlwDis 0 "OFF" 1 "Blank Display(Blower 단수 미표시, 예)Auto 시)" 2 "1 Step" 3 "2 Step" 4 "3 Step" 5 "4 Step" 6 "5 Step" 7 "6 Step" 8 "7 Step" 9 "8 Step" 10 "BLOWER AUTO" 11 "Reserved" 12 "Reserved" 13 "Reserved" 14 "Reserved" 15 "Error Indicator" ;
VAL_ 2382595073 DATC_AUTOStep 0 "Default" 1 "OFF" 2 "1st & 2nd & 3rd On (3 Step Type)" 3 "1st & 2nd On (3 Step Type)" 4 "1st On (3 Step Type)" 5 "1st & 2nd On (2 Step Type)" 6 "1st On (2 Step Type)" 7 "Reserved" 8 "Reserved" 9 "Reserved" 10 "Reserved" 11 "Reserved" 12 "Reserved" 13 "Reserved" 14 "Reserved" 15 "Error Indicator" ;
VAL_ 2382595073 DATC_IntakeDis 0 "Default" 1 "REC (Fresh off)" 2 "FRE (REC off)" 3 "Error indicator" ;
VAL_ 209 DSAU_SmartCtrl_1h 0 "Default" 1 "Group1" 2 "Group2" 3 "Group3" 4 "Group4" 5 "Group5" 6 "Group6" 7 "Group7" 8 "Group8" 9 "Group9" 10 "General Group" 11 "Unused" 12 "Unused" 13 "Unused" 14 "Unused" 15 "Invalid" ;
VAL_ 209 DSAU_SmartCtrl_2h 0 "Default" 1 "Group1" 2 "Group2" 3 "Group3" 4 "Group4" 5 "Group5" 6 "Group6" 7 "Group7" 8 "Group8" 9 "Group9" 10 "General Group" 11 "Unused" 12 "Unused" 13 "Unused" 14 "Unused" 15 "Invalid" ;
VAL_ 209 DSAU_SmartCtrl_Status 0 "Default" 1 "Start" 2 "Finished" 3 "Stop" 4 "Unused" 5 "Unused" 6 "Unused" 7 "Invalid" ;
VAL_ 1174 Drv_SHVU_SeatOptSta 0 "Init" 1 "Heater only 2step" 2 "Heater only 3step" 3 "Vent only 2step" 4 "Vent only 3step" 5 "Heater and Vent 2step" 6 "Heater and Vent 3step" 7 "Invalid" ;
VAL_ 1174 Drv_SHVU_HtSwHiIndSta 0 "Off(Initial Value)" 1 "On" 2 "Not Used" 3 "Error Indicator" ;
VAL_ 1174 Drv_SHVU_HtSwMidIndSta 0 "Off(Initial Value)" 1 "On" 2 "Not Used" 3 "Error Indicator" ;
VAL_ 1174 Drv_SHVU_HtSwLowIndSta 0 "Off(Initial Value)" 1 "On" 2 "Not Used" 3 "Error Indicator" ;
VAL_ 1174 Drv_SHVU_VntSwHiIndSta 0 "Off(Initial Value)" 1 "On" 2 "Not Used" 3 "Error Indicator" ;
VAL_ 1174 Drv_SHVU_VntSwMidIndSta 0 "Off(Initial Value)" 1 "On" 2 "Not Used" 3 "Error Indicator" ;
VAL_ 1174 Drv_SHVU_VntSwLowIndSta 0 "Off(Initial Value)" 1 "On" 2 "Not Used" 3 "Error Indicator" ;
VAL_ 1174 Drv_SHVU_HtBlcUSMSta 0 "Default" 1 "Normal" 2 "Back 1" 3 "Back 2" 4 "Back 3" 5 "Cush 1" 6 "Cush 2" 7 "Cush 3" 8 "Reserved" 9 "Reserved" 10 "Reserved" 11 "Reserved" 12 "Reserved" 13 "Reserved" 14 "Reserved" 15 "Invalid" ;
VAL_ 1174 Drv_SHVU_SeatHtOperSta 0 "Init" 1 "Unused" 2 "Heater & Vent OFF" 3 "Vent Low" 4 "Vent Mid" 5 "Vent High" 6 "Heater Low" 7 "Heater Mid" 8 "Heater High" 9 "Unused" 10 "Unused" 11 "Unused" 12 "Unused" 13 "Unused" 14 "Unused" 15 "Invalid" ;
VAL_ 1174 Drv_SHVU_SeatOptSta_RHD 0 "Init" 1 "Heater only 2step" 2 "Heater only 3step" 3 "Vent only 2step" 4 "Vent only 3step" 5 "Heater and Vent 2step" 6 "Heater and Vent 3step" 7 "Invalid" ;
VAL_ 1174 Drv_SHVU_SeatHtOperSta_RHD 0 "Init" 1 "Unused" 2 "Heater & Vent OFF" 3 "Vent Low" 4 "Vent Mid" 5 "Vent High" 6 "Heater Low" 7 "Heater Mid" 8 "Heater High" 9 "Unused" 10 "Unused" 11 "Unused" 12 "Unused" 13 "Unused" 14 "Unused" 15 "Invalid" ;
VAL_ 1174 Drv_SHVU_HtSwHiIndSta_RHD 0 "Off(Initial Value)" 1 "On" 2 "Not Used" 3 "Error Indicator" ;
VAL_ 1174 Drv_SHVU_HtSwMidIndSta_RHD 0 "Off(Initial Value)" 1 "On" 2 "Not Used" 3 "Error Indicator" ;
VAL_ 1174 Drv_SHVU_HtSwLowIndSta_RHD 0 "Off(Initial Value)" 1 "On" 2 "Not Used" 3 "Error Indicator" ;
VAL_ 1174 Drv_SHVU_VntSwHiIndSta_RHD 0 "Off(Initial Value)" 1 "On" 2 "Not Used" 3 "Error Indicator" ;
VAL_ 1174 Drv_SHVU_VntSwMidIndSta_RHD 0 "Off(Initial Value)" 1 "On" 2 "Not Used" 3 "Error Indicator" ;
VAL_ 1174 Drv_SHVU_VntSwLowIndSta_RHD 0 "Off(Initial Value)" 1 "On" 2 "Not Used" 3 "Error Indicator" ;
VAL_ 756 FPM_FOBSrch 0 "None" 1 "Search 1 Fob Inside" 2 "Search 2 Fobs Inside" 3 "reserved" ;
VAL_ 2563125505 AMP_WrnPromptMode 0 "Off" 1 "On" 2 "Reserved" 3 "Invalid" ;
VAL_ 2563125505 AMP_SPDIFMute 0 "SPDIF Un-mutef" 1 "SPDIF Mute On" 2 "Unused" 3 "Invalid" ;
VAL_ 2563125505 AMP_Reset 0 "Not used" 1 "Amp_reset" 2 "Reserved" 3 "Invalid" ;
VAL_ 2563125505 AMP_QuietMode 0 "QuietMode Off" 1 "QuietMode On" 2 "Reserved" 3 "Invalid" ;
VAL_ 2563125505 AMP_DSCMode 0 "Off" 1 "On" 2 "unused" 3 "Invaild" ;
VAL_ 2563125505 AMP_RANCMode 0 "RANC Mode On" 1 "RANC Mode Off" 2 "Reserved" 3 "Invalid" ;
VAL_ 2563125505 AMP_CenterpointMode 0 "Off" 1 "On" 2 "unused" 3 "Invalid" ;
VAL_ 2563125505 AMP_QLSMode 0 "QLS OFF" 1 "On Stage" 2 "Audience" 3 "Invalid" ;
VAL_ 2563125505 AMP_VIPMode 0 "VIP OFF" 1 "VIP ON" 2 "Reserved" 3 "Invalid" ;
VAL_ 2563125505 AMP_LiveDynamicMode 0 "Off" 1 "On" 2 "Natural" 3 "Concert" 4 "Reserved" 5 "Reserved" 6 "Reserved" 7 "Invalid" ;
VAL_ 2563125505 AMP_BASSMode 0 "Off" 1 "On" 2 "reserved" 3 "invalid" ;
VAL_ 2563125505 AMP_CabinTalkMode 0 "CabinTalk Off" 1 "CabinTalk On" 2 "Reserved" 3 "Invalid" ;
VAL_ 2563125505 AMP_SiriMode 0 "Siri Mode Off" 1 "Siri Mode On" 2 "Reserved" 3 "Invalid" ;
VAL_ 2563125505 AMP_Mute 0 "Not mute" 1 "mute" 2 "Unsed" 3 "Invalid" ;
VAL_ 2563125505 AMP_AudioMode 0 "Off" 1 "AM" 2 "FM" 3 "Reserved" 4 "XM_SIRIUS" 5 "DMB(South Korea Only)" 6 "Reserved" 7 "Reserved" 8 "Reserved" 9 "Reserved" 10 "Reserved" 11 "Reserved" 12 "Reserved" 13 "Reserved" 14 "Reserved" 15 "HDAudio(2ch)" 16 "CD(CDDA_MP3)" 17 "DVD DD" 18 "DVD DTS" 19 "RSE CD_MP3_VCD" 20 "RSE DD" 21 "RSE DTS" 22 "Reserved" 23 "Reserved" 24 "Reserved" 25 "Reserved" 26 "Reserved" 27 "Reserved" 28 "Reserved" 29 "Reserved" 30 "Reserved" 31 "Reserved" 32 "USB MP3" 33 "BT MP3" 34 "iPod" 35 "AUX" 36 "RSE AUX" 37 "HF(SPDIF)" 38 "MTS(SPDIF)" 39 "MTS(analog)" 40 "ZUNE" 41 "0x29~0xFE:Reserved" 254 "0x29~0xFE:Reserved" 255 "Invalid" ;
VAL_ 2563127041 AMP_MainVolumeSet 0 "0x0x0~0xFD:Main Audio Volume" 253 "0x0x0~0xFD:Main Audio Volume" 254 "Req.amp.VTBF step max" 255 "Invalid" ;
VAL_ 2563127041 AMP_FadeSet 0 "0x0x0~0xFE:Audio Fader" 254 "0x0x0~0xFE:Audio Fader" 255 "Invalid" ;
VAL_ 2563127041 AMP_BassSet 0 "0x0x0~0xFE:Bass tone" 254 "0x0x0~0xFE:Bass tone" 255 "Invalid" ;
VAL_ 2563127041 AMP_MidSet 0 "0x0x0~0xFE:Mid-range tone" 254 "0x0x0~0xFE:Mid-range tone" 255 "Invalid" ;
VAL_ 2563127041 AMP_TrebleSet 0 "0x0x0~0xFE:Treble tone" 254 "0x0x0~0xFE:Treble tone" 255 "Invalid" ;
VAL_ 2563127041 AMP_BalanceSet 0 "0x0x0~0xFE:Audio Balance" 254 "0x0x0~0xFE:Audio Balance" 255 "Invalid" ;
VAL_ 2567325441 AMP_ADASVolumeStep 0 "Off" 1 "Level 1" 2 "Level 2" 3 "Level 3" 4 "Level 4" 5 "Level 5" 6 "Level 6" 7 "Level 7" 8 "Level 8" 9 "Level 9" 10 "Level 10" 11 "Reserved" 12 "Reserved" 13 "Reserved" 14 "Reserved" 15 "Invalid" ;
VAL_ 2567325441 AMP_ADASVolumeFbk 0 "Off" 1 "Level 1" 2 "Level 2" 3 "Level 3" 4 "Level 4" 5 "Level 5" 6 "Level 6" 7 "Level 7" 8 "Level 8" 9 "Level 9" 10 "Level 10" 11 "Reserved" 12 "Reserved" 13 "Reserved" 14 "Reserved" 15 "Invalid" ;
VAL_ 2323817473 C_DrAirSptNValueSet_EC 0 "Default" 1 "Off" 2 "On" 3 "Invalid" ;
VAL_ 2323817473 C_DrCushSoftNValueSet_EC 0 "Default" 1 "Off" 2 "Low" 3 "Mid" 4 "High" 5 "Reserved" 6 "Reserved" 7 "Invalid" ;
VAL_ 2323817473 C_AstAirSptNValueSet_EC 0 "Default" 1 "Off" 2 "On" 3 "Invalid" ;
VAL_ 2323817473 C_DrBackSoftNValueSet_EC 0 "Default" 1 "Off" 2 "Low" 3 "Mid" 4 "High" 5 "Reserved" 6 "Reserved" 7 "Invalid" ;
VAL_ 2323817473 C_AstAirSptModeNValueSet_EC 0 "Default" 1 "Mode 1" 2 "Mode 2" 3 "Mode 3" 4 "Mode 4" 5 "Mode 5" 6 "Reserved" 7 "Invalid" ;
VAL_ 2323817473 C_DrAirSptModeNValueSet_EC 0 "Default" 1 "Mode 1" 2 "Mode 2" 3 "Mode 3" 4 "Mode 4" 5 "Mode 5" 6 "Reserved" 7 "Invalid" ;
VAL_ 2323817473 C_RLAirSptNValueSet_EC 0 "Default" 1 "Off" 2 "On" 3 "Invalid" ;
VAL_ 2323817473 C_AstAirSptStrNValueSet_EC 0 "Default" 1 "Weak" 2 "Normal" 3 "Strong" 4 "Reserved" 5 "Reserved" 6 "Reserved" 7 "Invalid" ;
VAL_ 2323817473 C_AstAirSptTimeNValueSet_EC 0 "Default" 1 "Short" 2 "Normal" 3 "Long" 4 "Reserved" 5 "Reserved" 6 "Reserved" 7 "Invalid" ;
VAL_ 2323817473 C_RRAirSptNValueSet_EC 0 "Default" 1 "Off" 2 "On" 3 "Invalid" ;
VAL_ 2323817473 C_AstCushSoftNValueSet_EC 0 "Default" 1 "Off" 2 "Low" 3 "Mid" 4 "High" 5 "Reserved" 6 "Reserved" 7 "Invalid" ;
VAL_ 2323817473 C_AstBackSoftNValueSet_EC 0 "Default" 1 "Off" 2 "Low" 3 "Mid" 4 "High" 5 "Reserved" 6 "Reserved" 7 "Invalid" ;
VAL_ 2323817473 C_RRFootAirSptNValueSet_EC 0 "Default" 1 "Off" 2 "On" 3 "Invalid" ;
VAL_ 2323817473 C_RLAirSptModeNValueSet_EC 0 "Default" 1 "Mode 1" 2 "Mode 2" 3 "Mode 3" 4 "Mode 4" 5 "Mode 5" 6 "Reserved" 7 "Invalid" ;
VAL_ 2323817473 C_RLSeatHtOperNValueSet_EC 0 "Init" 1 "Unused" 2 "Heater and Ventilation Off" 3 "Vent Low" 4 "Vent Mid" 5 "Vent High" 6 "Heater Low" 7 "Heater Mid" 8 "Heater High" 9 "Reserved" 10 "Reserved" 11 "Reserved" 12 "Reserved" 13 "Reserved" 14 "Reserved" 15 "Invalid" ;
VAL_ 2323817473 C_DrAirSptStrNValueSet_EC 0 "Default" 1 "Weak" 2 "Normal" 3 "Strong" 4 "Reserved" 5 "Reserved" 6 "Reserved" 7 "Invalid" ;
VAL_ 2323817473 C_RRSeatHtOperNValueSet_EC 0 "Init" 1 "Unused" 2 "Heater and Vent off" 3 "Vent Low" 4 "Vent Mid" 5 "Vent High" 6 "Heater Low" 7 "Heater Mid" 8 "Heater High" 9 "Reserved" 10 "Reserved" 11 "Reserved" 12 "Reserved" 13 "Reserved" 14 "Reserved" 15 "Invalid" ;
VAL_ 2323817473 C_RLAirSptStrNValueSet_EC 0 "Default" 1 "Weak" 2 "Normal" 3 "Strong" 4 "Reserved" 5 "Reserved" 6 "Reserved" 7 "Invalid" ;
VAL_ 2323817473 C_RLAirSptTimeNValueSet_EC 0 "Default" 1 "Short" 2 "Normal" 3 "Long" 4 "Reserved" 5 "Reserved" 6 "Reserved" 7 "Invalid" ;
VAL_ 2323817473 C_DrAirSptTimeNValueSet_EC 0 "Default" 1 "Short" 2 "Normal" 3 "Long" 4 "Reserved" 5 "Reserved" 6 "Reserved" 7 "Invalid" ;
VAL_ 2298626561 C_RRLegSupFwdSw_HU 0 "Default" 1 "Off" 2 "On" 3 "Invalid" ;
VAL_ 2298626561 C_RRHrestDnSw_HU 0 "Default" 1 "Off" 2 "On" 3 "Invalid" ;
VAL_ 2298626561 C_RRHrestFwdSw_HU 0 "Default" 1 "Off" 2 "On" 3 "Invalid" ;
VAL_ 2298626561 C_RRHrestBwdSw_HU 0 "Default" 1 "Off" 2 "On" 3 "Invalid" ;
VAL_ 2298626561 C_RRLumbarUpSw_HU 0 "Default" 1 "Off" 2 "On" 3 "Invalid" ;
VAL_ 2298626561 C_RRLumbarMidSw_HU 0 "Default" 1 "Off" 2 "On" 3 "Invalid" ;
VAL_ 2298626561 C_RRLegSupBwdSw_HU 0 "Default" 1 "Off" 2 "On" 3 "Invalid" ;
VAL_ 2298626561 C_RRLumbarLowSw_HU 0 "Default" 1 "Off" 2 "On" 3 "Invalid" ;
VAL_ 2298626561 C_RRLumbarDefSw_HU 0 "Default" 1 "Off" 2 "On" 3 "Invalid" ;
VAL_ 2298626561 C_RRBolsterInfSw_HU 0 "Default" 1 "Off" 2 "On" 3 "Invalid" ;
VAL_ 2298626561 C_RRLegSupUpSw_HU 0 "Default" 1 "Off" 2 "On" 3 "Invalid" ;
VAL_ 2298626561 C_RROneTchNValueSet 0 "Default" 1 "Off" 2 "Return" 3 "Relax" 4 "AV" 5 "Read" 6 "Reserved" 7 "Invalid" ;
VAL_ 2298626561 C_RLOneTchNValueSet 0 "Default" 1 "Off" 2 "Return" 3 "Relax" 4 "Reserved" 5 "Reserved" 6 "Reserved" 7 "Invalid" ;
VAL_ 2298626561 C_RRBolsterDefSw_HU 0 "Default" 1 "Off" 2 "On" 3 "Invalid" ;
VAL_ 2298626561 C_RLRSEUpSw_HU 0 "Default" 1 "Off" 2 "On" 3 "Invalid" ;
VAL_ 2298626561 C_RLRSEDnSw_HU 0 "Default" 1 "Off" 2 "On" 3 "Invalid" ;
VAL_ 2298626561 C_RRRSEUpSw_HU 0 "Default" 1 "Off" 2 "On" 3 "Invalid" ;
VAL_ 2298626561 C_RRLegSupDnSw_HU 0 "Default" 1 "Off" 2 "On" 3 "Invalid" ;
VAL_ 2298626561 C_RRRSEDnSw_HU 0 "Default" 1 "Off" 2 "On" 3 "Invalid" ;
VAL_ 2298626561 C_RRHrestUpSw_HU 0 "Default" 1 "Off" 2 "On" 3 "Invalid" ;
VAL_ 2479157249 HU_TimeSetting 0 "not used" 1 "User Time" 2 "GPS Time" 3 "invalid" ;
VAL_ 2479157249 HU_DisplayMinute 0 "0 minute" 1 "1~59 minute" 2 "1~59 minute" 3 "1~59 minute" 4 "1~59 minute" 5 "1~59 minute" 6 "1~59 minute" 7 "1~59 minute" 8 "1~59 minute" 9 "1~59 minute" 10 "1~59 minute" 11 "1~59 minute" 12 "1~59 minute" 13 "1~59 minute" 14 "1~59 minute" 15 "1~59 minute" 16 "1~59 minute" 17 "1~59 minute" 18 "1~59 minute" 19 "1~59 minute" 20 "1~59 minute" 21 "1~59 minute" 22 "1~59 minute" 23 "1~59 minute" 24 "1~59 minute" 25 "1~59 minute" 26 "1~59 minute" 27 "1~59 minute" 28 "1~59 minute" 29 "1~59 minute" 30 "1~59 minute" 31 "1~59 minute" 32 "1~59 minute" 33 "1~59 minute" 34 "1~59 minute" 35 "1~59 minute" 36 "1~59 minute" 37 "1~59 minute" 38 "1~59 minute" 39 "1~59 minute" 40 "1~59 minute" 41 "1~59 minute" 42 "1~59 minute" 43 "1~59 minute" 44 "1~59 minute" 45 "1~59 minute" 46 "1~59 minute" 47 "1~59 minute" 48 "1~59 minute" 49 "1~59 minute" 50 "1~59 minute" 51 "1~59 minute" 52 "1~59 minute" 53 "1~59 minute" 54 "1~59 minute" 55 "1~59 minute" 56 "1~59 minute" 57 "1~59 minute" 58 "1~59 minute" 59 "1~59 minute" 60 "0x3C~0xFE:RESERVED" 254 "0x3C~0xFE:RESERVED" 255 "Invalid" ;
VAL_ 2479157249 HU_Status 0 "Not used" 1 "Booting Head Unit" 2 "GPS receiving" 3 "Setting Mode" 4 "GPS Unavailable Mode" 5 "No GPS" 6 "RESERVED" 7 "RESERVED" 8 "RESERVED" 9 "RESERVED" 10 "RESERVED" 11 "RESERVED" 12 "RESERVED" 13 "RESERVED" 14 "RESERVED" 15 "Invalid" ;
VAL_ 2479157249 HU_DisplaySecond 0 "0 second" 1 "1~59 second" 2 "1~59 second" 3 "1~59 second" 4 "1~59 second" 5 "1~59 second" 6 "1~59 second" 7 "1~59 second" 8 "1~59 second" 9 "1~59 second" 10 "1~59 second" 11 "1~59 second" 12 "1~59 second" 13 "1~59 second" 14 "1~59 second" 15 "1~59 second" 16 "1~59 second" 17 "1~59 second" 18 "1~59 second" 19 "1~59 second" 20 "1~59 second" 21 "1~59 second" 22 "1~59 second" 23 "1~59 second" 24 "1~59 second" 25 "1~59 second" 26 "1~59 second" 27 "1~59 second" 28 "1~59 second" 29 "1~59 second" 30 "1~59 second" 31 "1~59 second" 32 "1~59 second" 33 "1~59 second" 34 "1~59 second" 35 "1~59 second" 36 "1~59 second" 37 "1~59 second" 38 "1~59 second" 39 "1~59 second" 40 "1~59 second" 41 "1~59 second" 42 "1~59 second" 43 "1~59 second" 44 "1~59 second" 45 "1~59 second" 46 "1~59 second" 47 "1~59 second" 48 "1~59 second" 49 "1~59 second" 50 "1~59 second" 51 "1~59 second" 52 "1~59 second" 53 "1~59 second" 54 "1~59 second" 55 "1~59 second" 56 "1~59 second" 57 "1~59 second" 58 "1~59 second" 59 "1~59 second" 60 "0x3C~0xFE:RESERVED" 254 "0x3C~0xFE:RESERVED" 255 "Invalid" ;
VAL_ 2479157249 HU_DisplayMonth 0 "Not used" 1 "1~12 month" 2 "1~12 month" 3 "1~12 month" 4 "1~12 month" 5 "1~12 month" 6 "1~12 month" 7 "1~12 month" 8 "1~12 month" 9 "1~12 month" 10 "1~12 month" 11 "1~12 month" 12 "1~12 month" 13 "RESERVED" 14 "RESERVED" 15 "Invalid" ;
VAL_ 2479157249 HU_DisplayYear1 0 "19" 1 "20" 2 "21" 3 "invalid" ;
VAL_ 2479157249 HU_DisplayYear2 0 "00 year" 1 "01~99 year" 2 "01~99 year" 3 "01~99 year" 4 "01~99 year" 5 "01~99 year" 6 "01~99 year" 7 "01~99 year" 8 "01~99 year" 9 "01~99 year" 10 "01~99 year" 11 "01~99 year" 12 "01~99 year" 13 "01~99 year" 14 "01~99 year" 15 "01~99 year" 16 "01~99 year" 17 "01~99 year" 18 "01~99 year" 19 "01~99 year" 20 "01~99 year" 21 "01~99 year" 22 "01~99 year" 23 "01~99 year" 24 "01~99 year" 25 "01~99 year" 26 "01~99 year" 27 "01~99 year" 28 "01~99 year" 29 "01~99 year" 30 "01~99 year" 31 "01~99 year" 32 "01~99 year" 33 "01~99 year" 34 "01~99 year" 35 "01~99 year" 36 "01~99 year" 37 "01~99 year" 38 "01~99 year" 39 "01~99 year" 40 "01~99 year" 41 "01~99 year" 42 "01~99 year" 43 "01~99 year" 44 "01~99 year" 45 "01~99 year" 46 "01~99 year" 47 "01~99 year" 48 "01~99 year" 49 "01~99 year" 50 "01~99 year" 51 "01~99 year" 52 "01~99 year" 53 "01~99 year" 54 "01~99 year" 55 "01~99 year" 56 "01~99 year" 57 "01~99 year" 58 "01~99 year" 59 "01~99 year" 60 "01~99 year" 61 "01~99 year" 62 "01~99 year" 63 "01~99 year" 64 "01~99 year" 65 "01~99 year" 66 "01~99 year" 67 "01~99 year" 68 "01~99 year" 69 "01~99 year" 70 "01~99 year" 71 "01~99 year" 72 "01~99 year" 73 "01~99 year" 74 "01~99 year" 75 "01~99 year" 76 "01~99 year" 77 "01~99 year" 78 "01~99 year" 79 "01~99 year" 80 "01~99 year" 81 "01~99 year" 82 "01~99 year" 83 "01~99 year" 84 "01~99 year" 85 "01~99 year" 86 "01~99 year" 87 "01~99 year" 88 "01~99 year" 89 "01~99 year" 90 "01~99 year" 91 "01~99 year" 92 "01~99 year" 93 "01~99 year" 94 "01~99 year" 95 "01~99 year" 96 "01~99 year" 97 "01~99 year" 98 "01~99 year" 99 "01~99 year" 100 "0x64~0xFE:RESERVED" 254 "0x64~0xFE:RESERVED" 255 "Invalid" ;
VAL_ 2479157249 HU_DisplayDay 0 "Not used" 1 "1~31 day" 2 "1~31 day" 3 "1~31 day" 4 "1~31 day" 5 "1~31 day" 6 "1~31 day" 7 "1~31 day" 8 "1~31 day" 9 "1~31 day" 10 "1~31 day" 11 "1~31 day" 12 "1~31 day" 13 "1~31 day" 14 "1~31 day" 15 "1~31 day" 16 "1~31 day" 17 "1~31 day" 18 "1~31 day" 19 "1~31 day" 20 "1~31 day" 21 "1~31 day" 22 "1~31 day" 23 "1~31 day" 24 "1~31 day" 25 "1~31 day" 26 "1~31 day" 27 "1~31 day" 28 "1~31 day" 29 "1~31 day" 30 "1~31 day" 31 "1~31 day" 32 "0x20~0xFE:RESERVED" 254 "0x20~0xFE:RESERVED" 255 "Invalid" ;
VAL_ 2479157249 HU_AM_PM_INFO 0 "Not Used" 1 "AM" 2 "PM" 3 "invalid" ;
VAL_ 2479157249 HU_ZeroDetection 0 "Off(Default)" 1 "Zero Detction" 2 "Reserved" 3 "Invalid" ;
VAL_ 2479157249 HU_TimeFormat 0 "Not used" 1 "12Hour" 2 "24Hour" 3 "invalid" ;
VAL_ 2479157249 HU_ComRefresh 0 "Not Used" 1 "Internal Clock None" 2 "Internal Clock Exist" 3 "Invalid" ;
VAL_ 2479157249 HU_ClockInfo 0 "Not Used" 1 "ACLOCK Refresh" 2 "Not Used" 3 "invalid" ;
VAL_ 2479157249 HU_DisplayHour 0 "0 hour" 1 "1~23 hour" 2 "1~23 hour" 3 "1~23 hour" 4 "1~23 hour" 5 "1~23 hour" 6 "1~23 hour" 7 "1~23 hour" 8 "1~23 hour" 9 "1~23 hour" 10 "1~23 hour" 11 "1~23 hour" 12 "1~23 hour" 13 "1~23 hour" 14 "1~23 hour" 15 "1~23 hour" 16 "1~23 hour" 17 "1~23 hour" 18 "1~23 hour" 19 "1~23 hour" 20 "1~23 hour" 21 "1~23 hour" 22 "1~23 hour" 23 "1~23 hour" 24 "0x18~0xFE:RESERVED" 254 "0x18~0xFE:RESERVED" 255 "Invalid" ;
VAL_ 2458168321 C_HCIMSWeightNValueSet 0 "Default" 1 "Under 49.4kg" 2 "49.5~59.4kg" 3 "59.5~69.4kg" 4 "69.5~79.4kg" 5 "79.5~89.4kg" 6 "89.5~99.4kg" 7 "99.5~109.4kg" 8 "109.5~119.4kg" 9 "More than 119.5kg" 10 "Reserved" 11 "Reserved" 12 "Reserved" 13 "Reserved" 14 "Reserved" 15 "Invalid" ;
VAL_ 2458168321 C_HCIMSSitHeightNValueSet 0 "Default" 1 "Tall" 2 "Middle" 3 "Short" 4 "Reserved" 5 "Reserved" 6 "Reserved" 7 "Reserved" 8 "Reserved" 9 "Reserved" 10 "Reserved" 11 "Reserved" 12 "Reserved" 13 "Reserved" 14 "Reserved" 15 "Invalid" ;
VAL_ 2458168321 CF_AVN_RRSeatAUTOHEATNValueSet 0 "Default" 1 "Off" 2 "On" 3 "Invalid" ;
VAL_ 2458168321 CF_AVN_RLSeatAUTOHEATNValueSet 0 "Default" 1 "Off" 2 "On" 3 "Invalid" ;
VAL_ 2458168321 CF_AVN_AstAUTOHEATNValueSet 0 "Default" 1 "Off" 2 "On" 3 "Invalid" ;
VAL_ 2458168321 CF_Avn_DrvAUTOHEATNValueSet 0 "Default" 1 "Off" 2 "On" 3 "Invalid" ;
VAL_ 2458168321 CF_AVN_BodySpprtSet 0 "Default" 1 "Off" 2 "On" 3 "Invalid" ;
VAL_ 2458168321 CF_AVN_EASMAUTOHEATNValueSet 0 "Default" 1 "Off" 2 "On" 3 "Invalid" ;
VAL_ 2458168321 CF_AVN_EDSMAUTOHEATNValueSet 0 "Default" 1 "Off" 2 "On" 3 "Invalid" ;
VAL_ 2458168321 CF_AVN_AntiDRWSYSet 0 "Default" 1 "Off" 2 "On" 3 "Invalid" ;
VAL_ 2458168321 CF_AVN_AirSptTimeNValueSet 0 "Default" 1 "Short" 2 "Normal" 3 "Long" 4 "Reserved" 5 "Reserved" 6 "Reserved" 7 "Invalid" ;
VAL_ 2458168321 CF_AVN_AirSptStrNValue 0 "Default" 1 "Normal" 2 "Intense" 3 "Invalid" ;
VAL_ 2458168321 CF_AVN_SeatDrvModNValueSet 0 "Default" 1 "Off" 2 "On" 3 "Invalid" ;
VAL_ 2458168321 C_HCIMSHeightNvalueSet 0 "Default" 1 "Less than 147.5cm" 2 "147.5~152.4cm" 3 "152.5~157.4cm" 4 "157.5~162.4cm" 5 "162.5~167.4cm" 6 "167.5~172.4cm" 7 "172.5~177.4cm" 8 "177.5~182.4cm" 9 "182.5~187.4cm" 10 "187.5~192.4cm" 11 "192.5~197.4cm" 12 "more than 197.5cm" 13 "Reserved" 14 "Reserved" 15 "Invalid" ;
VAL_ 2458168321 C_SLB_SmartCtrl_NValue 0 "Init" 1 "Disable" 2 "Enable" 3 "Invalid" ;
VAL_ 2458168321 CF_AVN_AntiDRWSYIntvlSet 0 "Default" 1 "Short" 2 "Long" 3 "Reserved" 4 "Reserved" 5 "Reserved" 6 "Reserved" 7 "Invalid" ;
VAL_ 2458168321 CF_AVN_CushSoftNValueSet 0 "Default" 1 "Soft" 2 "Mid" 3 "Hard" 4 "Reserved" 5 "Reserved" 6 "Off" 7 "Invalid" ;
VAL_ 2458168321 C_SmrtSldngDrNValueSet 0 "Default" 1 "Off" 2 "On" 3 "Reserved" 4 "Reserved" 5 "Reserved" 6 "Reserved" 7 "Invalid" ;
VAL_ 2458168321 CF_AVN_TurboPressureUnit 0 "Default" 1 "Psi" 2 "kPa" 3 "bar" 4 "Reserved" 5 "Reserved" 6 "Reserved" 7 "Invalid" ;
VAL_ 2458168321 CF_AVN_CluTorqueUnit 0 "Default" 1 "Nm" 2 "lb_ft" 3 "Invalid" ;
VAL_ 2458168321 AVN_Usm_CluThemeAutoSet 0 "Default" 1 "Off" 2 "On" 3 "Invalid" ;
VAL_ 2458168321 AVN_Usm_CluThemeSta 0 "Default" 1 "Theme A" 2 "Theme B" 3 "Theme C" 4 "Theme D" 5 "Reserved" 6 "Reserved" 7 "Invalid" ;
VAL_ 2458168321 AVN_Usm_CluFuelEconomySet 0 "Default" 1 "Off" 2 "After Ignition" 3 "After Refueling" 4 "Accumulated Fuel Economy" 5 "Reserved" 6 "Reserved" 7 "Invalid" ;
VAL_ 2458168321 CF_AVN_HCIMSButtonCommand 0 "Default" 1 "Health Care IMS Exit" 2 "Detail View" 3 "Move to recommend position" 4 "Current position Analysis" 5 "Move to setting page" 6 "Save view" 7 "IMS1 saved" 8 "IMS2 saved" 9 "Summary view" 10 "Smart IMS On" 11 "Reserved" 12 "Reserved" 13 "Reserved" 14 "Reserved" 15 "Invalid" ;
VAL_ 1251 IAU_EsyAcsProfileID 0 "Default" 1 "Profile 1" 2 "Profile 2" 3 "Guest" ;
VAL_ 1251 IAU_SmrtPhnID 0 "None" 1 "ID1" 2 "ID2" 3 "ID3" 4 "ID4" 5 "ID5" 6 "ID6" 7 "ID7" 8 "ID8" 9 "Reseved" 10 "Reseved" 11 "Reseved" 12 "Reseved" 13 "Reseved" 14 "Reseved" 15 "Reseved" ;
VAL_ 1251 IAU_SmrtPhnCmd 0 "None" 1 "Reserved" 2 "Reserved" 3 "Reserved" 4 "Reserved" 5 "Reserved" 6 "Reserved" 7 "Tele Cranking Stop" 8 "Reserved" 9 "Forward (RSPA)" 10 "Backward/Parking (RSPA)" 11 "Pause (RSPA)" 12 "PL Lft Out" 13 "PL Rt Out" 14 "Reserved" 15 "Reserved" ;
VAL_ 1251 IAU_Fob_UWBRdy 0 "Default" 1 "Ready" 2 "Not Used" 3 "Invalid" ;
VAL_ 1251 IAUwFPM_ISK_LearningReq 0 "Default" 1 "Start with PSK #1" 2 "Start with PSK #2" 3 "Start with PSK #3" 4 "Start with PSK #4" 5 "Start with PSK #5" 6 "Stop" 7 "Neutral" 8 "Reserved" 9 "Reserved" 10 "Reserved" 11 "Reserved" 12 "Reserved" 13 "Reserved" 14 "Reserved" 15 "Invalid" ;
VAL_ 1251 IAU2FPM_ISKLearnFdbck 0 "Default" 1 "Positive" 2 "Negative" 3 "Invalid" ;
VAL_ 1167 Bat_dischrg 0 "Flag OFF" 1 "Flag ON" ;
VAL_ 1167 Batt_SoCWarningValue 0 "0x0x0~0x64:0 ~ 100%" 100 "0x0x0~0x64:0 ~ 100%" 101 "0x65~0xFE:Reserved" 254 "0x65~0xFE:Reserved" 255 "Invalid" ;
VAL_ 1167 C_StrgWhlHeatingOpt 0 "Not Applied" 1 "Applied(steering wheel applied)" 2 "Reserved" 3 "Invalid" ;
VAL_ 1167 C_StrgWhlHeatingSWInf 0 "Default" 1 "1step opt(On/Off)" 2 "2step opt(step1,step2,Off)" 3 "Invalid" ;
VAL_ 1167 ICU_BattAutoCutPreWrng 0 "No Warning" 1 "Warning" 2 "Not Used" 3 "Invalid" ;
VAL_ 1167 IGN_AutoOff_WarnSta 0 "No Warning" 1 "Power Off Warning" 2 "Reserved" 3 "Error Indicator" ;
VAL_ 1171 RLPSM_SWVerMajor1 0 "0x0x0~0x7F:ASCII Code Value (HEX)" 127 "0x0x0~0x7F:ASCII Code Value (HEX)" ;
VAL_ 1171 RLPSM_SWVerMinor2 0 "0x0x0~0x7F:ASCII Code Value (HEX)" 127 "0x0x0~0x7F:ASCII Code Value (HEX)" ;
VAL_ 1171 RLPSM_RLTiltPosition 0 "0x0x00~0xFE:POSITION" 254 "0x0x00~0xFE:POSITION" 255 "invalid" ;
VAL_ 1171 RLPSM_RLLegRestPosition 0 "0x0x00~0xFE:POSITION" 254 "0x0x00~0xFE:POSITION" 255 "invalid" ;
VAL_ 1171 RLPSM_RLLegRestSlidePosition 0 "0x0x00~0xFE:POSITION" 254 "0x0x00~0xFE:POSITION" 255 "invalid" ;
VAL_ 1171 RLPSM_SWVerMinor1 0 "0x0x0~0x7F:ASCII Code Value (HEX)" 127 "0x0x0~0x7F:ASCII Code Value (HEX)" ;
VAL_ 191 RL_SHVU_DTCdisplay 0 "DTC is not exist(Fail is not exist)" 1 "IGN2 Fuse Open Detection" 2 "Switch Input Detection at Same Time" 3 "NTC/Heating wire Open Detection" 4 "NTC+/NTC- Terminal Short Detection" 5 "NTC+/Heater+ Terminal Short Detection" 6 "NTC+/Heater-, Heater+/Heater-, Heater+/NTC- Terminal Short Detection" 7 "NTC+/Heater- Wiring Short Detection" 8 "NTC+/Heater-, Heater+/Heater-, Heater+/NTC- Wiring Short Detection" 9 "Target Temperature Dissatisfied" 10 "Blower+/Blower- Short, Blower+/Blower Speed, Blower-/Blower Speed Wiring Short Detection" 11 "Blower+/Blower RPM, Blower-/Blower RPM, Blower Speed/Blower RPM Short Detection" 12 "Blower+, Blower-, Blower Speed Signal open Detection" 13 "Blower RPM signal Open Detection" 14 "0xE~0xFD:Unused" 253 "0xE~0xFD:Unused" 254 "No Display" 255 "Invalid" ;
VAL_ 191 RL_SHVU_DiagMode 0 "Default" 1 "DTC Mode" 2 "Normal Mode" 3 "Invalid" ;
VAL_ 1172 RRPSM_SWVerMajor1 0 "0x0x0~0x7F:ASCII Code Value (HEX)" 127 "0x0x0~0x7F:ASCII Code Value (HEX)" ;
VAL_ 1172 RRPSM_SWVerMinor2 0 "0x0x0~0x7F:ASCII Code Value (HEX)" 127 "0x0x0~0x7F:ASCII Code Value (HEX)" ;
VAL_ 1172 RRPSM_SWVerMinor1 0 "0x0x0~0x7F:ASCII Code Value (HEX)" 127 "0x0x0~0x7F:ASCII Code Value (HEX)" ;
VAL_ 208 RR_SHVU_DTCdisplay 0 "DTC is not exist(Fail is not exist)" 1 "IGN2 Fuse Open Detection" 2 "Switch Input Detection at Same Time" 3 "NTC/Heating wire Open Detection" 4 "NTC+/NTC- Terminal Short Detection" 5 "NTC+/Heater+ Terminal Short Detection" 6 "NTC+/Heater-, Heater+/Heater-, Heater+/NTC- Terminal Short Detection" 7 "NTC+/Heater- Wiring Short Detection" 8 "NTC+/Heater-, Heater+/Heater-, Heater+/NTC- Wiring Short Detection" 9 "Target Temperature Dissatisfied" 10 "Blower+/Blower- Short, Blower+/Blower Speed, Blower-/Blower Speed Wiring Short Detection" 11 "Blower+/Blower RPM, Blower-/Blower RPM, Blower Speed/Blower RPM Short Detection" 12 "Blower+, Blower-, Blower Speed Signal open Detection" 13 "Blower RPM signal Open Detection" 14 "0xE~0xFD:Unused" 253 "0xE~0xFD:Unused" 254 "No Display" 255 "Invalid" ;
VAL_ 208 RR_SHVU_DiagMode 0 "Default" 1 "DTC Mode" 2 "Normal Mode" 3 "Invalid" ;
VAL_ 761 AST_CrashMRActAlarm 0 "Off" 1 "On" 2 "Not Used" 3 "Error Indicator" ;
VAL_ 761 PwrDRBuzzerOut_AST 0 "OFF" 1 "Open" 2 "Close" 3 "Warning" ;
VAL_ 761 IMS_OSMirPlayBackSta_RH 0 "Stop" 1 "Play 1" 2 "Play 2" 3 "Play 3" 4 "Smart IMS" 5 "Profile 1" 6 "Profile 2" 7 "Guest" 8 "RESERVED" 9 "RESERVED" 10 "RESERVED" 11 "RESERVED" 12 "RESERVED" 13 "RESERVED" 14 "RESERVED" 15 "Error Indicator" ;
VAL_ 761 Mirror_RHVerPosVal 251 "Reserved" 252 "Reserved" 253 "Reserved" 254 "Reserved" 255 "Error Indicator" ;
VAL_ 761 Mirror_RHHorPosVal 251 "Reserved" 252 "Reserved" 253 "Reserved" 254 "Reserved" 255 "Error Indicator" ;
VAL_ 761 SBCM_AST_DiagSta 0 "Default" 1 "Normal Operation" 2 "AST Indicator Circuit Failure" 3 "Invalid" ;
VAL_ 758 SBCM_PsvDrLkReq 0 "None" 1 "Lock" 2 "Passive Trunk Lock" 3 "Not Used" ;
VAL_ 758 USM_DrvGhostDoorSta 0 "Default" 1 "Off" 2 "On" 3 "Invalid" ;
VAL_ 758 DRV_CrashMRActAlarm 0 "Off" 1 "On" 2 "Not Used" 3 "Error Indicator" ;
VAL_ 758 IMS_OSMirPlayBackSta_LH 0 "Stop" 1 "Play 1" 2 "Play 2" 3 "Play 3" 4 "SmartIMS" 5 "Profile 1" 6 "Profile 2" 7 "Guest" 8 "RESERVED" 9 "RESERVED" 10 "RESERVED" 11 "RESERVED" 12 "RESERVED" 13 "RESERVED" 14 "RESERVED" 15 "Error Indicator" ;
VAL_ 758 ECMMRR_PLUS 0 "0x0x0~0x7D:0~1.25 V" 125 "0x0x0~0x7D:0~1.25 V" 126 "0x7E~0xFE:Reserved" 254 "0x7E~0xFE:Reserved" 255 "Invalid" ;
VAL_ 758 Mirror_LHVerPosVal 251 "Reserved" 252 "Reserved" 253 "Reserved" 254 "Reserved" 255 "Error Indicator" ;
VAL_ 758 Mirror_LHHorPosVal 251 "Reserved" 252 "Reserved" 253 "Reserved" 254 "Reserved" 255 "Error Indicator" ;
VAL_ 758 SBCM_DRV_DiagSta 0 "Default" 1 "Normal Operation" 2 "DRV Indicator Circuit Failure" 3 "Invalid" ;
VAL_ 763 PwrDRBuzzerOut_DRV 0 "OFF" 1 "Open" 2 "Close" 3 "Warning" ;
VAL_ 759 RL_CrashMRActAlarm 0 "Off" 1 "On" 2 "Not Used" 3 "Error Indicator" ;
VAL_ 759 PwrDRBuzzerOut_RL 0 "OFF" 1 "Open" 2 "Close" 3 "Warning" ;
VAL_ 760 RR_CrashMRActAlarm 0 "Off" 1 "On" 2 "Not Used" 3 "Error Indicator" ;
VAL_ 760 PwrDRBuzzerOut_RR 0 "OFF" 1 "Open" 2 "Close" 3 "Warning" ;
